VERSION ""

NS_ :

BS_:

BU_:

BO_ 2365402622 EJM5: 8 Vector__XXX
 SG_ Joystick5Button13PressedStatus : 62|2@1+ (1,0) [0|3] "" Vector__XXX
 SG_ Joystick5Button14PressedStatus : 60|2@1+ (1,0) [0|3] "" Vector__XXX
 SG_ Joystick5Button15PressedStatus : 58|2@1+ (1,0) [0|3] "" Vector__XXX
 SG_ Joystick5Button16PressedStatus : 56|2@1+ (1,0) [0|3] "" Vector__XXX
 SG_ Joystick5GripXAxisPosition : 6|10@1+ (0.1,0) [0|102] "%" Vector__XXX
 SG_ Joystick5GripYAxisPosition : 22|10@1+ (0.1,0) [0|102] "%" Vector__XXX
 SG_ Joystick5ThetaAxisPosition : 38|10@1+ (0.1,0) [0|102] "%" Vector__XXX
 SG_ Jst5GpYAxsLvFwdPstvPstStts : 20|2@1+ (1,0) [0|3] "" Vector__XXX
 SG_ Jst5TtAxsCtCwsNtvPstStts : 34|2@1+ (1,0) [0|3] "" Vector__XXX
 SG_ Jstk5GrpXAxsDtntPstnStts : 54|2@1+ (1,0) [0|3] "" Vector__XXX
 SG_ Jstk5GrpXAxsLvrLftNgtvPstnStts : 2|2@1+ (1,0) [0|3] "" Vector__XXX
 SG_ Jstk5GrpXAxsLvrRghtPstvPstnStts : 4|2@1+ (1,0) [0|3] "" Vector__XXX
 SG_ Jstk5GrpXAxsNtrlPstnStts : 0|2@1+ (1,0) [0|3] "" Vector__XXX
 SG_ Jstk5GrpYAxsDtntPstnStts : 52|2@1+ (1,0) [0|3] "" Vector__XXX
 SG_ Jstk5GrpYAxsLvrBkNgtvPstnStts : 18|2@1+ (1,0) [0|3] "" Vector__XXX
 SG_ Jstk5GrpYAxsNtrlPstnStts : 16|2@1+ (1,0) [0|3] "" Vector__XXX
 SG_ Jstk5ThtAxsClkwsPstvPstnStts : 36|2@1+ (1,0) [0|3] "" Vector__XXX
 SG_ Jstk5ThtAxsDtntPstnStts : 50|2@1+ (1,0) [0|3] "" Vector__XXX
 SG_ Jstk5ThtAxsNtrlPstnStts : 32|2@1+ (1,0) [0|3] "" Vector__XXX

BO_ 2365402878 BJM5: 8 Vector__XXX
 SG_ Joystick5Button10PressedStatus : 60|2@1+ (1,0) [0|3] "" Vector__XXX
 SG_ Joystick5Button11PressedStatus : 58|2@1+ (1,0) [0|3] "" Vector__XXX
 SG_ Joystick5Button12PressedStatus : 56|2@1+ (1,0) [0|3] "" Vector__XXX
 SG_ Joystick5Button1PressedStatus : 46|2@1+ (1,0) [0|3] "" Vector__XXX
 SG_ Joystick5Button2PressedStatus : 44|2@1+ (1,0) [0|3] "" Vector__XXX
 SG_ Joystick5Button3PressedStatus : 42|2@1+ (1,0) [0|3] "" Vector__XXX
 SG_ Joystick5Button4PressedStatus : 40|2@1+ (1,0) [0|3] "" Vector__XXX
 SG_ Joystick5Button5PressedStatus : 54|2@1+ (1,0) [0|3] "" Vector__XXX
 SG_ Joystick5Button6PressedStatus : 52|2@1+ (1,0) [0|3] "" Vector__XXX
 SG_ Joystick5Button7PressedStatus : 50|2@1+ (1,0) [0|3] "" Vector__XXX
 SG_ Joystick5Button8PressedStatus : 48|2@1+ (1,0) [0|3] "" Vector__XXX
 SG_ Joystick5Button9PressedStatus : 62|2@1+ (1,0) [0|3] "" Vector__XXX
 SG_ Joystick5XAxisPosition : 6|10@1+ (0.1,0) [0|102] "%" Vector__XXX
 SG_ Joystick5YAxisPosition : 22|10@1+ (0.1,0) [0|102] "%" Vector__XXX
 SG_ Jstk5XAxsDtntPstnStts : 38|2@1+ (1,0) [0|3] "" Vector__XXX
 SG_ Jstk5XAxsLvrLftNgtvPstnStts : 2|2@1+ (1,0) [0|3] "" Vector__XXX
 SG_ Jstk5XAxsLvrRghtPstvPstnStts : 4|2@1+ (1,0) [0|3] "" Vector__XXX
 SG_ Jstk5XAxsNtrlPstnStts : 0|2@1+ (1,0) [0|3] "" Vector__XXX
 SG_ Jstk5YAxsDtntPstnStts : 36|2@1+ (1,0) [0|3] "" Vector__XXX
 SG_ Jstk5YAxsLvrBkNgtvPstnStts : 18|2@1+ (1,0) [0|3] "" Vector__XXX
 SG_ Jstk5YAxsLvrFrwrdPstvPstnStts : 20|2@1+ (1,0) [0|3] "" Vector__XXX
 SG_ Jstk5YAxsNtrlPstnStts : 16|2@1+ (1,0) [0|3] "" Vector__XXX

BO_ 2365403134 EJM4: 8 Vector__XXX
 SG_ Joystick4Button13PressedStatus : 62|2@1+ (1,0) [0|3] "" Vector__XXX
 SG_ Joystick4Button14PressedStatus : 60|2@1+ (1,0) [0|3] "" Vector__XXX
 SG_ Joystick4Button15PressedStatus : 58|2@1+ (1,0) [0|3] "" Vector__XXX
 SG_ Joystick4Button16PressedStatus : 56|2@1+ (1,0) [0|3] "" Vector__XXX
 SG_ Joystick4GripXAxisPosition : 6|10@1+ (0.1,0) [0|102] "%" Vector__XXX
 SG_ Joystick4GripYAxisPosition : 22|10@1+ (0.1,0) [0|102] "%" Vector__XXX
 SG_ Joystick4ThetaAxisPosition : 38|10@1+ (0.1,0) [0|102] "%" Vector__XXX
 SG_ Jst4GpYAxsLvFwdPstvPstStts : 20|2@1+ (1,0) [0|3] "" Vector__XXX
 SG_ Jst4TtAxsCtCwsNtvPstStts : 34|2@1+ (1,0) [0|3] "" Vector__XXX
 SG_ Jstk4GrpXAxsDtntPstnStts : 54|2@1+ (1,0) [0|3] "" Vector__XXX
 SG_ Jstk4GrpXAxsLvrLftNgtvPstnStts : 2|2@1+ (1,0) [0|3] "" Vector__XXX
 SG_ Jstk4GrpXAxsLvrRghtPstvPstnStts : 4|2@1+ (1,0) [0|3] "" Vector__XXX
 SG_ Jstk4GrpXAxsNtrlPstnStts : 0|2@1+ (1,0) [0|3] "" Vector__XXX
 SG_ Jstk4GrpYAxsDtntPstnStts : 52|2@1+ (1,0) [0|3] "" Vector__XXX
 SG_ Jstk4GrpYAxsLvrBkNgtvPstnStts : 18|2@1+ (1,0) [0|3] "" Vector__XXX
 SG_ Jstk4GrpYAxsNtrlPstnStts : 16|2@1+ (1,0) [0|3] "" Vector__XXX
 SG_ Jstk4ThtAxsClkwsPstvPstnStts : 36|2@1+ (1,0) [0|3] "" Vector__XXX
 SG_ Jstk4ThtAxsDtntPstnStts : 50|2@1+ (1,0) [0|3] "" Vector__XXX
 SG_ Jstk4ThtAxsNtrlPstnStts : 32|2@1+ (1,0) [0|3] "" Vector__XXX

BO_ 2365403390 BJM4: 8 Vector__XXX
 SG_ Joystick4Button10PressedStatus : 60|2@1+ (1,0) [0|3] "" Vector__XXX
 SG_ Joystick4Button11PressedStatus : 58|2@1+ (1,0) [0|3] "" Vector__XXX
 SG_ Joystick4Button12PressedStatus : 56|2@1+ (1,0) [0|3] "" Vector__XXX
 SG_ Joystick4Button1PressedStatus : 46|2@1+ (1,0) [0|3] "" Vector__XXX
 SG_ Joystick4Button2PressedStatus : 44|2@1+ (1,0) [0|3] "" Vector__XXX
 SG_ Joystick4Button3PressedStatus : 42|2@1+ (1,0) [0|3] "" Vector__XXX
 SG_ Joystick4Button4PressedStatus : 40|2@1+ (1,0) [0|3] "" Vector__XXX
 SG_ Joystick4Button5PressedStatus : 54|2@1+ (1,0) [0|3] "" Vector__XXX
 SG_ Joystick4Button6PressedStatus : 52|2@1+ (1,0) [0|3] "" Vector__XXX
 SG_ Joystick4Button7PressedStatus : 50|2@1+ (1,0) [0|3] "" Vector__XXX
 SG_ Joystick4Button8PressedStatus : 48|2@1+ (1,0) [0|3] "" Vector__XXX
 SG_ Joystick4Button9PressedStatus : 62|2@1+ (1,0) [0|3] "" Vector__XXX
 SG_ Joystick4XAxisPosition : 6|10@1+ (0.1,0) [0|102] "%" Vector__XXX
 SG_ Joystick4YAxisPosition : 22|10@1+ (0.1,0) [0|102] "%" Vector__XXX
 SG_ Jstk4XAxsDtntPstnStts : 38|2@1+ (1,0) [0|3] "" Vector__XXX
 SG_ Jstk4XAxsLvrLftNgtvPstnStts : 2|2@1+ (1,0) [0|3] "" Vector__XXX
 SG_ Jstk4XAxsLvrRghtPstvPstnStts : 4|2@1+ (1,0) [0|3] "" Vector__XXX
 SG_ Jstk4XAxsNtrlPstnStts : 0|2@1+ (1,0) [0|3] "" Vector__XXX
 SG_ Jstk4YAxsDtntPstnStts : 36|2@1+ (1,0) [0|3] "" Vector__XXX
 SG_ Jstk4YAxsLvrBkNgtvPstnStts : 18|2@1+ (1,0) [0|3] "" Vector__XXX
 SG_ Jstk4YAxsLvrFrwrdPstvPstnStts : 20|2@1+ (1,0) [0|3] "" Vector__XXX
 SG_ Jstk4YAxsNtrlPstnStts : 16|2@1+ (1,0) [0|3] "" Vector__XXX

BO_ 2365428478 EOI: 8 Vector__XXX
 SG_ EngineControlledShutdownRequest : 42|2@1+ (1,0) [0|3] "" Vector__XXX
 SG_ EngineCoolantPumpControl : 40|2@1+ (1,0) [0|3] "" Vector__XXX
 SG_ EngineDerateRequest : 56|8@1+ (0.4,0) [0|100] "%" Vector__XXX
 SG_ EngineDesiredTorqueRequest : 48|8@1+ (1,-125) [-125|125] "%" Vector__XXX
 SG_ EngineFuelShutoff1Control : 26|2@1+ (1,0) [0|3] "" Vector__XXX
 SG_ EngineFuelShutoff2Control : 28|2@1+ (1,0) [0|3] "" Vector__XXX
 SG_ EngineFuelShutoffVentControl : 24|2@1+ (1,0) [0|3] "" Vector__XXX
 SG_ EngineOilPreheaterControl : 34|2@1+ (1,0) [0|3] "" Vector__XXX
 SG_ EngineOilPrimingPumpControl : 32|2@1+ (1,0) [0|3] "" Vector__XXX
 SG_ EngineOperatingState : 0|4@1+ (1,0) [0|15] "" Vector__XXX
 SG_ EnginePreHeaterControl : 38|2@1+ (1,0) [0|3] "" Vector__XXX
 SG_ EngineStarterMotorRelayControl : 6|2@1+ (1,0) [0|3] "" Vector__XXX
 SG_ EngnCldAmntElvtdIdlStts : 46|2@1+ (1,0) [0|3] "" Vector__XXX
 SG_ EngnEltrlSstmPwrCnsrvtnCntrl : 36|2@1+ (1,0) [0|3] "" Vector__XXX
 SG_ EngnEmrgnImmdtShtdwnIndtn : 44|2@1+ (1,0) [0|3] "" Vector__XXX
 SG_ EngnFlShtffVlvLkTstCntrl : 30|2@1+ (1,0) [0|3] "" Vector__XXX
 SG_ FuelPumpPrimerControl : 4|2@1+ (1,0) [0|3] "" Vector__XXX
 SG_ TmRmnngnEngnOprtngStt : 8|16@1+ (1,0) [0|64255] "s" Vector__XXX

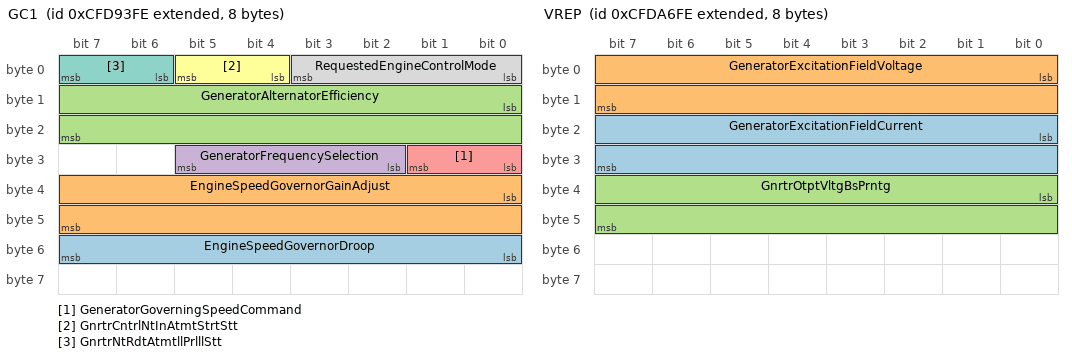
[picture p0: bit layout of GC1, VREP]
BO_ 2365428734 GC1: 8 Vector__XXX
 SG_ EngineSpeedGovernorDroop : 48|8@1+ (0.04,0) [0|10] "%" Vector__XXX
 SG_ EngineSpeedGovernorGainAdjust : 32|16@1+ (1,-32128) [-32128|32127] "count" Vector__XXX
 SG_ GeneratorAlternatorEfficiency : 8|16@1+ (0.0025,0) [0|160.6375] "%" Vector__XXX
 SG_ GeneratorFrequencySelection : 26|4@1+ (1,0) [0|15] "" Vector__XXX
 SG_ GeneratorGoverningSpeedCommand : 24|2@1+ (1,0) [0|3] "" Vector__XXX
 SG_ GnrtrCntrlNtInAtmtStrtStt : 4|2@1+ (1,0) [0|3] "" Vector__XXX
 SG_ GnrtrNtRdtAtmtllPrlllStt : 6|2@1+ (1,0) [0|3] "" Vector__XXX
 SG_ RequestedEngineControlMode : 0|4@1+ (1,0) [0|15] "" Vector__XXX

BO_ 2365433598 VREP: 8 Vector__XXX
 SG_ GeneratorExcitationFieldCurrent : 16|16@1+ (0.05,0) [0|3212.75] "A" Vector__XXX
 SG_ GeneratorExcitationFieldVoltage : 0|16@1+ (0.05,-1606) [-1606|1606.75] "V" Vector__XXX
 SG_ GnrtrOtptVltgBsPrntg : 32|16@1+ (0.1,-100) [-100|6325.5] "%" Vector__XXX

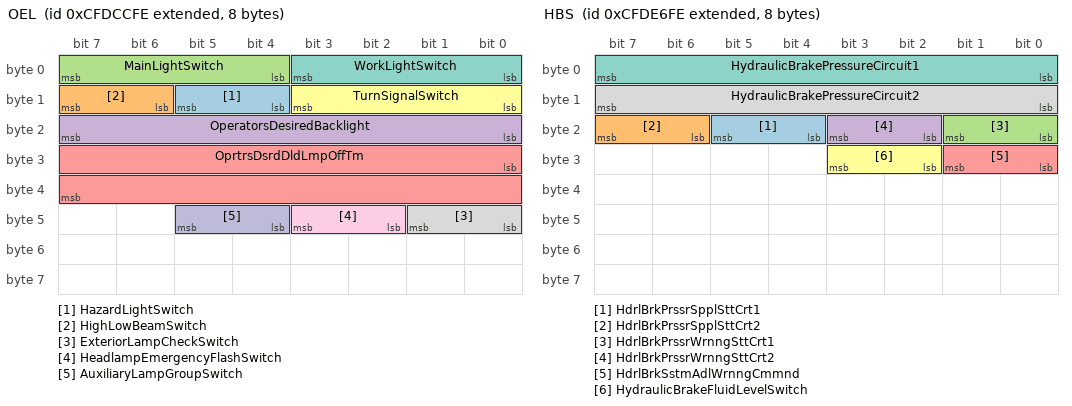
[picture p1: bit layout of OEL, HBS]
BO_ 2365443326 OEL: 8 Vector__XXX
 SG_ HazardLightSwitch : 12|2@1+ (1,0) [0|3] "" Vector__XXX
 SG_ HighLowBeamSwitch : 14|2@1+ (1,0) [0|3] "" Vector__XXX
 SG_ MainLightSwitch : 4|4@1+ (1,0) [0|15] "" Vector__XXX
 SG_ OperatorsDesiredBacklight : 16|8@1+ (0.4,0) [0|100] "%" Vector__XXX
 SG_ OprtrsDsrdDldLmpOffTm : 24|16@1+ (1,0) [0|64255] "s" Vector__XXX
 SG_ TurnSignalSwitch : 8|4@1+ (1,0) [0|15] "" Vector__XXX
 SG_ WorkLightSwitch : 0|4@1+ (1,0) [0|15] "" Vector__XXX
 SG_ ExteriorLampCheckSwitch : 40|2@1+ (1,0) [0|3] "" Vector__XXX
 SG_ HeadlampEmergencyFlashSwitch : 42|2@1+ (1,0) [0|3] "" Vector__XXX
 SG_ AuxiliaryLampGroupSwitch : 44|2@1+ (1,0) [0|3] "" Vector__XXX

BO_ 2365445886 BJM1: 8 Vector__XXX
 SG_ Joystick1Button10PressedStatus : 60|2@1+ (1,0) [0|3] "" Vector__XXX
 SG_ Joystick1Button11PressedStatus : 58|2@1+ (1,0) [0|3] "" Vector__XXX
 SG_ Joystick1Button12PressedStatus : 56|2@1+ (1,0) [0|3] "" Vector__XXX
 SG_ Joystick1Button1PressedStatus : 46|2@1+ (1,0) [0|3] "" Vector__XXX
 SG_ Joystick1Button2PressedStatus : 44|2@1+ (1,0) [0|3] "" Vector__XXX
 SG_ Joystick1Button3PressedStatus : 42|2@1+ (1,0) [0|3] "" Vector__XXX
 SG_ Joystick1Button4PressedStatus : 40|2@1+ (1,0) [0|3] "" Vector__XXX
 SG_ Joystick1Button5PressedStatus : 54|2@1+ (1,0) [0|3] "" Vector__XXX
 SG_ Joystick1Button6PressedStatus : 52|2@1+ (1,0) [0|3] "" Vector__XXX
 SG_ Joystick1Button7PressedStatus : 50|2@1+ (1,0) [0|3] "" Vector__XXX
 SG_ Joystick1Button8PressedStatus : 48|2@1+ (1,0) [0|3] "" Vector__XXX
 SG_ Joystick1Button9PressedStatus : 62|2@1+ (1,0) [0|3] "" Vector__XXX
 SG_ Joystick1XAxisPosition : 6|10@1+ (0.1,0) [0|102] "%" Vector__XXX
 SG_ Joystick1YAxisPosition : 22|10@1+ (0.1,0) [0|102] "%" Vector__XXX
 SG_ Jstk1XAxsDtntPstnStts : 38|2@1+ (1,0) [0|3] "" Vector__XXX
 SG_ Jstk1XAxsLvrLftNgtvPstnStts : 2|2@1+ (1,0) [0|3] "" Vector__XXX
 SG_ Jstk1XAxsLvrRghtPstvPstnStts : 4|2@1+ (1,0) [0|3] "" Vector__XXX
 SG_ Jstk1XAxsNtrlPstnStts : 0|2@1+ (1,0) [0|3] "" Vector__XXX
 SG_ Jstk1YAxsDtntPstnStts : 36|2@1+ (1,0) [0|3] "" Vector__XXX
 SG_ Jstk1YAxsLvrBkNgtvPstnStts : 18|2@1+ (1,0) [0|3] "" Vector__XXX
 SG_ Jstk1YAxsLvrFrwrdPstvPstnStts : 20|2@1+ (1,0) [0|3] "" Vector__XXX
 SG_ Jstk1YAxsNtrlPstnStts : 16|2@1+ (1,0) [0|3] "" Vector__XXX

BO_ 2365446142 EJM1: 8 Vector__XXX
 SG_ Joystick1Button13PressedStatus : 62|2@1+ (1,0) [0|3] "" Vector__XXX
 SG_ Joystick1Button14PressedStatus : 60|2@1+ (1,0) [0|3] "" Vector__XXX
 SG_ Joystick1Button15PressedStatus : 58|2@1+ (1,0) [0|3] "" Vector__XXX
 SG_ Joystick1Button16PressedStatus : 56|2@1+ (1,0) [0|3] "" Vector__XXX
 SG_ Joystick1GripXAxisPosition : 6|10@1+ (0.1,0) [0|102] "%" Vector__XXX
 SG_ Joystick1GripYAxisPosition : 22|10@1+ (0.1,0) [0|102] "%" Vector__XXX
 SG_ Joystick1ThetaAxisPosition : 38|10@1+ (0.1,0) [0|102] "%" Vector__XXX
 SG_ Jst1GpYAxsLvFwdPstvPstStts : 20|2@1+ (1,0) [0|3] "" Vector__XXX
 SG_ Jst1TtAxsCtCwsNtvPstStts : 34|2@1+ (1,0) [0|3] "" Vector__XXX
 SG_ Jstk1GrpXAxsDtntPstnStts : 54|2@1+ (1,0) [0|3] "" Vector__XXX
 SG_ Jstk1GrpXAxsLvrLftNgtvPstnStts : 2|2@1+ (1,0) [0|3] "" Vector__XXX
 SG_ Jstk1GrpXAxsLvrRghtPstvPstnStts : 4|2@1+ (1,0) [0|3] "" Vector__XXX
 SG_ Jstk1GrpXAxsNtrlPstnStts : 0|2@1+ (1,0) [0|3] "" Vector__XXX
 SG_ Jstk1GrpYAxsDtntPstnStts : 52|2@1+ (1,0) [0|3] "" Vector__XXX
 SG_ Jstk1GrpYAxsLvrBkNgtvPstnStts : 18|2@1+ (1,0) [0|3] "" Vector__XXX
 SG_ Jstk1GrpYAxsNtrlPstnStts : 16|2@1+ (1,0) [0|3] "" Vector__XXX
 SG_ Jstk1ThtAxsClkwsPstvPstnStts : 36|2@1+ (1,0) [0|3] "" Vector__XXX
 SG_ Jstk1ThtAxsDtntPstnStts : 50|2@1+ (1,0) [0|3] "" Vector__XXX
 SG_ Jstk1ThtAxsNtrlPstnStts : 32|2@1+ (1,0) [0|3] "" Vector__XXX

BO_ 2365446398 BJM2: 8 Vector__XXX
 SG_ Joystick2Button10PressedStatus : 60|2@1+ (1,0) [0|3] "" Vector__XXX
 SG_ Joystick2Button11PressedStatus : 58|2@1+ (1,0) [0|3] "" Vector__XXX
 SG_ Joystick2Button12PressedStatus : 56|2@1+ (1,0) [0|3] "" Vector__XXX
 SG_ Joystick2Button1PressedStatus : 46|2@1+ (1,0) [0|3] "" Vector__XXX
 SG_ Joystick2Button2PressedStatus : 44|2@1+ (1,0) [0|3] "" Vector__XXX
 SG_ Joystick2Button3PressedStatus : 42|2@1+ (1,0) [0|3] "" Vector__XXX
 SG_ Joystick2Button4PressedStatus : 40|2@1+ (1,0) [0|3] "" Vector__XXX
 SG_ Joystick2Button5PressedStatus : 54|2@1+ (1,0) [0|3] "" Vector__XXX
 SG_ Joystick2Button6PressedStatus : 52|2@1+ (1,0) [0|3] "" Vector__XXX
 SG_ Joystick2Button7PressedStatus : 50|2@1+ (1,0) [0|3] "" Vector__XXX
 SG_ Joystick2Button8PressedStatus : 48|2@1+ (1,0) [0|3] "" Vector__XXX
 SG_ Joystick2Button9PressedStatus : 62|2@1+ (1,0) [0|3] "" Vector__XXX
 SG_ Joystick2XAxisPosition : 6|10@1+ (0.1,0) [0|102] "%" Vector__XXX
 SG_ Joystick2YAxisPosition : 22|10@1+ (0.1,0) [0|102] "%" Vector__XXX
 SG_ Jstk2XAxsDtntPstnStts : 38|2@1+ (1,0) [0|3] "" Vector__XXX
 SG_ Jstk2XAxsLvrLftNgtvPstnStts : 2|2@1+ (1,0) [0|3] "" Vector__XXX
 SG_ Jstk2XAxsLvrRghtPstvPstnStts : 4|2@1+ (1,0) [0|3] "" Vector__XXX
 SG_ Jstk2XAxsNtrlPstnStts : 0|2@1+ (1,0) [0|3] "" Vector__XXX
 SG_ Jstk2YAxsDtntPstnStts : 36|2@1+ (1,0) [0|3] "" Vector__XXX
 SG_ Jstk2YAxsLvrBkNgtvPstnStts : 18|2@1+ (1,0) [0|3] "" Vector__XXX
 SG_ Jstk2YAxsLvrFrwrdPstvPstnStts : 20|2@1+ (1,0) [0|3] "" Vector__XXX
 SG_ Jstk2YAxsNtrlPstnStts : 16|2@1+ (1,0) [0|3] "" Vector__XXX

BO_ 2365446654 EJM2: 8 Vector__XXX
 SG_ Joystick2Button13PressedStatus : 62|2@1+ (1,0) [0|3] "" Vector__XXX
 SG_ Joystick2Button14PressedStatus : 60|2@1+ (1,0) [0|3] "" Vector__XXX
 SG_ Joystick2Button15PressedStatus : 58|2@1+ (1,0) [0|3] "" Vector__XXX
 SG_ Joystick2Button16PressedStatus : 56|2@1+ (1,0) [0|3] "" Vector__XXX
 SG_ Joystick2GripXAxisPosition : 6|10@1+ (0.1,0) [0|102] "%" Vector__XXX
 SG_ Joystick2GripYAxisPosition : 22|10@1+ (0.1,0) [0|102] "%" Vector__XXX
 SG_ Joystick2ThetaAxisPosition : 38|10@1+ (0.1,0) [0|102] "%" Vector__XXX
 SG_ Jst2GpYAxsLvFwdPstvPstStts : 20|2@1+ (1,0) [0|3] "" Vector__XXX
 SG_ Jst2TtAxsCtCwsNtvPstStts : 34|2@1+ (1,0) [0|3] "" Vector__XXX
 SG_ Jstk2GrpXAxsDtntPstnStts : 54|2@1+ (1,0) [0|3] "" Vector__XXX
 SG_ Jstk2GrpXAxsLvrLftNgtvPstnStts : 2|2@1+ (1,0) [0|3] "" Vector__XXX
 SG_ Jstk2GrpXAxsLvrRghtPstvPstnStts : 4|2@1+ (1,0) [0|3] "" Vector__XXX
 SG_ Jstk2GrpXAxsNtrlPstnStts : 0|2@1+ (1,0) [0|3] "" Vector__XXX
 SG_ Jstk2GrpYAxsDtntPstnStts : 52|2@1+ (1,0) [0|3] "" Vector__XXX
 SG_ Jstk2GrpYAxsLvrBkNgtvPstnStts : 18|2@1+ (1,0) [0|3] "" Vector__XXX
 SG_ Jstk2GrpYAxsNtrlPstnStts : 16|2@1+ (1,0) [0|3] "" Vector__XXX
 SG_ Jstk2ThtAxsClkwsPstvPstnStts : 36|2@1+ (1,0) [0|3] "" Vector__XXX
 SG_ Jstk2ThtAxsDtntPstnStts : 50|2@1+ (1,0) [0|3] "" Vector__XXX
 SG_ Jstk2ThtAxsNtrlPstnStts : 32|2@1+ (1,0) [0|3] "" Vector__XXX

BO_ 2365446910 BJM3: 8 Vector__XXX
 SG_ Joystick3Button10PressedStatus : 60|2@1+ (1,0) [0|3] "" Vector__XXX
 SG_ Joystick3Button11PressedStatus : 58|2@1+ (1,0) [0|3] "" Vector__XXX
 SG_ Joystick3Button12PressedStatus : 56|2@1+ (1,0) [0|3] "" Vector__XXX
 SG_ Joystick3Button1PressedStatus : 46|2@1+ (1,0) [0|3] "" Vector__XXX
 SG_ Joystick3Button2PressedStatus : 44|2@1+ (1,0) [0|3] "" Vector__XXX
 SG_ Joystick3Button3PressedStatus : 42|2@1+ (1,0) [0|3] "" Vector__XXX
 SG_ Joystick3Button4PressedStatus : 40|2@1+ (1,0) [0|3] "" Vector__XXX
 SG_ Joystick3Button5PressedStatus : 54|2@1+ (1,0) [0|3] "" Vector__XXX
 SG_ Joystick3Button6PressedStatus : 52|2@1+ (1,0) [0|3] "" Vector__XXX
 SG_ Joystick3Button7PressedStatus : 50|2@1+ (1,0) [0|3] "" Vector__XXX
 SG_ Joystick3Button8PressedStatus : 48|2@1+ (1,0) [0|3] "" Vector__XXX
 SG_ Joystick3Button9PressedStatus : 62|2@1+ (1,0) [0|3] "" Vector__XXX
 SG_ Joystick3XAxisPosition : 6|10@1+ (0.1,0) [0|102] "%" Vector__XXX
 SG_ Joystick3YAxisPosition : 22|10@1+ (0.1,0) [0|102] "%" Vector__XXX
 SG_ Jstk3XAxsDtntPstnStts : 38|2@1+ (1,0) [0|3] "" Vector__XXX
 SG_ Jstk3XAxsLvrLftNgtvPstnStts : 2|2@1+ (1,0) [0|3] "" Vector__XXX
 SG_ Jstk3XAxsLvrRghtPstvPstnStts : 4|2@1+ (1,0) [0|3] "" Vector__XXX
 SG_ Jstk3XAxsNtrlPstnStts : 0|2@1+ (1,0) [0|3] "" Vector__XXX
 SG_ Jstk3YAxsDtntPstnStts : 36|2@1+ (1,0) [0|3] "" Vector__XXX
 SG_ Jstk3YAxsLvrBkNgtvPstnStts : 18|2@1+ (1,0) [0|3] "" Vector__XXX
 SG_ Jstk3YAxsLvrFrwrdPstvPstnStts : 20|2@1+ (1,0) [0|3] "" Vector__XXX
 SG_ Jstk3YAxsNtrlPstnStts : 16|2@1+ (1,0) [0|3] "" Vector__XXX

BO_ 2365447166 EJM3: 8 Vector__XXX
 SG_ Joystick3Button13PressedStatus : 62|2@1+ (1,0) [0|3] "" Vector__XXX
 SG_ Joystick3Button14PressedStatus : 60|2@1+ (1,0) [0|3] "" Vector__XXX
 SG_ Joystick3Button15PressedStatus : 58|2@1+ (1,0) [0|3] "" Vector__XXX
 SG_ Joystick3Button16PressedStatus : 56|2@1+ (1,0) [0|3] "" Vector__XXX
 SG_ Joystick3GripXAxisPosition : 6|10@1+ (0.1,0) [0|102] "%" Vector__XXX
 SG_ Joystick3GripYAxisPosition : 22|10@1+ (0.1,0) [0|102] "%" Vector__XXX
 SG_ Joystick3ThetaAxisPosition : 38|10@1+ (0.1,0) [0|102] "%" Vector__XXX
 SG_ Jst3GpYAxsLvFwdPstvPstStts : 20|2@1+ (1,0) [0|3] "" Vector__XXX
 SG_ Jst3TtAxsCtCwsNtvPstStts : 34|2@1+ (1,0) [0|3] "" Vector__XXX
 SG_ Jstk3GrpXAxsDtntPstnStts : 54|2@1+ (1,0) [0|3] "" Vector__XXX
 SG_ Jstk3GrpXAxsLvrLftNgtvPstnStts : 2|2@1+ (1,0) [0|3] "" Vector__XXX
 SG_ Jstk3GrpXAxsLvrRghtPstvPstnStts : 4|2@1+ (1,0) [0|3] "" Vector__XXX
 SG_ Jstk3GrpXAxsNtrlPstnStts : 0|2@1+ (1,0) [0|3] "" Vector__XXX
 SG_ Jstk3GrpYAxsDtntPstnStts : 52|2@1+ (1,0) [0|3] "" Vector__XXX
 SG_ Jstk3GrpYAxsLvrBkNgtvPstnStts : 18|2@1+ (1,0) [0|3] "" Vector__XXX
 SG_ Jstk3GrpYAxsNtrlPstnStts : 16|2@1+ (1,0) [0|3] "" Vector__XXX
 SG_ Jstk3ThtAxsClkwsPstvPstnStts : 36|2@1+ (1,0) [0|3] "" Vector__XXX
 SG_ Jstk3ThtAxsDtntPstnStts : 50|2@1+ (1,0) [0|3] "" Vector__XXX
 SG_ Jstk3ThtAxsNtrlPstnStts : 32|2@1+ (1,0) [0|3] "" Vector__XXX

BO_ 2365449982 HBS: 8 Vector__XXX
 SG_ HdrlBrkPrssrSpplSttCrt1 : 20|2@1+ (1,0) [0|3] "" Vector__XXX
 SG_ HdrlBrkPrssrSpplSttCrt2 : 22|2@1+ (1,0) [0|3] "" Vector__XXX
 SG_ HdrlBrkPrssrWrnngSttCrt1 : 16|2@1+ (1,0) [0|3] "" Vector__XXX
 SG_ HdrlBrkPrssrWrnngSttCrt2 : 18|2@1+ (1,0) [0|3] "" Vector__XXX
 SG_ HdrlBrkSstmAdlWrnngCmmnd : 24|2@1+ (1,0) [0|3] "" Vector__XXX
 SG_ HydraulicBrakeFluidLevelSwitch : 26|2@1+ (1,0) [0|3] "" Vector__XXX
 SG_ HydraulicBrakePressureCircuit1 : 0|8@1+ (100,0) [0|25000] "kPa" Vector__XXX
 SG_ HydraulicBrakePressureCircuit2 : 8|8@1+ (100,0) [0|25000] "kPa" Vector__XXX

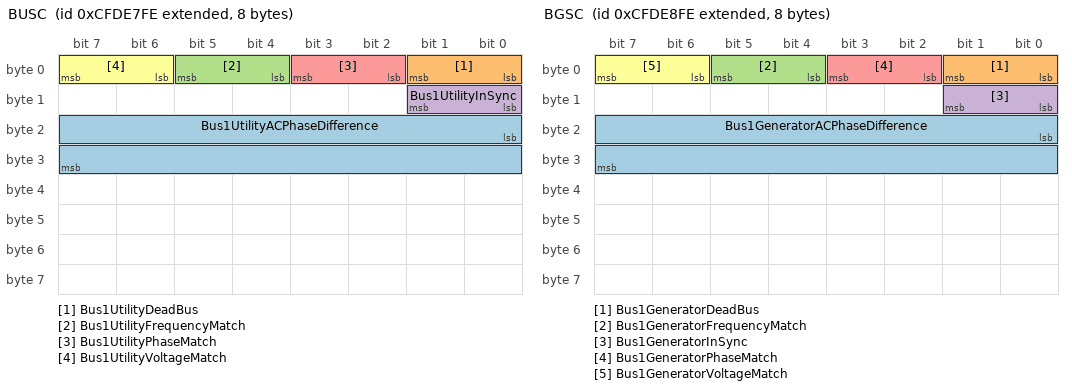
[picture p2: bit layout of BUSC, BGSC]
BO_ 2365450238 BUSC: 8 Vector__XXX
 SG_ Bus1UtilityACPhaseDifference : 16|16@1+ (0.0078125,-200) [-200|301.99] "deg" Vector__XXX
 SG_ Bus1UtilityDeadBus : 0|2@1+ (1,0) [0|3] "" Vector__XXX
 SG_ Bus1UtilityFrequencyMatch : 4|2@1+ (1,0) [0|3] "" Vector__XXX
 SG_ Bus1UtilityInSync : 8|2@1+ (1,0) [0|3] "" Vector__XXX
 SG_ Bus1UtilityPhaseMatch : 2|2@1+ (1,0) [0|3] "" Vector__XXX
 SG_ Bus1UtilityVoltageMatch : 6|2@1+ (1,0) [0|3] "" Vector__XXX

BO_ 2365450494 BGSC: 8 Vector__XXX
 SG_ Bus1GeneratorACPhaseDifference : 16|16@1+ (0.0078125,-200) [-200|301.99] "deg" Vector__XXX
 SG_ Bus1GeneratorDeadBus : 0|2@1+ (1,0) [0|3] "" Vector__XXX
 SG_ Bus1GeneratorFrequencyMatch : 4|2@1+ (1,0) [0|3] "" Vector__XXX
 SG_ Bus1GeneratorInSync : 8|2@1+ (1,0) [0|3] "" Vector__XXX
 SG_ Bus1GeneratorPhaseMatch : 2|2@1+ (1,0) [0|3] "" Vector__XXX
 SG_ Bus1GeneratorVoltageMatch : 6|2@1+ (1,0) [0|3] "" Vector__XXX

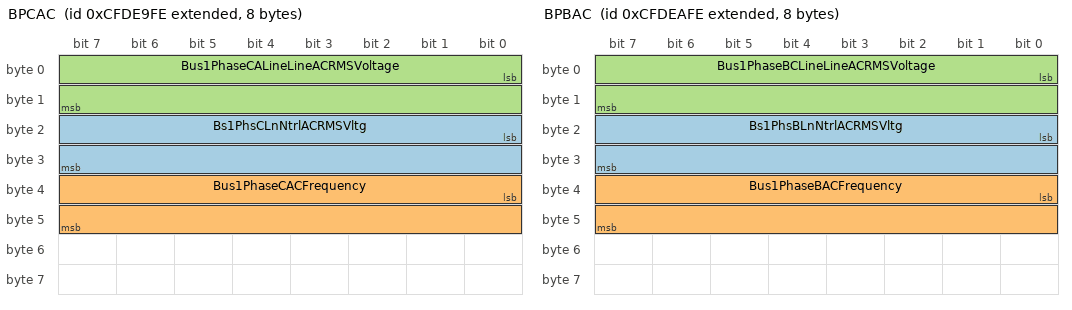
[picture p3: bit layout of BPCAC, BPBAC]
BO_ 2365450750 BPCAC: 8 Vector__XXX
 SG_ Bs1PhsCLnNtrlACRMSVltg : 16|16@1+ (1,0) [0|64255] "V" Vector__XXX
 SG_ Bus1PhaseCACFrequency : 32|16@1+ (0.0078125,0) [0|501.9921875] "Hz" Vector__XXX
 SG_ Bus1PhaseCALineLineACRMSVoltage : 0|16@1+ (1,0) [0|64255] "V" Vector__XXX

BO_ 2365451006 BPBAC: 8 Vector__XXX
 SG_ Bs1PhsBLnNtrlACRMSVltg : 16|16@1+ (1,0) [0|64255] "V" Vector__XXX
 SG_ Bus1PhaseBACFrequency : 32|16@1+ (0.0078125,0) [0|501.9921875] "Hz" Vector__XXX
 SG_ Bus1PhaseBCLineLineACRMSVoltage : 0|16@1+ (1,0) [0|64255] "V" Vector__XXX

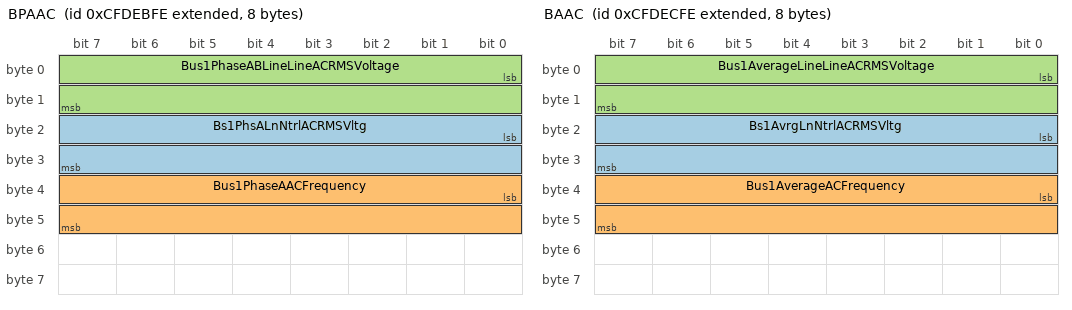
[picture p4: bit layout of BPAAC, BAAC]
BO_ 2365451262 BPAAC: 8 Vector__XXX
 SG_ Bs1PhsALnNtrlACRMSVltg : 16|16@1+ (1,0) [0|64255] "V" Vector__XXX
 SG_ Bus1PhaseAACFrequency : 32|16@1+ (0.0078125,0) [0|501.9921875] "Hz" Vector__XXX
 SG_ Bus1PhaseABLineLineACRMSVoltage : 0|16@1+ (1,0) [0|64255] "V" Vector__XXX

BO_ 2365451518 BAAC: 8 Vector__XXX
 SG_ Bs1AvrgLnNtrlACRMSVltg : 16|16@1+ (1,0) [0|64255] "V" Vector__XXX
 SG_ Bus1AverageACFrequency : 32|16@1+ (0.0078125,0) [0|501.9921875] "Hz" Vector__XXX
 SG_ Bus1AverageLineLineACRMSVoltage : 0|16@1+ (1,0) [0|64255] "V" Vector__XXX

BO_ 2365451774 UTACE: 8 Vector__XXX
 SG_ UtilityTotalkWHoursExport : 0|32@1+ (1,0) [0|4211081215] "kWh" Vector__XXX
 SG_ UtilityTotalkWHoursImport : 32|32@1+ (1,0) [0|4211081215] "kWh" Vector__XXX

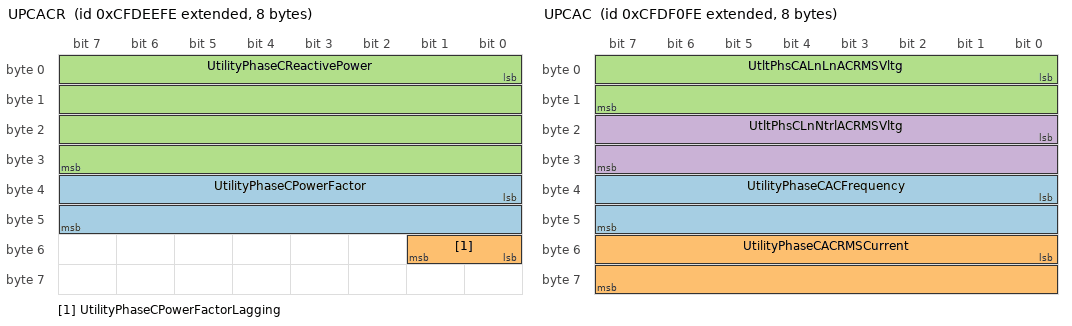
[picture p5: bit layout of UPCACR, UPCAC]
BO_ 2365452030 UPCACR: 8 Vector__XXX
 SG_ UtilityPhaseCPowerFactor : 32|16@1+ (0.00006103515625,-1) [-1|2.921814] "" Vector__XXX
 SG_ UtilityPhaseCPowerFactorLagging : 48|2@1+ (1,0) [0|3] "" Vector__XXX
 SG_ UtilityPhaseCReactivePower : 0|32@1+ (1,-2000000000) [-2000000000|2211081215] "VAr" Vector__XXX

BO_ 2365452286 UPCACP: 8 Vector__XXX
 SG_ UtilityPhaseCApparentPower : 32|32@1+ (1,-2000000000) [-2000000000|2211081215] "VA" Vector__XXX
 SG_ UtilityPhaseCRealPower : 0|32@1+ (1,-2000000000) [-2000000000|2211081215] "W" Vector__XXX

BO_ 2365452542 UPCAC: 8 Vector__XXX
 SG_ UtilityPhaseCACFrequency : 32|16@1+ (0.0078125,0) [0|501.9921875] "Hz" Vector__XXX
 SG_ UtilityPhaseCACRMSCurrent : 48|16@1+ (1,0) [0|64255] "A" Vector__XXX
 SG_ UtltPhsCALnLnACRMSVltg : 0|16@1+ (1,0) [0|64255] "V" Vector__XXX
 SG_ UtltPhsCLnNtrlACRMSVltg : 16|16@1+ (1,0) [0|64255] "V" Vector__XXX

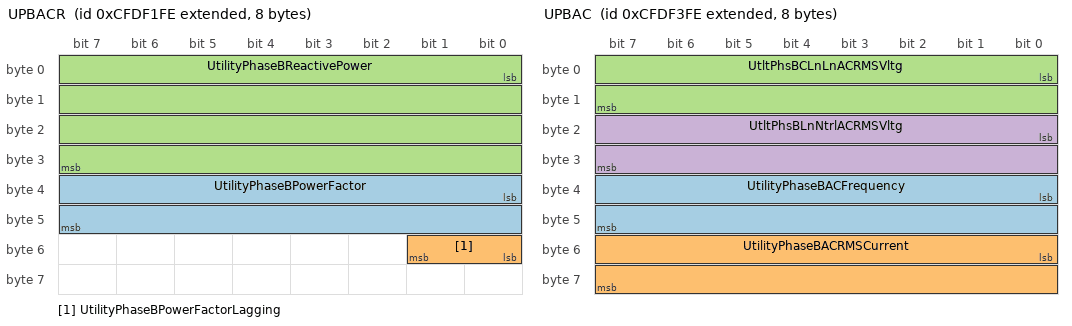
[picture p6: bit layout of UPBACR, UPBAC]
BO_ 2365452798 UPBACR: 8 Vector__XXX
 SG_ UtilityPhaseBPowerFactor : 32|16@1+ (0.00006103515625,-1) [-1|2.921814] "" Vector__XXX
 SG_ UtilityPhaseBPowerFactorLagging : 48|2@1+ (1,0) [0|3] "" Vector__XXX
 SG_ UtilityPhaseBReactivePower : 0|32@1+ (1,-2000000000) [-2000000000|2211081215] "VAr" Vector__XXX

BO_ 2365453054 UPBACP: 8 Vector__XXX
 SG_ UtilityPhaseBApparentPower : 32|32@1+ (1,-2000000000) [-2000000000|2211081215] "VA" Vector__XXX
 SG_ UtilityPhaseBRealPower : 0|32@1+ (1,-2000000000) [-2000000000|2211081215] "W" Vector__XXX

BO_ 2365453310 UPBAC: 8 Vector__XXX
 SG_ UtilityPhaseBACFrequency : 32|16@1+ (0.0078125,0) [0|501.9921875] "Hz" Vector__XXX
 SG_ UtilityPhaseBACRMSCurrent : 48|16@1+ (1,0) [0|64255] "A" Vector__XXX
 SG_ UtltPhsBCLnLnACRMSVltg : 0|16@1+ (1,0) [0|64255] "V" Vector__XXX
 SG_ UtltPhsBLnNtrlACRMSVltg : 16|16@1+ (1,0) [0|64255] "V" Vector__XXX

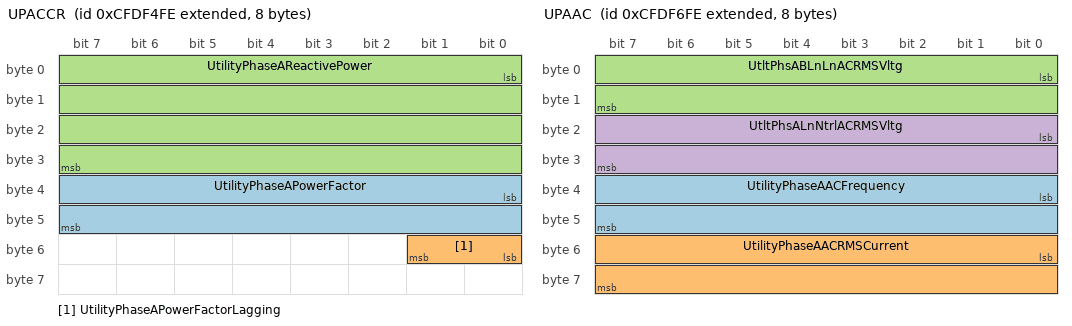
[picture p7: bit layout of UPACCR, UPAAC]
BO_ 2365453566 UPACCR: 8 Vector__XXX
 SG_ UtilityPhaseAPowerFactor : 32|16@1+ (0.00006103515625,-1) [-1|2.921814] "" Vector__XXX
 SG_ UtilityPhaseAPowerFactorLagging : 48|2@1+ (1,0) [0|3] "" Vector__XXX
 SG_ UtilityPhaseAReactivePower : 0|32@1+ (1,-2000000000) [-2000000000|2211081215] "VAr" Vector__XXX

BO_ 2365453822 UPAACP: 8 Vector__XXX
 SG_ UtilityPhaseAApparentPower : 32|32@1+ (1,-2000000000) [-2000000000|2211081215] "VA" Vector__XXX
 SG_ UtilityPhaseARealPower : 0|32@1+ (1,-2000000000) [-2000000000|2211081215] "W" Vector__XXX

BO_ 2365454078 UPAAC: 8 Vector__XXX
 SG_ UtilityPhaseAACFrequency : 32|16@1+ (0.0078125,0) [0|501.9921875] "Hz" Vector__XXX
 SG_ UtilityPhaseAACRMSCurrent : 48|16@1+ (1,0) [0|64255] "A" Vector__XXX
 SG_ UtltPhsABLnLnACRMSVltg : 0|16@1+ (1,0) [0|64255] "V" Vector__XXX
 SG_ UtltPhsALnNtrlACRMSVltg : 16|16@1+ (1,0) [0|64255] "V" Vector__XXX

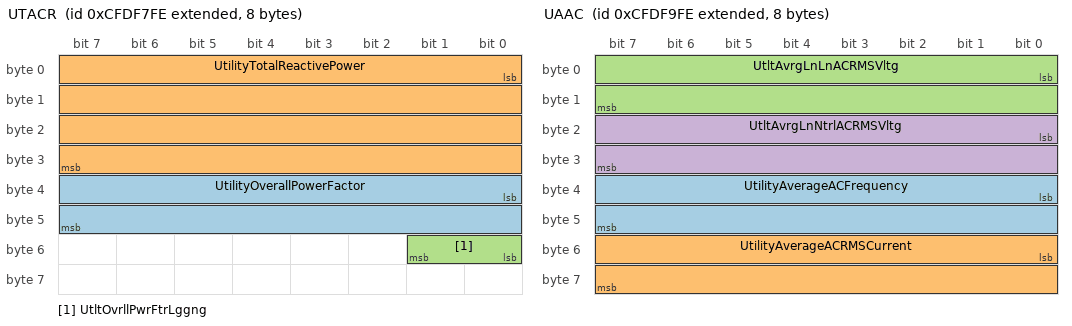
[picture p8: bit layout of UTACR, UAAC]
BO_ 2365454334 UTACR: 8 Vector__XXX
 SG_ UtilityOverallPowerFactor : 32|16@1+ (0.00006103515625,-1) [-1|2.921814] "" Vector__XXX
 SG_ UtilityTotalReactivePower : 0|32@1+ (1,-2000000000) [-2000000000|2211081215] "VAr" Vector__XXX
 SG_ UtltOvrllPwrFtrLggng : 48|2@1+ (1,0) [0|3] "" Vector__XXX

BO_ 2365454590 UTACP: 8 Vector__XXX
 SG_ UtilityTotalApparentPower : 32|32@1+ (1,-2000000000) [-2000000000|2211081215] "VA" Vector__XXX
 SG_ UtilityTotalRealPower : 0|32@1+ (1,-2000000000) [-2000000000|2211081215] "W" Vector__XXX

BO_ 2365454846 UAAC: 8 Vector__XXX
 SG_ UtilityAverageACFrequency : 32|16@1+ (0.0078125,0) [0|501.9921875] "Hz" Vector__XXX
 SG_ UtilityAverageACRMSCurrent : 48|16@1+ (1,0) [0|64255] "A" Vector__XXX
 SG_ UtltAvrgLnLnACRMSVltg : 0|16@1+ (1,0) [0|64255] "V" Vector__XXX
 SG_ UtltAvrgLnNtrlACRMSVltg : 16|16@1+ (1,0) [0|64255] "V" Vector__XXX

BO_ 2365455102 GTACE: 8 Vector__XXX
 SG_ GeneratorTotalkWHoursExport : 0|32@1+ (1,0) [0|4211081215] "kWh" Vector__XXX
 SG_ GeneratorTotalkWHoursImport : 32|32@1+ (1,0) [0|4211081215] "kWh" Vector__XXX

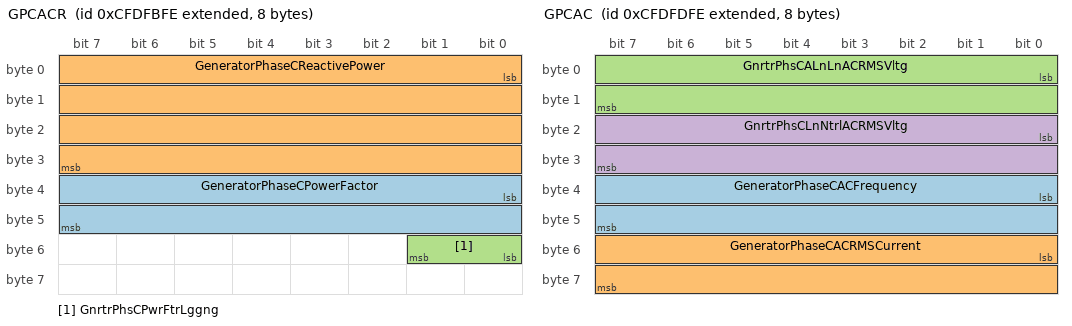
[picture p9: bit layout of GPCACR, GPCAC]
BO_ 2365455358 GPCACR: 8 Vector__XXX
 SG_ GeneratorPhaseCPowerFactor : 32|16@1+ (0.00006103515625,-1) [-1|2.921814] "" Vector__XXX
 SG_ GeneratorPhaseCReactivePower : 0|32@1+ (1,-2000000000) [-2000000000|2211081215] "VAr" Vector__XXX
 SG_ GnrtrPhsCPwrFtrLggng : 48|2@1+ (1,0) [0|3] "" Vector__XXX

BO_ 2365455614 GPCACP: 8 Vector__XXX
 SG_ GeneratorPhaseCApparentPower : 32|32@1+ (1,-2000000000) [-2000000000|2211081215] "VA" Vector__XXX
 SG_ GeneratorPhaseCRealPower : 0|32@1+ (1,-2000000000) [-2000000000|2211081215] "W" Vector__XXX

BO_ 2365455870 GPCAC: 8 Vector__XXX
 SG_ GeneratorPhaseCACFrequency : 32|16@1+ (0.0078125,0) [0|501.9921875] "Hz" Vector__XXX
 SG_ GeneratorPhaseCACRMSCurrent : 48|16@1+ (1,0) [0|64255] "A" Vector__XXX
 SG_ GnrtrPhsCALnLnACRMSVltg : 0|16@1+ (1,0) [0|64255] "V" Vector__XXX
 SG_ GnrtrPhsCLnNtrlACRMSVltg : 16|16@1+ (1,0) [0|64255] "V" Vector__XXX

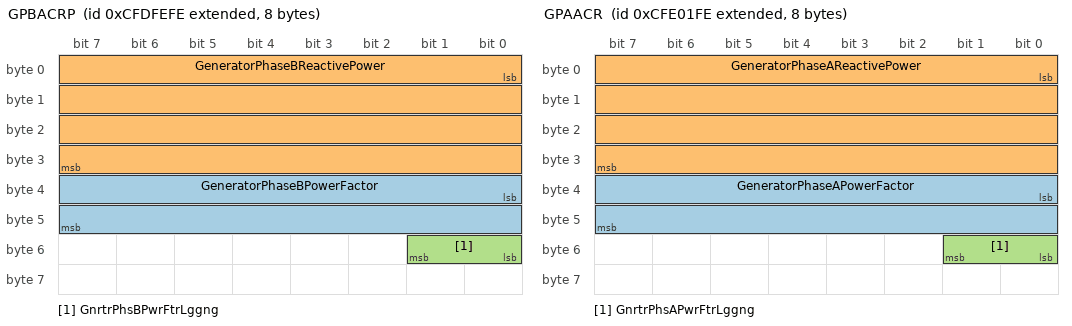
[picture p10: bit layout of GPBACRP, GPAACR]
BO_ 2365456126 GPBACRP: 8 Vector__XXX
 SG_ GeneratorPhaseBPowerFactor : 32|16@1+ (0.00006103515625,-1) [-1|2.921814] "" Vector__XXX
 SG_ GeneratorPhaseBReactivePower : 0|32@1+ (1,-2000000000) [-2000000000|2211081215] "VAr" Vector__XXX
 SG_ GnrtrPhsBPwrFtrLggng : 48|2@1+ (1,0) [0|3] "" Vector__XXX

BO_ 2365456382 GPBACP: 8 Vector__XXX
 SG_ GeneratorPhaseBApparentPower : 32|32@1+ (1,-2000000000) [-2000000000|2211081215] "VA" Vector__XXX
 SG_ GeneratorPhaseBRealPower : 0|32@1+ (1,-2000000000) [-2000000000|2211081215] "W" Vector__XXX

BO_ 2365456894 GPAACR: 8 Vector__XXX
 SG_ GeneratorPhaseAPowerFactor : 32|16@1+ (0.00006103515625,-1) [-1|2.921814] "" Vector__XXX
 SG_ GeneratorPhaseAReactivePower : 0|32@1+ (1,-2000000000) [-2000000000|2211081215] "VAr" Vector__XXX
 SG_ GnrtrPhsAPwrFtrLggng : 48|2@1+ (1,0) [0|3] "" Vector__XXX

BO_ 2365457150 GPAACP: 8 Vector__XXX
 SG_ GeneratorPhaseAApparentPower : 32|32@1+ (1,-2000000000) [-2000000000|2211081215] "VA" Vector__XXX
 SG_ GeneratorPhaseARealPower : 0|32@1+ (1,-2000000000) [-2000000000|2211081215] "W" Vector__XXX

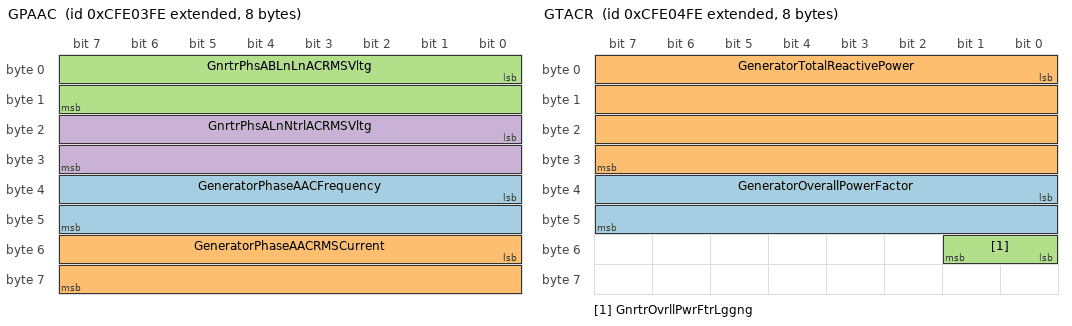
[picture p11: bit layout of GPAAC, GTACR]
BO_ 2365457406 GPAAC: 8 Vector__XXX
 SG_ GeneratorPhaseAACFrequency : 32|16@1+ (0.0078125,0) [0|501.9921875] "Hz" Vector__XXX
 SG_ GeneratorPhaseAACRMSCurrent : 48|16@1+ (1,0) [0|64255] "A" Vector__XXX
 SG_ GnrtrPhsABLnLnACRMSVltg : 0|16@1+ (1,0) [0|64255] "V" Vector__XXX
 SG_ GnrtrPhsALnNtrlACRMSVltg : 16|16@1+ (1,0) [0|64255] "V" Vector__XXX

BO_ 2365457662 GTACR: 8 Vector__XXX
 SG_ GeneratorOverallPowerFactor : 32|16@1+ (0.00006103515625,-1) [-1|2.921814] "" Vector__XXX
 SG_ GeneratorTotalReactivePower : 0|32@1+ (1,-2000000000) [-2000000000|2211081215] "VAr" Vector__XXX
 SG_ GnrtrOvrllPwrFtrLggng : 48|2@1+ (1,0) [0|3] "" Vector__XXX

BO_ 2365457918 GTACP: 8 Vector__XXX
 SG_ GeneratorTotalApparentPower : 32|32@1+ (1,-2000000000) [-2000000000|2211081215] "VA" Vector__XXX
 SG_ GeneratorTotalRealPower : 0|32@1+ (1,-2000000000) [-2000000000|2211081215] "W" Vector__XXX

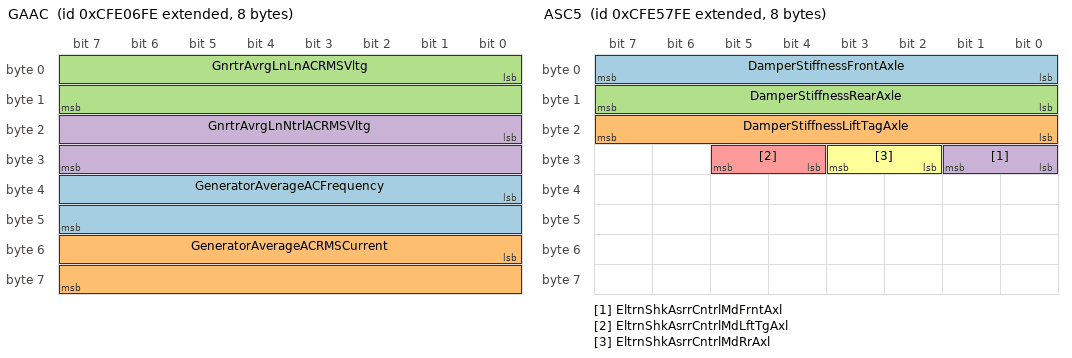
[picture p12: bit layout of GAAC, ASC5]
BO_ 2365458174 GAAC: 8 Vector__XXX
 SG_ GeneratorAverageACFrequency : 32|16@1+ (0.0078125,0) [0|501.9921875] "Hz" Vector__XXX
 SG_ GeneratorAverageACRMSCurrent : 48|16@1+ (1,0) [0|64255] "A" Vector__XXX
 SG_ GnrtrAvrgLnLnACRMSVltg : 0|16@1+ (1,0) [0|64255] "V" Vector__XXX
 SG_ GnrtrAvrgLnNtrlACRMSVltg : 16|16@1+ (1,0) [0|64255] "V" Vector__XXX

BO_ 2365473278 LCMD: 8 Vector__XXX
 SG_ AlternateBeamHeadLightCommand : 2|2@1+ (1,0) [0|3] "" Vector__XXX
 SG_ BackUpLightandAlarmHornCommand : 16|2@1+ (1,0) [0|3] "" Vector__XXX
 SG_ CenterStopLightCommand : 18|2@1+ (1,0) [0|3] "" Vector__XXX
 SG_ HighBeamHeadLightCommand : 6|2@1+ (1,0) [0|3] "" Vector__XXX
 SG_ ImplementClearanceLightCommand : 24|2@1+ (1,0) [0|3] "" Vector__XXX
 SG_ ImplementMarkerLightCommand : 28|2@1+ (1,0) [0|3] "" Vector__XXX
 SG_ ImplementOEMOption1LightCommand : 50|2@1+ (1,0) [0|3] "" Vector__XXX
 SG_ ImplementOEMOption2LightCommand : 48|2@1+ (1,0) [0|3] "" Vector__XXX
 SG_ ImplementRearWorkLightCommand : 62|2@1+ (1,0) [0|3] "" Vector__XXX
 SG_ ImplmntLftFngWrkLghtCmmnd : 60|2@1+ (1,0) [0|3] "" Vector__XXX
 SG_ ImplmntLftFrwrdWrkLghtCmmnd : 54|2@1+ (1,0) [0|3] "" Vector__XXX
 SG_ ImplmntRghtFngWrkLghtCmmnd : 52|2@1+ (1,0) [0|3] "" Vector__XXX
 SG_ ImplmntRghtFrwrdWrkLghtCmmnd : 58|2@1+ (1,0) [0|3] "" Vector__XXX
 SG_ LeftStopLightCommand : 22|2@1+ (1,0) [0|3] "" Vector__XXX
 SG_ LeftTurnSignalLightsCommand : 14|2@1+ (1,0) [0|3] "" Vector__XXX
 SG_ LightingDataRequestCommand : 56|2@1+ (1,0) [0|3] "" Vector__XXX
 SG_ LowBeamHeadLightCommand : 4|2@1+ (1,0) [0|3] "" Vector__XXX
 SG_ RearFogLightCommand : 32|2@1+ (1,0) [0|3] "" Vector__XXX
 SG_ RightStopLightCommand : 20|2@1+ (1,0) [0|3] "" Vector__XXX
 SG_ RightTurnSignalLightsCommand : 12|2@1+ (1,0) [0|3] "" Vector__XXX
 SG_ RotatingBeaconLightCommand : 10|2@1+ (1,0) [0|3] "" Vector__XXX
 SG_ RunningLightCommand : 0|2@1+ (1,0) [0|3] "" Vector__XXX
 SG_ TractorClearanceLightCommand : 26|2@1+ (1,0) [0|3] "" Vector__XXX
 SG_ TractorFrontFogLightsCommand : 8|2@1+ (1,0) [0|3] "" Vector__XXX
 SG_ TractorMarkerLightCommand : 30|2@1+ (1,0) [0|3] "" Vector__XXX
 SG_ TrtrFrntHghMntdWrkLghtsCmmnd : 46|2@1+ (1,0) [0|3] "" Vector__XXX
 SG_ TrtrFrntLwMntdWrkLghtsCmmnd : 44|2@1+ (1,0) [0|3] "" Vector__XXX
 SG_ TrtrRrHghMntdWrkLghtsCmmnd : 38|2@1+ (1,0) [0|3] "" Vector__XXX
 SG_ TrtrRrLwMntdWrkLghtsCmmnd : 36|2@1+ (1,0) [0|3] "" Vector__XXX
 SG_ TrtrSdHghMntdWrkLghtsCmmnd : 42|2@1+ (1,0) [0|3] "" Vector__XXX
 SG_ TrtrSdLwMntdWrkLghtsCmmnd : 40|2@1+ (1,0) [0|3] "" Vector__XXX
 SG_ TrtrUndrsdMntdWrkLghtsCmmnd : 34|2@1+ (1,0) [0|3] "" Vector__XXX

BO_ 2365478910 ASC5: 8 Vector__XXX
 SG_ DamperStiffnessFrontAxle : 0|8@1+ (0.4,0) [0|100] "%" Vector__XXX
 SG_ DamperStiffnessLiftTagAxle : 16|8@1+ (0.4,0) [0|100] "%" Vector__XXX
 SG_ DamperStiffnessRearAxle : 8|8@1+ (0.4,0) [0|100] "%" Vector__XXX
 SG_ EltrnShkAsrrCntrlMdFrntAxl : 24|2@1+ (1,0) [0|3] "" Vector__XXX
 SG_ EltrnShkAsrrCntrlMdLftTgAxl : 28|2@1+ (1,0) [0|3] "" Vector__XXX
 SG_ EltrnShkAsrrCntrlMdRrAxl : 26|2@1+ (1,0) [0|3] "" Vector__XXX

BO_ 2365479678 ASC1: 8 Vector__XXX
 SG_ AboveNominalLevelFrontAxle : 12|2@1+ (1,0) [0|3] "" Vector__XXX
 SG_ AboveNominalLevelRearAxle : 14|2@1+ (1,0) [0|3] "" Vector__XXX
 SG_ AllwLvlCntrlDrngBrkngStts : 52|2@1+ (1,0) [0|3] "" Vector__XXX
 SG_ BelowNominalLevelFrontAxle : 8|2@1+ (1,0) [0|3] "" Vector__XXX
 SG_ BelowNominalLevelRearAxle : 10|2@1+ (1,0) [0|3] "" Vector__XXX
 SG_ DoorRelease : 36|2@1+ (1,0) [0|3] "" Vector__XXX
 SG_ FrontAxleinBumperRange : 40|2@1+ (1,0) [0|3] "" Vector__XXX
 SG_ KneelingInformation : 24|4@1+ (1,0) [0|15] "" Vector__XXX
 SG_ LevelControlMode : 28|4@1+ (1,0) [0|15] "" Vector__XXX
 SG_ LiftAxle1Position : 38|2@1+ (1,0) [0|3] "" Vector__XXX
 SG_ LiftAxle2Position : 46|2@1+ (1,0) [0|3] "" Vector__XXX
 SG_ LiftingControlModeFrontAxle : 20|2@1+ (1,0) [0|3] "" Vector__XXX
 SG_ LiftingControlModeRearAxle : 22|2@1+ (1,0) [0|3] "" Vector__XXX
 SG_ LoweringControlModeFrontAxle : 16|2@1+ (1,0) [0|3] "" Vector__XXX
 SG_ LoweringControlModeRearAxle : 18|2@1+ (1,0) [0|3] "" Vector__XXX
 SG_ Memorylevel : 60|4@1+ (1,0) [0|15] "" Vector__XXX
 SG_ NominalLevelFrontAxle : 0|4@1+ (1,0) [0|15] "" Vector__XXX
 SG_ NominalLevelRearAxle : 4|4@1+ (1,0) [0|15] "" Vector__XXX
 SG_ RearAxleinBumperRange : 42|2@1+ (1,0) [0|3] "" Vector__XXX
 SG_ SecurityDevice : 32|2@1+ (1,0) [0|3] "" Vector__XXX
 SG_ SpdDpndntLvlCntrlStts : 54|2@1+ (1,0) [0|3] "" Vector__XXX
 SG_ SspnsnCntrlRfslInfrmtn : 56|4@1+ (1,0) [0|15] "" Vector__XXX
 SG_ SuspensionRemoteControl1 : 48|2@1+ (1,0) [0|3] "" Vector__XXX
 SG_ SuspensionRemotecontrol2 : 50|2@1+ (1,0) [0|3] "" Vector__XXX
 SG_ VehicleMotionInhibit : 34|2@1+ (1,0) [0|3] "" Vector__XXX

CM_ BO_ 2365402622 "Extended Joystick Message 5";
CM_ SG_ 2365402622 Joystick5Button13PressedStatus "Joystick 5 Button 13 Pressed Status: Reports when the joystick button has been pressed.00b = Button not pressed01b = Button pressed10b = Error Indicator11b = Not Available";
CM_ SG_ 2365402622 Joystick5Button14PressedStatus "Joystick 5 Button 14 Pressed Status: Reports when the joystick button has been pressed.00b = Button not pressed01b = Button pressed10b = Error Indicator11b = Not Available";
CM_ SG_ 2365402622 Joystick5Button15PressedStatus "Joystick 5 Button 15 Pressed Status: Reports when the joystick button has been pressed.00b = Button not pressed01b = Button pressed10b = Error Indicator11b = Not Available";
CM_ SG_ 2365402622 Joystick5Button16PressedStatus "Joystick 5 Button 16 Pressed Status: Reports when the joystick button has been pressed.00b = Button not pressed01b = Button pressed10b = Error Indicator11b = Not Available";
CM_ SG_ 2365402622 Joystick5GripXAxisPosition "Joystick 5 Grip X-Axis Position: The position of the joystick grip in the relative motion of travel from the neutral position.  Position value of 0 is Neutral and position value 1000 (100%) is the end of linear zone.  Value of 1022 indicates an error...";
CM_ SG_ 2365402622 Joystick5GripYAxisPosition "Joystick 5 Grip Y-Axis Position: The position of the joystick grip in the relative motion of travel from the neutral position.  Position value of 0 is Neutral and position value 1000 (100%) is the end of linear zone.  Value of 1022 indicates an error...";
CM_ SG_ 2365402622 Joystick5ThetaAxisPosition "Joystick 5 Theta-Axis Position: The position of the joystick in the relative motion of travel from the neutral position.  Position value of 0 is Neutral and position value 1000 (100%) is the end of linear zone.  Value of 1022 indicates an error has o...";
CM_ SG_ 2365402622 Jst5GpYAxsLvFwdPstvPstStts "Joystick 5 Grip Y-Axis Lever Forward Positive Position Status: Reports when the current joystick grip position is on the positive travel side (forward, right, clockwise, up) relative to the neutral position for that axis of travel. 00b = Not on Posit...";
CM_ SG_ 2365402622 Jst5TtAxsCtCwsNtvPstStts "Joystick 5 Theta-Axis Counter Clockwise Negative Position Status: Reports when the current joystick position is on the negative travel side (back, left, counterclockwise, down) relative to the neutral position for that axis of travel. 00b = Not on ne...";
CM_ SG_ 2365402622 Jstk5GrpXAxsDtntPstnStts "Joystick 5 Grip X-Axis Detent Position Status: Reports when the current joystick grip position is in the detent position for that axis of travel.00b = Not in the Detent Position01b = In the Detent Position10b = Error Indicator11b = Not Available...";
CM_ SG_ 2365402622 Jstk5GrpXAxsLvrLftNgtvPstnStts "Joystick 5 Grip X-Axis Lever Left Negative Position Status: Reports when the current joystick grip position is on the negative travel side (back, left, counterclockwise, down) relative to the neutral position for that axis of travel. 00b = Not on neg...";
CM_ SG_ 2365402622 Jstk5GrpXAxsLvrRghtPstvPstnStts "Joystick 5 Grip X-Axis Lever Right Positive Position Status: Reports when the current joystick grip position is on the positive travel side (forward, right, clockwise, up) relative to the neutral position for that axis of travel. 00b = Not on Positiv...";
CM_ SG_ 2365402622 Jstk5GrpXAxsNtrlPstnStts "Joystick 5 Grip X-Axis Neutral Position Status: Reports when the current joystick grip position is in the neutral position for that axis of travel.  The neutral position measurement must be determined from some mechanism other than the axis position ...";
CM_ SG_ 2365402622 Jstk5GrpYAxsDtntPstnStts "Joystick 5 Grip Y-Axis Detent Position Status: Reports when the current joystick grip position is in the detent position for that axis of travel.00b = Not in the Detent Position01b = In the Detent Position10b = Error Indicator11b = Not Available...";
CM_ SG_ 2365402622 Jstk5GrpYAxsLvrBkNgtvPstnStts "Joystick 5 Grip Y-Axis Lever Back Negative Position Status: Reports when the current joystick grip position is on the negative travel side (back, left, counterclockwise, down) relative to the neutral position for that axis of travel. 00b = Not on neg...";
CM_ SG_ 2365402622 Jstk5GrpYAxsNtrlPstnStts "Joystick 5 Grip Y-Axis Neutral Position Status: Reports when the current joystick grip position is in the neutral position for that axis of travel.  The neutral position measurement must be determined from some mechanism other than the axis position ...";
CM_ SG_ 2365402622 Jstk5ThtAxsClkwsPstvPstnStts "Joystick 5 Theta-Axis Clockwise Positive Position Status: Reports when the current joystick position is on the positive travel side (forward, right, clockwise, up) relative to the neutral position for that axis of travel. 00b = Not on Positive side o...";
CM_ SG_ 2365402622 Jstk5ThtAxsDtntPstnStts "Joystick 5 Theta-Axis Detent Position Status: Reports when the current joystick position is in the detent position for that axis of travel.00b = Not in the Detent Position01b = In the Detent Position10b = Error Indicator11b = Not Available";
CM_ SG_ 2365402622 Jstk5ThtAxsNtrlPstnStts "Joystick 5 Theta-Axis Neutral Position Status: Reports when the current joystick position is in the neutral position for that axis of travel.  The neutral position measurement must be determined from some mechanism other than the axis position measur...";
CM_ BO_ 2365402878 "Basic Joystick Message 5";
CM_ SG_ 2365402878 Joystick5Button10PressedStatus "Joystick 5 Button 10 Pressed Status: Reports when the joystick button has been pressed.00b = Button not pressed01b = Button pressed10b = Error Indicator11b = Not Available";
CM_ SG_ 2365402878 Joystick5Button11PressedStatus "Joystick 5 Button 11 Pressed Status: Reports when the joystick button has been pressed.00b = Button not pressed01b = Button pressed10b = Error Indicator11b = Not Available";
CM_ SG_ 2365402878 Joystick5Button12PressedStatus "Joystick 5 Button 12 Pressed Status: Reports when the joystick button has been pressed.00b = Button not pressed01b = Button pressed10b = Error Indicator11b = Not Available";
CM_ SG_ 2365402878 Joystick5Button1PressedStatus "Joystick 5 Button 1 Pressed Status: Reports when the joystick button has been pressed.00b = Button not pressed01b = Button pressed10b = Error Indicator11b = Not Available";
CM_ SG_ 2365402878 Joystick5Button2PressedStatus "Joystick 5 Button 2 Pressed Status: Reports when the joystick button has been pressed.00b = Button not pressed01b = Button pressed10b = Error Indicator11b = Not Available";
CM_ SG_ 2365402878 Joystick5Button3PressedStatus "Joystick 5 Button 3 Pressed Status: Reports when the joystick button has been pressed.00b = Button not pressed01b = Button pressed10b = Error Indicator11b = Not Available";
CM_ SG_ 2365402878 Joystick5Button4PressedStatus "Joystick 5 Button 4 Pressed Status: Reports when the joystick button has been pressed.00b = Button not pressed01b = Button pressed10b = Error Indicator11b = Not Available";
CM_ SG_ 2365402878 Joystick5Button5PressedStatus "Joystick 5 Button 5 Pressed Status: Reports when the joystick button has been pressed.00b = Button not pressed01b = Button pressed10b = Error Indicator11b = Not Available";
CM_ SG_ 2365402878 Joystick5Button6PressedStatus "Joystick 5 Button 6 Pressed Status: Reports when the joystick button has been pressed.00b = Button not pressed01b = Button pressed10b = Error Indicator11b = Not Available";
CM_ SG_ 2365402878 Joystick5Button7PressedStatus "Joystick 5 Button 7 Pressed Status: Reports when the joystick button has been pressed.00b = Button not pressed01b = Button pressed10b = Error Indicator11b = Not Available";
CM_ SG_ 2365402878 Joystick5Button8PressedStatus "Joystick 5 Button 8 Pressed Status: Reports when the joystick button has been pressed.00b = Button not pressed01b = Button pressed10b = Error Indicator11b = Not Available";
CM_ SG_ 2365402878 Joystick5Button9PressedStatus "Joystick 5 Button 9 Pressed Status: Reports when the joystick button has been pressed.00b = Button not pressed01b = Button pressed10b = Error Indicator11b = Not Available";
CM_ SG_ 2365402878 Joystick5XAxisPosition "Joystick 5 X-Axis Position: The position of the joystick in the relative motion of travel from the neutral position.  Position value of 0 is Neutral and position value 1000 (100%) is the end of linear zone.  Value of 1022 indicates an error has occur...";
CM_ SG_ 2365402878 Joystick5YAxisPosition "Joystick 5 Y-Axis Position: The position of the joystick in the relative motion of travel from the neutral position.  Position value of 0 is Neutral and position value 1000 (100%) is the end of linear zone.  Value of 1022 indicates an error has occur...";
CM_ SG_ 2365402878 Jstk5XAxsDtntPstnStts "Joystick 5 X-Axis Detent Position Status: Reports when the current joystick position is in the detent position for that axis of travel.00b = Not in the Detent Position01b = In the Detent Position10b = Error Indicator11b = Not Available";
CM_ SG_ 2365402878 Jstk5XAxsLvrLftNgtvPstnStts "Joystick 5 X-Axis Lever Left Negative Position Status: Reports when the current joystick position is on the negative travel side (back, left, counterclockwise, down) relative to the neutral position for that axis of travel. 00b = Not on negative side...";
CM_ SG_ 2365402878 Jstk5XAxsLvrRghtPstvPstnStts "Joystick 5 X-Axis Lever Right Positive Position Status: Reports when the current joystick position is on the positive travel side (forward, right, clockwise, up) relative to the neutral position for that axis of travel. 00b = Not on Positive side of ...";
CM_ SG_ 2365402878 Jstk5XAxsNtrlPstnStts "Joystick 5 X-Axis Neutral Position Status: Reports when the current joystick position is in the neutral position for that axis of travel.  The neutral position measurement must be determined from some mechanism other than the axis position measuremen...";
CM_ SG_ 2365402878 Jstk5YAxsDtntPstnStts "Joystick 5 Y-Axis Detent Position Status: Reports when the current joystick position is in the detent position for that axis of travel.00b = Not in the Detent Position01b = In the Detent Position10b = Error Indicator11b = Not Available";
CM_ SG_ 2365402878 Jstk5YAxsLvrBkNgtvPstnStts "Joystick 5 Y-Axis Lever Back Negative Position Status: Reports when the current joystick position is on the negative travel side (back, left, counterclockwise, down) relative to the neutral position for that axis of travel. 00b = Not on negative side...";
CM_ SG_ 2365402878 Jstk5YAxsLvrFrwrdPstvPstnStts "Joystick 5 Y-Axis Lever Forward Positive Position Status: Reports when the current joystick position is on the positive travel side (forward, right, clockwise, up) relative to the neutral position for that axis of travel. 00b = Not on Positive side o...";
CM_ SG_ 2365402878 Jstk5YAxsNtrlPstnStts "Joystick 5 Y-Axis Neutral Position Status: Reports when the current joystick position is in the neutral position for that axis of travel.  The neutral position measurement must be determined from some mechanism other than the axis position measuremen...";
CM_ BO_ 2365403134 "Extended Joystick Message 4";
CM_ SG_ 2365403134 Joystick4Button13PressedStatus "Joystick 4 Button 13 Pressed Status: Reports when the joystick button has been pressed.00b = Button not pressed01b = Button pressed10b = Error Indicator11b = Not Available";
CM_ SG_ 2365403134 Joystick4Button14PressedStatus "Joystick 4 Button 14 Pressed Status: Reports when the joystick button has been pressed.00b = Button not pressed01b = Button pressed10b = Error Indicator11b = Not Available";
CM_ SG_ 2365403134 Joystick4Button15PressedStatus "Joystick 4 Button 15 Pressed Status: Reports when the joystick button has been pressed.00b = Button not pressed01b = Button pressed10b = Error Indicator11b = Not Available";
CM_ SG_ 2365403134 Joystick4Button16PressedStatus "Joystick 4 Button 16 Pressed Status: Reports when the joystick button has been pressed.00b = Button not pressed01b = Button pressed10b = Error Indicator11b = Not Available";
CM_ SG_ 2365403134 Joystick4GripXAxisPosition "Joystick 4 Grip X-Axis Position: The position of the joystick grip in the relative motion of travel from the neutral position.  Position value of 0 is Neutral and position value 1000 (100%) is the end of linear zone.  Value of 1022 indicates an error...";
CM_ SG_ 2365403134 Joystick4GripYAxisPosition "Joystick 4 Grip Y-Axis Position: The position of the joystick grip in the relative motion of travel from the neutral position.  Position value of 0 is Neutral and position value 1000 (100%) is the end of linear zone.  Value of 1022 indicates an error...";
CM_ SG_ 2365403134 Joystick4ThetaAxisPosition "Joystick 4 Theta-Axis Position: The position of the joystick in the relative motion of travel from the neutral position.  Position value of 0 is Neutral and position value 1000 (100%) is the end of linear zone.  Value of 1022 indicates an error has o...";
CM_ SG_ 2365403134 Jst4GpYAxsLvFwdPstvPstStts "Joystick 4 Grip Y-Axis Lever Forward Positive Position Status: Reports when the current joystick grip position is on the positive travel side (forward, right, clockwise, up) relative to the neutral position for that axis of travel. 00b = Not on Posit...";
CM_ SG_ 2365403134 Jst4TtAxsCtCwsNtvPstStts "Joystick 4 Theta-Axis Counter Clockwise Negative Position Status: Reports when the current joystick position is on the negative travel side (back, left, counterclockwise, down) relative to the neutral position for that axis of travel. 00b = Not on ne...";
CM_ SG_ 2365403134 Jstk4GrpXAxsDtntPstnStts "Joystick 4 Grip X-Axis Detent Position Status: Reports when the current joystick grip position is in the detent position for that axis of travel.00b = Not in the Detent Position01b = In the Detent Position10b = Error Indicator11b = Not Available...";
CM_ SG_ 2365403134 Jstk4GrpXAxsLvrLftNgtvPstnStts "Joystick 4 Grip X-Axis Lever Left Negative Position Status: Reports when the current joystick grip position is on the negative travel side (back, left, counterclockwise, down) relative to the neutral position for that axis of travel. 00b = Not on neg...";
CM_ SG_ 2365403134 Jstk4GrpXAxsLvrRghtPstvPstnStts "Joystick 4 Grip X-Axis Lever Right Positive Position Status: Reports when the current joystick grip position is on the positive travel side (forward, right, clockwise, up) relative to the neutral position for that axis of travel. 00b = Not on Positiv...";
CM_ SG_ 2365403134 Jstk4GrpXAxsNtrlPstnStts "Joystick 4 Grip X-Axis Neutral Position Status: Reports when the current joystick grip position is in the neutral position for that axis of travel.  The neutral position measurement must be determined from some mechanism other than the axis position ...";
CM_ SG_ 2365403134 Jstk4GrpYAxsDtntPstnStts "Joystick 4 Grip Y-Axis Detent Position Status: Reports when the current joystick grip position is in the detent position for that axis of travel.00b = Not in the Detent Position01b = In the Detent Position10b = Error Indicator11b = Not Available...";
CM_ SG_ 2365403134 Jstk4GrpYAxsLvrBkNgtvPstnStts "Joystick 4 Grip Y-Axis Lever Back Negative Position Status: Reports when the current joystick grip position is on the negative travel side (back, left, counterclockwise, down) relative to the neutral position for that axis of travel. 00b = Not on neg...";
CM_ SG_ 2365403134 Jstk4GrpYAxsNtrlPstnStts "Joystick 4 Grip Y-Axis Neutral Position Status: Reports when the current joystick grip position is in the neutral position for that axis of travel.  The neutral position measurement must be determined from some mechanism other than the axis position ...";
CM_ SG_ 2365403134 Jstk4ThtAxsClkwsPstvPstnStts "Joystick 4 Theta-Axis Clockwise Positive Position Status: Reports when the current joystick position is on the positive travel side (forward, right, clockwise, up) relative to the neutral position for that axis of travel. 00b = Not on Positive side o...";
CM_ SG_ 2365403134 Jstk4ThtAxsDtntPstnStts "Joystick 4 Theta-Axis Detent Position Status: Reports when the current joystick position is in the detent position for that axis of travel.00b = Not in the Detent Position01b = In the Detent Position10b = Error Indicator11b = Not Available";
CM_ SG_ 2365403134 Jstk4ThtAxsNtrlPstnStts "Joystick 4 Theta-Axis Neutral Position Status: Reports when the current joystick position is in the neutral position for that axis of travel.  The neutral position measurement must be determined from some mechanism other than the axis position measur...";
CM_ BO_ 2365403390 "Basic Joystick Message 4";
CM_ SG_ 2365403390 Joystick4Button10PressedStatus "Joystick 4 Button 10 Pressed Status: Reports when the joystick button has been pressed.00b = Button not pressed01b = Button pressed10b = Error Indicator11b = Not Available";
CM_ SG_ 2365403390 Joystick4Button11PressedStatus "Joystick 4 Button 11 Pressed Status: Reports when the joystick button has been pressed.00b = Button not pressed01b = Button pressed10b = Error Indicator11b = Not Available";
CM_ SG_ 2365403390 Joystick4Button12PressedStatus "Joystick 4 Button 12 Pressed Status: Reports when the joystick button has been pressed.00b = Button not pressed01b = Button pressed10b = Error Indicator11b = Not Available";
CM_ SG_ 2365403390 Joystick4Button1PressedStatus "Joystick 4 Button 1 Pressed Status: Reports when the joystick button has been pressed.00b = Button not pressed01b = Button pressed10b = Error Indicator11b = Not Available";
CM_ SG_ 2365403390 Joystick4Button2PressedStatus "Joystick 4 Button 2 Pressed Status: Reports when the joystick button has been pressed.00b = Button not pressed01b = Button pressed10b = Error Indicator11b = Not Available";
CM_ SG_ 2365403390 Joystick4Button3PressedStatus "Joystick 4 Button 3 Pressed Status: Reports when the joystick button has been pressed.00b = Button not pressed01b = Button pressed10b = Error Indicator11b = Not Available";
CM_ SG_ 2365403390 Joystick4Button4PressedStatus "Joystick 4 Button 4 Pressed Status: Reports when the joystick button has been pressed.00b = Button not pressed01b = Button pressed10b = Error Indicator11b = Not Available";
CM_ SG_ 2365403390 Joystick4Button5PressedStatus "Joystick 4 Button 5 Pressed Status: Reports when the joystick button has been pressed.00b = Button not pressed01b = Button pressed10b = Error Indicator11b = Not Available";
CM_ SG_ 2365403390 Joystick4Button6PressedStatus "Joystick 4 Button 6 Pressed Status: Reports when the joystick button has been pressed.00b = Button not pressed01b = Button pressed10b = Error Indicator11b = Not Available";
CM_ SG_ 2365403390 Joystick4Button7PressedStatus "Joystick 4 Button 7 Pressed Status: Reports when the joystick button has been pressed.00b = Button not pressed01b = Button pressed10b = Error Indicator11b = Not Available";
CM_ SG_ 2365403390 Joystick4Button8PressedStatus "Joystick 4 Button 8 Pressed Status: Reports when the joystick button has been pressed.00b = Button not pressed01b = Button pressed10b = Error Indicator11b = Not Available";
CM_ SG_ 2365403390 Joystick4Button9PressedStatus "Joystick 4 Button 9 Pressed Status: Reports when the joystick button has been pressed.00b = Button not pressed01b = Button pressed10b = Error Indicator11b = Not Available";
CM_ SG_ 2365403390 Joystick4XAxisPosition "Joystick 4 X-Axis Position: The position of the joystick in the relative motion of travel from the neutral position.  Position value of 0 is Neutral and position value 1000 (100%) is the end of linear zone.  Value of 1022 indicates an error has occur...";
CM_ SG_ 2365403390 Joystick4YAxisPosition "Joystick 4 Y-Axis Position: The position of the joystick in the relative motion of travel from the neutral position.  Position value of 0 is Neutral and position value 1000 (100%) is the end of linear zone.  Value of 1022 indicates an error has occur...";
CM_ SG_ 2365403390 Jstk4XAxsDtntPstnStts "Joystick 4 X-Axis Detent Position Status: Reports when the current joystick position is in the detent position for that axis of travel.00b = Not in the Detent Position01b = In the Detent Position10b = Error Indicator11b = Not Available";
CM_ SG_ 2365403390 Jstk4XAxsLvrLftNgtvPstnStts "Joystick 4 X-Axis Lever Left Negative Position Status: Reports when the current joystick position is on the negative travel side (back, left, counterclockwise, down) relative to the neutral position for that axis of travel. 00b = Not on negative side...";
CM_ SG_ 2365403390 Jstk4XAxsLvrRghtPstvPstnStts "Joystick 4 X-Axis Lever Right Positive Position Status: Reports when the current joystick position is on the positive travel side (forward, right, clockwise, up) relative to the neutral position for that axis of travel. 00b = Not on Positive side of ...";
CM_ SG_ 2365403390 Jstk4XAxsNtrlPstnStts "Joystick 4 X-Axis Neutral Position Status: Reports when the current joystick position is in the neutral position for that axis of travel.  The neutral position measurement must be determined from some mechanism other than the axis position measuremen...";
CM_ SG_ 2365403390 Jstk4YAxsDtntPstnStts "Joystick 4 Y-Axis Detent Position Status: Reports when the current joystick position is in the detent position for that axis of travel.00b = Not in the Detent Position01b = In the Detent Position10b = Error Indicator11b = Not Available";
CM_ SG_ 2365403390 Jstk4YAxsLvrBkNgtvPstnStts "Joystick 4 Y-Axis Lever Back Negative Position Status: Reports when the current joystick position is on the negative travel side (back, left, counterclockwise, down) relative to the neutral position for that axis of travel. 00b = Not on negative side...";
CM_ SG_ 2365403390 Jstk4YAxsLvrFrwrdPstvPstnStts "Joystick 4 Y-Axis Lever Forward Positive Position Status: Reports when the current joystick position is on the positive travel side (forward, right, clockwise, up) relative to the neutral position for that axis of travel. 00b = Not on Positive side o...";
CM_ SG_ 2365403390 Jstk4YAxsNtrlPstnStts "Joystick 4 Y-Axis Neutral Position Status: Reports when the current joystick position is in the neutral position for that axis of travel.  The neutral position measurement must be determined from some mechanism other than the axis position measuremen...";
CM_ BO_ 2365428478 "Engine Operating Information";
CM_ SG_ 2365428478 EngineControlledShutdownRequest "Engine Controlled Shutdown Request: A signal issued by the engine control system to a user or external system requesting for a controlled shutdown.  This request is made when engine protection diagnostics determine a condition warrants a shutdown soo...";
CM_ SG_ 2365428478 EngineCoolantPumpControl "Engine Coolant Pump Control: Control setting for an electrically actuated engine coolant circulating pump. 00b = Off01b = On10b = Reserved11b = Don't care / take no action.";
CM_ SG_ 2365428478 EngineDerateRequest "Engine Derate Request: This parameter is a derate request made from the engine control system to an external system, where the engine is requesting an external device to reduce the load being applied.  A zero value indicates that there is no derate b...";
CM_ SG_ 2365428478 EngineDesiredTorqueRequest "Engine Desired Torque Request: This is the torque that the ECM desires to provide. It is a request made from the ECM to an external system. A valid value within the operating range indicates the engine is requesting an external controller to change t...";
CM_ SG_ 2365428478 EngineFuelShutoff1Control "Engine Fuel Shutoff 1 Control: Control setting for fuel shutoff 1.  The second instance is SPN 2807.  For a single fuel shutoff system, this represents its commanded position.  For a dual fuel shutoff system, this SP is representative of the upstream...";
CM_ SG_ 2365428478 EngineFuelShutoff2Control "Engine Fuel Shutoff 2 Control: Control setting for fuel shutoff 2.  First instance is SPN 632.  For a dual fuel shutoff system, this SP is representative of the downstream fuel shutoff commanded position.  When fuel (gas) is desired at the engine, th...";
CM_ SG_ 2365428478 EngineFuelShutoffVentControl "Engine Fuel Shutoff Vent Control: Control setting for a fuel shutoff vent.  Typically, for a dual fuel shutoff system, the vent line is located between them and is plumbed to vent outside to atmosphere.  The vent control typically always actuates opp...";
CM_ SG_ 2365428478 EngineOilPreheaterControl "Engine Oil Pre-heater Control: Control setting for an electrically actuated oil pre-heating device.00b = Off01b = On10b = Reserved11b = Don't care / take no actionIn addition to communicating desired action of the electrically actuated oil pre-heater...";
CM_ SG_ 2365428478 EngineOilPrimingPumpControl "Engine Oil Priming Pump Control: This control is used to activate a pump that lubricates the engine, particularly prior to initial engine startup.00b = Off01b = On10b = Reserved11b = unavailable";
CM_ SG_ 2365428478 EngineOperatingState "Engine Operating State: This parameter is used to indicate the current state, or mode, of operation by the engine.  This is a status parameter.0000b = Engine Stopped0001b = Pre-Start0010b = Starting0011b = Warm-Up0100b = Running0101b = Cool-down0110b...";
CM_ SG_ 2365428478 EnginePreHeaterControl "Engine Pre-Heater Control: Control setting for an electrically actuated engine block or coolant pre-heating device.00b = Off 01b = On10b = Reserved11b = Unavailable";
CM_ SG_ 2365428478 EngineStarterMotorRelayControl "Engine Starter Motor Relay Control: Command signal used to energize or de-energize the engine starter motor relay.00b = Off01b = On10b = Reserved for SAE assignment11b = Don't care/take no action";
CM_ SG_ 2365428478 EngnCldAmntElvtdIdlStts "Engine Cold Ambient Elevated Idle Status: Indicates that the engine is elevating the idle speed due to cold strategies.00b = No Idle Elevation Active - standard idle speed01b = Idle Elevation Active10b = Reserved for SAE assignment11b = Unavailable...";
CM_ SG_ 2365428478 EngnEltrlSstmPwrCnsrvtnCntrl "Engine Electrical System Power Conservation Control: Control setting for cutting power to various devices when the engine is not in use.  Useful if it is desired to keep the engine in standby, with main control ECU still powered on and communictaing ...";
CM_ SG_ 2365428478 EngnEmrgnImmdtShtdwnIndtn "Engine Emergency (Immediate) Shutdown Indication: A signal issued by the engine control system to a user or external system indicating that it is immediately shutting the engine down.  This indication is made when engine protection diagnostics determ...";
CM_ SG_ 2365428478 EngnFlShtffVlvLkTstCntrl "Engine Fuel Shutoff Valve Leak Test Control: Control setting for fuel shutoff valve proving system test.  Typically, this type of system can only be used with a dual fuel shutoff system.  The test consists of a small pump to pressurize the chamber be...";
CM_ SG_ 2365428478 FuelPumpPrimerControl "Fuel Pump Primer Control: Parameter used to activate or deactivate a priming system on the fuel transfer system. The fuel priming system is a system that purges air in the fuel lines and may assist fuel delivery to a second pump at lower speeds.00b =...";
CM_ SG_ 2365428478 TmRmnngnEngnOprtngStt "Time Remaining in Engine Operating State: This parameter is used to indicate the time remaining in the current engine operating state, based on the state defined in the SP Engine Operating State (SPN 3543). For the states in which time remaining is n...";
CM_ BO_ 2365428734 "Generator Control 1";
CM_ SG_ 2365428734 EngineSpeedGovernorDroop "Engine Speed Governor Droop: This is the percent speed droop adjustment relative to rated speed setpoint. The Engine Speed Droop is equal to the following equation: 100*[(Engine Speed at no load - Engine Speed at full rated load)/ (Engine Speed at fu...";
CM_ SG_ 2365428734 EngineSpeedGovernorGainAdjust "Engine Speed Governor Gain Adjust: This parameter is used to adjust multiple gains at same time to attain engine stability across a broader range of applications.  -32128 is least responsive0 is normal+32127 is most responsive";
CM_ SG_ 2365428734 GeneratorAlternatorEfficiency "Generator Alternator Efficiency: Measured, calculated, and/or estimated operating efficiency of the generator alternator.  Percentage reflects ratio of power output divided by power input, multiplied by 100.";
CM_ SG_ 2365428734 GeneratorFrequencySelection "Generator Frequency Selection: Command from user and/or generator control system for the genset (engine) to target operations for 50 Hz, 60 Hz, or 400 Hz.0000b = 50 Hz0001b = 60 Hz0010b = 400 Hz0011b to 1101b = SAE Reserved1110b = Unknown1111b = Don'...";
CM_ SG_ 2365428734 GeneratorGoverningSpeedCommand "Generator Governing Speed Command: Command from user and/or generator control system for the genset (engine) to govern to low idle or rated base speed setpoints.  If this method of engine control is used, then the PGN 0 (TSC1) is not expected to be r...";
CM_ SG_ 2365428734 GnrtrCntrlNtInAtmtStrtStt "Generator Control Not In Automatic Start State: This parameter indicates whether or not the generator set is in a condition to automatically start up and provide power. If not, this status parameter is in the ACTIVE state.00b = inactive (ready to sta...";
CM_ SG_ 2365428734 GnrtrNtRdtAtmtllPrlllStt "Generator Not Ready to Automatically Parallel State: This parameter indicates whether or not all systems required to start the engine and close to the bus are prepared to operate automatically. If not, the generator is not ready to automatically para...";
CM_ SG_ 2365428734 RequestedEngineControlMode "Requested Engine Control Mode: This parameter is used to request a change to the engine control mode.  This is a status parameter.  0000b = Normal Engine Shutdown0001b = Rapid Engine Shutdown0010b = Emergency Engine Shutdown0011b = Normal Engine Star...";
CM_ BO_ 2365433598 "Voltage Regulator Excitation Status";
CM_ SG_ 2365433598 GeneratorExcitationFieldCurrent "Generator Excitation Field Current: Measured signal that represents the generator excitation field current.";
CM_ SG_ 2365433598 GeneratorExcitationFieldVoltage "Generator Excitation Field Voltage: Measured signal that represents the generator excitation field voltage.  Generator excitation field voltage is indicative of the amount of excitation current being supplied by the voltage regulator to the generator...";
CM_ SG_ 2365433598 GnrtrOtptVltgBsPrntg "Generator Output Voltage Bias Percentage: Measured signal that represents the voltage bias percentage of the generator ouptput voltage being requested by external to the voltage regulator.  Generator output voltage bias percentage is the amount of vo...";
CM_ BO_ 2365443326 "Operators External Light Controls Message";
CM_ SG_ 2365443326 HazardLightSwitch "Hazard Light Switch: A 2 bit parameter to indicate the selected position of the operator's hazard light switch.00b = Hazard Lamps to be Off01b = Hazard Lamps to be Flashing10b = Error11b = Not available (do not change)";
CM_ SG_ 2365443326 HighLowBeamSwitch "High-Low Beam Switch: A 2 bit parameter to indicate the selected position of the operator's high/low beam select switch.00b = Low Beam Selected01b = High Beam Selected10b = Error11b = Not available (do not change)";
CM_ SG_ 2365443326 MainLightSwitch "Main Light Switch: A 4 bit parameter to indicate the selected position of the operator's main light switch.0000b = Off - The position by which the operator selects that none of the lamps are to be on.0001b = Park On - The position by which the operat...";
CM_ SG_ 2365443326 OperatorsDesiredBacklight "Operators Desired Back-light: A 8 bit parameter to indicate the level of back lighting the operator has selected for displays.  This is to be differentiated from the Illumination Brightness Percent (SPN 1487 PGN 53248 Cab Illumination Message) which ...";
CM_ SG_ 2365443326 OprtrsDsrdDldLmpOffTm "Operators Desired - Delayed Lamp Off Time: A 16 bit parameter to be associated with Delayed Off position (1000b) of the Main Light Switch.  This parameter indicates the time the operator wishes to have elapse following the Main Light switch being pla...";
CM_ SG_ 2365443326 TurnSignalSwitch "Turn Signal Switch: A 4 bit parameter to indicate the selected position of the operator's turn signal switch.0000b = No Turn being signaled0001b = Left Turn to be Flashing0010b = Right turn to be Flashing0011b to 1101b = Reserved   1110b = Error (to ...";
CM_ SG_ 2365443326 WorkLightSwitch "Work Light Switch: A 4 bit parameter to indicate the selected position of the operator's work light switch. In Ag applications the work lights are often refereed to as field lights.  In on-highway applications the work lights are often referred to as...";
CM_ SG_ 2365443326 ExteriorLampCheckSwitch "Exterior Lamp Check Switch: Indicates the selected position of the operator's exterior lamp check switch.00b = Exterior lamp check inactive01b = Exterior lamp check active10b = Error11b = Not available";
CM_ SG_ 2365443326 HeadlampEmergencyFlashSwitch "Headlamp Emergency Flash Switch: Indicates the selected position of the headlamp emergency flash (wig-wag) switch.00b = Headlamp emergency flash inactive01b = Headlamp emergency flash active10b = Error11b = Not available";
CM_ SG_ 2365443326 AuxiliaryLampGroupSwitch "Auxiliary Lamp Group Switch: Indicates the selected position of the operator's auxiliary lamp group switch. The auxiliary lamp group may include parking lamps, position lamps, tail lamps, marker lamps, clearance lamps, identification lamps, license p...";
CM_ BO_ 2365445886 "Basic Joystick Message 1";
CM_ SG_ 2365445886 Joystick1Button10PressedStatus "Joystick 1 Button 10 Pressed Status: Reports when the joystick button has been pressed.00b = Button not pressed01b = Button pressed10b = Error Indicator11b = Not Available";
CM_ SG_ 2365445886 Joystick1Button11PressedStatus "Joystick 1 Button 11 Pressed Status: Reports when the joystick button has been pressed.00b = Button not pressed01b = Button pressed10b = Error Indicator11b = Not Available";
CM_ SG_ 2365445886 Joystick1Button12PressedStatus "Joystick 1 Button 12 Pressed Status: Reports when the joystick button has been pressed.00b = Button not pressed01b = Button pressed10b = Error Indicator11b = Not Available";
CM_ SG_ 2365445886 Joystick1Button1PressedStatus "Joystick 1 Button 1 Pressed Status: Reports when the joystick button has been pressed.00b = Button not pressed01b = Button pressed10b = Error Indicator11b = Not Available";
CM_ SG_ 2365445886 Joystick1Button2PressedStatus "Joystick 1 Button 2 Pressed Status: Reports when the joystick button has been pressed.00b = Button not pressed01b = Button pressed10b = Error Indicator11b = Not Available";
CM_ SG_ 2365445886 Joystick1Button3PressedStatus "Joystick 1 Button 3 Pressed Status: Reports when the joystick button has been pressed.00b = Button not pressed01b = Button pressed10b = Error Indicator11b = Not Available";
CM_ SG_ 2365445886 Joystick1Button4PressedStatus "Joystick 1 Button 4 Pressed Status: Reports when the joystick button has been pressed.00b = Button not pressed01b = Button pressed10b = Error Indicator11b = Not Available";
CM_ SG_ 2365445886 Joystick1Button5PressedStatus "Joystick 1 Button 5 Pressed Status: Reports when the joystick button has been pressed.00b = Button not pressed01b = Button pressed10b = Error Indicator11b = Not Available";
CM_ SG_ 2365445886 Joystick1Button6PressedStatus "Joystick 1 Button 6 Pressed Status: Reports when the joystick button has been pressed.00b = Button not pressed01b = Button pressed10b = Error Indicator11b = Not Available";
CM_ SG_ 2365445886 Joystick1Button7PressedStatus "Joystick 1 Button 7 Pressed Status: Reports when the joystick button has been pressed.00b = Button not pressed01b = Button pressed10b = Error Indicator11b = Not Available";
CM_ SG_ 2365445886 Joystick1Button8PressedStatus "Joystick 1 Button 8 Pressed Status: Reports when the joystick button has been pressed.00b = Button not pressed01b = Button pressed10b = Error Indicator11b = Not Available";
CM_ SG_ 2365445886 Joystick1Button9PressedStatus "Joystick 1 Button 9 Pressed Status: Reports when the joystick button has been pressed.00b = Button not pressed01b = Button pressed10b = Error Indicator11b = Not Available";
CM_ SG_ 2365445886 Joystick1XAxisPosition "Joystick 1 X-Axis Position: The position of the joystick in the relative motion of travel from the neutral position.  Position value of 0 is Neutral and position value 1000 (100%) is the end of linear zone.  Value of 1022 indicates an error has occur...";
CM_ SG_ 2365445886 Joystick1YAxisPosition "Joystick 1 Y-Axis Position: The position of the joystick in the relative motion of travel from the neutral position.  Position value of 0 is Neutral and position value 1000 (100%) is the end of linear zone.  Value of 1022 indicates an error has occur...";
CM_ SG_ 2365445886 Jstk1XAxsDtntPstnStts "Joystick 1 X-Axis Detent Position Status: Reports when the current joystick position is in the detent position for that axis of travel.00b = Not in the Detent Position01b = In the Detent Position10b = Error Indicator11b = Not Available";
CM_ SG_ 2365445886 Jstk1XAxsLvrLftNgtvPstnStts "Joystick 1 X-Axis Lever Left Negative Position Status: Reports when the current joystick position is on the negative travel side (back, left, counterclockwise, down) relative to the neutral position for that axis of travel. 00b = Not on negative side...";
CM_ SG_ 2365445886 Jstk1XAxsLvrRghtPstvPstnStts "Joystick 1 X-Axis Lever Right Positive Position Status: Reports when the current joystick position is on the positive travel side (forward, right, clockwise, up) relative to the neutral position for that axis of travel. 00b = Not on Positive side of ...";
CM_ SG_ 2365445886 Jstk1XAxsNtrlPstnStts "Joystick 1 X-Axis Neutral Position Status: Reports when the current joystick position is in the neutral position for that axis of travel.  The neutral position measurement must be determined from some mechanism other than the axis position measuremen...";
CM_ SG_ 2365445886 Jstk1YAxsDtntPstnStts "Joystick 1 Y-Axis Detent Position Status: Reports when the current joystick position is in the detent position for that axis of travel.00b = Not in the Detent Position01b = In the Detent Position10b = Error Indicator11b = Not Available";
CM_ SG_ 2365445886 Jstk1YAxsLvrBkNgtvPstnStts "Joystick 1 Y-Axis Lever Back Negative Position Status: Reports when the current joystick position is on the negative travel side (back, left, counterclockwise, down) relative to the neutral position for that axis of travel. 00b = Not on negative side...";
CM_ SG_ 2365445886 Jstk1YAxsLvrFrwrdPstvPstnStts "Joystick 1 Y-Axis Lever Forward Positive Position Status: Reports when the current joystick position is on the positive travel side (forward, right, clockwise, up) relative to the neutral position for that axis of travel. 00b = Not on Positive side o...";
CM_ SG_ 2365445886 Jstk1YAxsNtrlPstnStts "Joystick 1 Y-Axis Neutral Position Status: Reports when the current joystick position is in the neutral position for that axis of travel.  The neutral position measurement must be determined from some mechanism other than the axis position measuremen...";
CM_ BO_ 2365446142 "Extended Joystick Message 1";
CM_ SG_ 2365446142 Joystick1Button13PressedStatus "Joystick 1 Button 13 Pressed Status: Reports when the joystick button has been pressed.00b = Button not pressed01b = Button pressed10b = Error Indicator11b = Not Available";
CM_ SG_ 2365446142 Joystick1Button14PressedStatus "Joystick 1 Button 14 Pressed Status: Reports when the joystick button has been pressed.00b = Button not pressed01b = Button pressed10b = Error Indicator11b = Not Available";
CM_ SG_ 2365446142 Joystick1Button15PressedStatus "Joystick 1 Button 15 Pressed Status: Reports when the joystick button has been pressed.00b = Button not pressed01b = Button pressed10b = Error Indicator11b = Not Available";
CM_ SG_ 2365446142 Joystick1Button16PressedStatus "Joystick 1 Button 16 Pressed Status: Reports when the joystick button has been pressed.00b = Button not pressed01b = Button pressed10b = Error Indicator11b = Not Available";
CM_ SG_ 2365446142 Joystick1GripXAxisPosition "Joystick 1 Grip X-Axis Position: The position of the joystick grip in the relative motion of travel from the neutral position.  Position value of 0 is Neutral and position value 1000 (100%) is the end of linear zone.  Value of 1022 indicates an error...";
CM_ SG_ 2365446142 Joystick1GripYAxisPosition "Joystick 1 Grip Y-Axis Position: The position of the joystick grip in the relative motion of travel from the neutral position.  Position value of 0 is Neutral and position value 1000 (100%) is the end of linear zone.  Value of 1022 indicates an error...";
CM_ SG_ 2365446142 Joystick1ThetaAxisPosition "Joystick 1 Theta-Axis Position: The position of the joystick in the relative motion of travel from the neutral position.  Position value of 0 is Neutral and position value 1000 (100%) is the end of linear zone.  Value of 1022 indicates an error has o...";
CM_ SG_ 2365446142 Jst1GpYAxsLvFwdPstvPstStts "Joystick 1 Grip Y-Axis Lever Forward Positive Position Status: Reports when the current joystick grip position is on the positive travel side (forward, right, clockwise, up) relative to the neutral position for that axis of travel. 00b = Not on Posit...";
CM_ SG_ 2365446142 Jst1TtAxsCtCwsNtvPstStts "Joystick 1 Theta-Axis Counter Clockwise Negative Position Status: Reports when the current joystick position is on the negative travel side (back, left, counterclockwise, down) relative to the neutral position for that axis of travel. 00b = Not on ne...";
CM_ SG_ 2365446142 Jstk1GrpXAxsDtntPstnStts "Joystick 1 Grip X-Axis Detent Position Status: Reports when the current joystick grip position is in the detent position for that axis of travel.00b = Not in the Detent Position01b = In the Detent Position10b = Error Indicator11b = Not Available...";
CM_ SG_ 2365446142 Jstk1GrpXAxsLvrLftNgtvPstnStts "Joystick 1 Grip X-Axis Lever Left Negative Position Status: Reports when the current joystick grip position is on the negative travel side (back, left, counterclockwise, down) relative to the neutral position for that axis of travel. 00b = Not on neg...";
CM_ SG_ 2365446142 Jstk1GrpXAxsLvrRghtPstvPstnStts "Joystick 1 Grip X-Axis Lever Right Positive Position Status: Reports when the current joystick grip position is on the positive travel side (forward, right, clockwise, up) relative to the neutral position for that axis of travel. 00b = Not on Positiv...";
CM_ SG_ 2365446142 Jstk1GrpXAxsNtrlPstnStts "Joystick 1 Grip X-Axis Neutral Position Status: Reports when the current joystick grip position is in the neutral position for that axis of travel.  The neutral position measurement must be determined from some mechanism other than the axis position ...";
CM_ SG_ 2365446142 Jstk1GrpYAxsDtntPstnStts "Joystick 1 Grip Y-Axis Detent Position Status: Reports when the current joystick grip position is in the detent position for that axis of travel.00b = Not in the Detent Position01b = In the Detent Position10b = Error Indicator11b = Not Available...";
CM_ SG_ 2365446142 Jstk1GrpYAxsLvrBkNgtvPstnStts "Joystick 1 Grip Y-Axis Lever Back Negative Position Status: Reports when the current joystick grip position is on the negative travel side (back, left, counterclockwise, down) relative to the neutral position for that axis of travel. 00b = Not on neg...";
CM_ SG_ 2365446142 Jstk1GrpYAxsNtrlPstnStts "Joystick 1 Grip Y-Axis Neutral Position Status: Reports when the current joystick grip position is in the neutral position for that axis of travel.  The neutral position measurement must be determined from some mechanism other than the axis position ...";
CM_ SG_ 2365446142 Jstk1ThtAxsClkwsPstvPstnStts "Joystick 1 Theta-Axis Clockwise Positive Position Status: Reports when the current joystick position is on the positive travel side (forward, right, clockwise, up) relative to the neutral position for that axis of travel. 00b = Not on Positive side o...";
CM_ SG_ 2365446142 Jstk1ThtAxsDtntPstnStts "Joystick 1 Theta-Axis Detent Position Status: Reports when the current joystick position is in the detent position for that axis of travel.00b = Not in the Detent Position01b = In the Detent Position10b = Error Indicator11b = Not Available";
CM_ SG_ 2365446142 Jstk1ThtAxsNtrlPstnStts "Joystick 1 Theta-Axis Neutral Position Status: Reports when the current joystick position is in the neutral position for that axis of travel.  The neutral position measurement must be determined from some mechanism other than the axis position measur...";
CM_ BO_ 2365446398 "Basic Joystick Message 2";
CM_ SG_ 2365446398 Joystick2Button10PressedStatus "Joystick 2 Button 10 Pressed Status: Reports when the joystick button has been pressed.00b = Button not pressed01b = Button pressed10b = Error Indicator11b = Not Available";
CM_ SG_ 2365446398 Joystick2Button11PressedStatus "Joystick 2 Button 11 Pressed Status: Reports when the joystick button has been pressed.00b = Button not pressed01b = Button pressed10b = Error Indicator11b = Not Available";
CM_ SG_ 2365446398 Joystick2Button12PressedStatus "Joystick 2 Button 12 Pressed Status: Reports when the joystick button has been pressed.00b = Button not pressed01b = Button pressed10b = Error Indicator11b = Not Available";
CM_ SG_ 2365446398 Joystick2Button1PressedStatus "Joystick 2 Button 1 Pressed Status: Reports when the joystick button has been pressed.00b = Button not pressed01b = Button pressed10b = Error Indicator11b = Not Available";
CM_ SG_ 2365446398 Joystick2Button2PressedStatus "Joystick 2 Button 2 Pressed Status: Reports when the joystick button has been pressed.00b = Button not pressed01b = Button pressed10b = Error Indicator11b = Not Available";
CM_ SG_ 2365446398 Joystick2Button3PressedStatus "Joystick 2 Button 3 Pressed Status: Reports when the joystick button has been pressed.00b = Button not pressed01b = Button pressed10b = Error Indicator11b = Not Available";
CM_ SG_ 2365446398 Joystick2Button4PressedStatus "Joystick 2 Button 4 Pressed Status: Reports when the joystick button has been pressed.00b = Button not pressed01b = Button pressed10b = Error Indicator11b = Not Available";
CM_ SG_ 2365446398 Joystick2Button5PressedStatus "Joystick 2 Button 5 Pressed Status: Reports when the joystick button has been pressed.00b = Button not pressed01b = Button pressed10b = Error Indicator11b = Not Available";
CM_ SG_ 2365446398 Joystick2Button6PressedStatus "Joystick 2 Button 6 Pressed Status: Reports when the joystick button has been pressed.00b = Button not pressed01b = Button pressed10b = Error Indicator11b = Not Available";
CM_ SG_ 2365446398 Joystick2Button7PressedStatus "Joystick 2 Button 7 Pressed Status: Reports when the joystick button has been pressed.00b = Button not pressed01b = Button pressed10b = Error Indicator11b = Not Available";
CM_ SG_ 2365446398 Joystick2Button8PressedStatus "Joystick 2 Button 8 Pressed Status: Reports when the joystick button has been pressed.00b = Button not pressed01b = Button pressed10b = Error Indicator11b = Not Available";
CM_ SG_ 2365446398 Joystick2Button9PressedStatus "Joystick 2 Button 9 Pressed Status: Reports when the joystick button has been pressed.00b = Button not pressed01b = Button pressed10b = Error Indicator11b = Not Available";
CM_ SG_ 2365446398 Joystick2XAxisPosition "Joystick 2 X-Axis Position: The position of the joystick in the relative motion of travel from the neutral position.  Position value of 0 is Neutral and position value 1000 (100%) is the end of linear zone.  Value of 1022 indicates an error has occur...";
CM_ SG_ 2365446398 Joystick2YAxisPosition "Joystick 2 Y-Axis Position: The position of the joystick in the relative motion of travel from the neutral position.  Position value of 0 is Neutral and position value 1000 (100%) is the end of linear zone.  Value of 1022 indicates an error has occur...";
CM_ SG_ 2365446398 Jstk2XAxsDtntPstnStts "Joystick 2 X-Axis Detent Position Status: Reports when the current joystick position is in the detent position for that axis of travel.00b = Not in the Detent Position01b = In the Detent Position10b = Error Indicator11b = Not Available";
CM_ SG_ 2365446398 Jstk2XAxsLvrLftNgtvPstnStts "Joystick 2 X-Axis Lever Left Negative Position Status: Reports when the current joystick position is on the negative travel side (back, left, counterclockwise, down) relative to the neutral position for that axis of travel. 00b = Not on negative side...";
CM_ SG_ 2365446398 Jstk2XAxsLvrRghtPstvPstnStts "Joystick 2 X-Axis Lever Right Positive Position Status: Reports when the current joystick position is on the positive travel side (forward, right, clockwise, up) relative to the neutral position for that axis of travel. 00b = Not on Positive side of ...";
CM_ SG_ 2365446398 Jstk2XAxsNtrlPstnStts "Joystick 2 X-Axis Neutral Position Status: Reports when the current joystick position is in the neutral position for that axis of travel.  The neutral position measurement must be determined from some mechanism other than the axis position measuremen...";
CM_ SG_ 2365446398 Jstk2YAxsDtntPstnStts "Joystick 2 Y-Axis Detent Position Status: Reports when the current joystick position is in the detent position for that axis of travel.00b = Not in the Detent Position01b = In the Detent Position10b = Error Indicator11b = Not Available";
CM_ SG_ 2365446398 Jstk2YAxsLvrBkNgtvPstnStts "Joystick 2 Y-Axis Lever Back Negative Position Status: Reports when the current joystick position is on the negative travel side (back, left, counterclockwise, down) relative to the neutral position for that axis of travel. 00b = Not on negative side...";
CM_ SG_ 2365446398 Jstk2YAxsLvrFrwrdPstvPstnStts "Joystick 2 Y-Axis Lever Forward Positive Position Status: Reports when the current joystick position is on the positive travel side (forward, right, clockwise, up) relative to the neutral position for that axis of travel. 00b = Not on Positive side o...";
CM_ SG_ 2365446398 Jstk2YAxsNtrlPstnStts "Joystick 2 Y-Axis Neutral Position Status: Reports when the current joystick position is in the neutral position for that axis of travel.  The neutral position measurement must be determined from some mechanism other than the axis position measuremen...";
CM_ BO_ 2365446654 "Extended Joystick Message 2";
CM_ SG_ 2365446654 Joystick2Button13PressedStatus "Joystick 2 Button 13 Pressed Status: Reports when the joystick button has been pressed.00b = Button not pressed01b = Button pressed10b = Error Indicator11b = Not Available";
CM_ SG_ 2365446654 Joystick2Button14PressedStatus "Joystick 2 Button 14 Pressed Status: Reports when the joystick button has been pressed.00b = Button not pressed01b = Button pressed10b = Error Indicator11b = Not Available";
CM_ SG_ 2365446654 Joystick2Button15PressedStatus "Joystick 2 Button 15 Pressed Status: Reports when the joystick button has been pressed.00b = Button not pressed01b = Button pressed10b = Error Indicator11b = Not Available";
CM_ SG_ 2365446654 Joystick2Button16PressedStatus "Joystick 2 Button 16 Pressed Status: Reports when the joystick button has been pressed.00b = Button not pressed01b = Button pressed10b = Error Indicator11b = Not Available";
CM_ SG_ 2365446654 Joystick2GripXAxisPosition "Joystick 2 Grip X-Axis Position: The position of the joystick grip in the relative motion of travel from the neutral position.  Position value of 0 is Neutral and position value 1000 (100%) is the end of linear zone.  Value of 1022 indicates an error...";
CM_ SG_ 2365446654 Joystick2GripYAxisPosition "Joystick 2 Grip Y-Axis Position: The position of the joystick grip in the relative motion of travel from the neutral position.  Position value of 0 is Neutral and position value 1000 (100%) is the end of linear zone.  Value of 1022 indicates an error...";
CM_ SG_ 2365446654 Joystick2ThetaAxisPosition "Joystick 2 Theta-Axis Position: The position of the joystick in the relative motion of travel from the neutral position.  Position value of 0 is Neutral and position value 1000 (100%) is the end of linear zone.  Value of 1022 indicates an error has o...";
CM_ SG_ 2365446654 Jst2GpYAxsLvFwdPstvPstStts "Joystick 2 Grip Y-Axis Lever Forward Positive Position Status: Reports when the current joystick grip position is on the positive travel side (forward, right, clockwise, up) relative to the neutral position for that axis of travel. 00b = Not on Posit...";
CM_ SG_ 2365446654 Jst2TtAxsCtCwsNtvPstStts "Joystick 2 Theta-Axis Counter Clockwise Negative Position Status: Reports when the current joystick position is on the negative travel side (back, left, counterclockwise, down) relative to the neutral position for that axis of travel. 00b = Not on ne...";
CM_ SG_ 2365446654 Jstk2GrpXAxsDtntPstnStts "Joystick 2 Grip X-Axis Detent Position Status: Reports when the current joystick grip position is in the detent position for that axis of travel.00b = Not in the Detent Position01b = In the Detent Position10b = Error Indicator11b = Not Available...";
CM_ SG_ 2365446654 Jstk2GrpXAxsLvrLftNgtvPstnStts "Joystick 2 Grip X-Axis Lever Left Negative Position Status: Reports when the current joystick grip position is on the negative travel side (back, left, counterclockwise, down) relative to the neutral position for that axis of travel. 00b = Not on neg...";
CM_ SG_ 2365446654 Jstk2GrpXAxsLvrRghtPstvPstnStts "Joystick 2 Grip X-Axis Lever Right Positive Position Status: Reports when the current joystick grip position is on the positive travel side (forward, right, clockwise, up) relative to the neutral position for that axis of travel. 00b = Not on Positiv...";
CM_ SG_ 2365446654 Jstk2GrpXAxsNtrlPstnStts "Joystick 2 Grip X-Axis Neutral Position Status: Reports when the current joystick grip position is in the neutral position for that axis of travel.  The neutral position measurement must be determined from some mechanism other than the axis position ...";
CM_ SG_ 2365446654 Jstk2GrpYAxsDtntPstnStts "Joystick 2 Grip Y-Axis Detent Position Status: Reports when the current joystick grip position is in the detent position for that axis of travel.00b = Not in the Detent Position01b = In the Detent Position10b = Error Indicator11b = Not Available...";
CM_ SG_ 2365446654 Jstk2GrpYAxsLvrBkNgtvPstnStts "Joystick 2 Grip Y-Axis Lever Back Negative Position Status: Reports when the current joystick grip position is on the negative travel side (back, left, counterclockwise, down) relative to the neutral position for that axis of travel. 00b = Not on neg...";
CM_ SG_ 2365446654 Jstk2GrpYAxsNtrlPstnStts "Joystick 2 Grip Y-Axis Neutral Position Status: Reports when the current joystick grip position is in the neutral position for that axis of travel.  The neutral position measurement must be determined from some mechanism other than the axis position ...";
CM_ SG_ 2365446654 Jstk2ThtAxsClkwsPstvPstnStts "Joystick 2 Theta-Axis Clockwise Positive Position Status: Reports when the current joystick position is on the positive travel side (forward, right, clockwise, up) relative to the neutral position for that axis of travel. 00b = Not on Positive side o...";
CM_ SG_ 2365446654 Jstk2ThtAxsDtntPstnStts "Joystick 2 Theta-Axis Detent Position Status: Reports when the current joystick position is in the detent position for that axis of travel.00b = Not in the Detent Position01b = In the Detent Position10b = Error Indicator11b = Not Available";
CM_ SG_ 2365446654 Jstk2ThtAxsNtrlPstnStts "Joystick 2 Theta-Axis Neutral Position Status: Reports when the current joystick position is in the neutral position for that axis of travel.  The neutral position measurement must be determined from some mechanism other than the axis position measur...";
CM_ BO_ 2365446910 "Basic Joystick Message 3";
CM_ SG_ 2365446910 Joystick3Button10PressedStatus "Joystick 3 Button 10 Pressed Status: Reports when the joystick button has been pressed.00b = Button not pressed01b = Button pressed10b = Error Indicator11b = Not Available";
CM_ SG_ 2365446910 Joystick3Button11PressedStatus "Joystick 3 Button 11 Pressed Status: Reports when the joystick button has been pressed.00b = Button not pressed01b = Button pressed10b = Error Indicator11b = Not Available";
CM_ SG_ 2365446910 Joystick3Button12PressedStatus "Joystick 3 Button 12 Pressed Status: Reports when the joystick button has been pressed.00b = Button not pressed01b = Button pressed10b = Error Indicator11b = Not Available";
CM_ SG_ 2365446910 Joystick3Button1PressedStatus "Joystick 3 Button 1 Pressed Status: Reports when the joystick button has been pressed.00b = Button not pressed01b = Button pressed10b = Error Indicator11b = Not Available";
CM_ SG_ 2365446910 Joystick3Button2PressedStatus "Joystick 3 Button 2 Pressed Status: Reports when the joystick button has been pressed.00b = Button not pressed01b = Button pressed10b = Error Indicator11b = Not Available";
CM_ SG_ 2365446910 Joystick3Button3PressedStatus "Joystick 3 Button 3 Pressed Status: Reports when the joystick button has been pressed.00b = Button not pressed01b = Button pressed10b = Error Indicator11b = Not Available";
CM_ SG_ 2365446910 Joystick3Button4PressedStatus "Joystick 3 Button 4 Pressed Status: Reports when the joystick button has been pressed.00b = Button not pressed01b = Button pressed10b = Error Indicator11b = Not Available";
CM_ SG_ 2365446910 Joystick3Button5PressedStatus "Joystick 3 Button 5 Pressed Status: Reports when the joystick button has been pressed.00b = Button not pressed01b = Button pressed10b = Error Indicator11b = Not Available";
CM_ SG_ 2365446910 Joystick3Button6PressedStatus "Joystick 3 Button 6 Pressed Status: Reports when the joystick button has been pressed.00b = Button not pressed01b = Button pressed10b = Error Indicator11b = Not Available";
CM_ SG_ 2365446910 Joystick3Button7PressedStatus "Joystick 3 Button 7 Pressed Status: Reports when the joystick button has been pressed.00b = Button not pressed01b = Button pressed10b = Error Indicator11b = Not Available";
CM_ SG_ 2365446910 Joystick3Button8PressedStatus "Joystick 3 Button 8 Pressed Status: Reports when the joystick button has been pressed.00b = Button not pressed01b = Button pressed10b = Error Indicator11b = Not Available";
CM_ SG_ 2365446910 Joystick3Button9PressedStatus "Joystick 3 Button 9 Pressed Status: Reports when the joystick button has been pressed.00b = Button not pressed01b = Button pressed10b = Error Indicator11b = Not Available";
CM_ SG_ 2365446910 Joystick3XAxisPosition "Joystick 3 X-Axis Position: The position of the joystick in the relative motion of travel from the neutral position.  Position value of 0 is Neutral and position value 1000 (100%) is the end of linear zone.  Value of 1022 indicates an error has occur...";
CM_ SG_ 2365446910 Joystick3YAxisPosition "Joystick 3 Y-Axis Position: The position of the joystick in the relative motion of travel from the neutral position.  Position value of 0 is Neutral and position value 1000 (100%) is the end of linear zone.  Value of 1022 indicates an error has occur...";
CM_ SG_ 2365446910 Jstk3XAxsDtntPstnStts "Joystick 3 X-Axis Detent Position Status: Reports when the current joystick position is in the detent position for that axis of travel.00b = Not in the Detent Position01b = In the Detent Position10b = Error Indicator11b = Not Available";
CM_ SG_ 2365446910 Jstk3XAxsLvrLftNgtvPstnStts "Joystick 3 X-Axis Lever Left Negative Position Status: Reports when the current joystick position is on the negative travel side (back, left, counterclockwise, down) relative to the neutral position for that axis of travel. 00b = Not on negative side...";
CM_ SG_ 2365446910 Jstk3XAxsLvrRghtPstvPstnStts "Joystick 3 X-Axis Lever Right Positive Position Status: Reports when the current joystick position is on the positive travel side (forward, right, clockwise, up) relative to the neutral position for that axis of travel. 00b = Not on Positive side of ...";
CM_ SG_ 2365446910 Jstk3XAxsNtrlPstnStts "Joystick 3 X-Axis Neutral Position Status: Reports when the current joystick position is in the neutral position for that axis of travel.  The neutral position measurement must be determined from some mechanism other than the axis position measuremen...";
CM_ SG_ 2365446910 Jstk3YAxsDtntPstnStts "Joystick 3 Y-Axis Detent Position Status: Reports when the current joystick position is in the detent position for that axis of travel.00b = Not in the Detent Position01b = In the Detent Position10b = Error Indicator11b = Not Available";
CM_ SG_ 2365446910 Jstk3YAxsLvrBkNgtvPstnStts "Joystick 3 Y-Axis Lever Back Negative Position Status: Reports when the current joystick position is on the negative travel side (back, left, counterclockwise, down) relative to the neutral position for that axis of travel. 00b = Not on negative side...";
CM_ SG_ 2365446910 Jstk3YAxsLvrFrwrdPstvPstnStts "Joystick 3 Y-Axis Lever Forward Positive Position Status: Reports when the current joystick position is on the positive travel side (forward, right, clockwise, up) relative to the neutral position for that axis of travel. 00b = Not on Positive side o...";
CM_ SG_ 2365446910 Jstk3YAxsNtrlPstnStts "Joystick 3 Y-Axis Neutral Position Status: Reports when the current joystick position is in the neutral position for that axis of travel.  The neutral position measurement must be determined from some mechanism other than the axis position measuremen...";
CM_ BO_ 2365447166 "Extended Joystick Message 3";
CM_ SG_ 2365447166 Joystick3Button13PressedStatus "Joystick 3 Button 13 Pressed Status: Reports when the joystick button has been pressed.00b = Button not pressed01b = Button pressed10b = Error Indicator11b = Not Available";
CM_ SG_ 2365447166 Joystick3Button14PressedStatus "Joystick 3 Button 14 Pressed Status: Reports when the joystick button has been pressed.00b = Button not pressed01b = Button pressed10b = Error Indicator11b = Not Available";
CM_ SG_ 2365447166 Joystick3Button15PressedStatus "Joystick 3 Button 15 Pressed Status: Reports when the joystick button has been pressed.00b = Button not pressed01b = Button pressed10b = Error Indicator11b = Not Available";
CM_ SG_ 2365447166 Joystick3Button16PressedStatus "Joystick 3 Button 16 Pressed Status: Reports when the joystick button has been pressed.00b = Button not pressed01b = Button pressed10b = Error Indicator11b = Not Available";
CM_ SG_ 2365447166 Joystick3GripXAxisPosition "Joystick 3 Grip X-Axis Position: The position of the joystick grip in the relative motion of travel from the neutral position.  Position value of 0 is Neutral and position value 1000 (100%) is the end of linear zone.  Value of 1022 indicates an error...";
CM_ SG_ 2365447166 Joystick3GripYAxisPosition "Joystick 3 Grip Y-Axis Position: The position of the joystick grip in the relative motion of travel from the neutral position.  Position value of 0 is Neutral and position value 1000 (100%) is the end of linear zone.  Value of 1022 indicates an error...";
CM_ SG_ 2365447166 Joystick3ThetaAxisPosition "Joystick 3 Theta-Axis Position: The position of the joystick in the relative motion of travel from the neutral position.  Position value of 0 is Neutral and position value 1000 (100%) is the end of linear zone.  Value of 1022 indicates an error has o...";
CM_ SG_ 2365447166 Jst3GpYAxsLvFwdPstvPstStts "Joystick 3 Grip Y-Axis Lever Forward Positive Position Status: Reports when the current joystick grip position is on the positive travel side (forward, right, clockwise, up) relative to the neutral position for that axis of travel. 00b = Not on Posit...";
CM_ SG_ 2365447166 Jst3TtAxsCtCwsNtvPstStts "Joystick 3 Theta-Axis Counter Clockwise Negative Position Status: Reports when the current joystick position is on the negative travel side (back, left, counterclockwise, down) relative to the neutral position for that axis of travel. 00b = Not on ne...";
CM_ SG_ 2365447166 Jstk3GrpXAxsDtntPstnStts "Joystick 3 Grip X-Axis Detent Position Status: Reports when the current joystick grip position is in the detent position for that axis of travel.00b = Not in the Detent Position01b = In the Detent Position10b = Error Indicator11b = Not Available...";
CM_ SG_ 2365447166 Jstk3GrpXAxsLvrLftNgtvPstnStts "Joystick 3 Grip X-Axis Lever Left Negative Position Status: Reports when the current joystick grip position is on the negative travel side (back, left, counterclockwise, down) relative to the neutral position for that axis of travel. 00b = Not on neg...";
CM_ SG_ 2365447166 Jstk3GrpXAxsLvrRghtPstvPstnStts "Joystick 3 Grip X-Axis Lever Right Positive Position Status: Reports when the current joystick grip position is on the positive travel side (forward, right, clockwise, up) relative to the neutral position for that axis of travel. 00b = Not on Positiv...";
CM_ SG_ 2365447166 Jstk3GrpXAxsNtrlPstnStts "Joystick 3 Grip X-Axis Neutral Position Status: Reports when the current joystick grip position is in the neutral position for that axis of travel.  The neutral position measurement must be determined from some mechanism other than the axis position ...";
CM_ SG_ 2365447166 Jstk3GrpYAxsDtntPstnStts "Joystick 3 Grip Y-Axis Detent Position Status: Reports when the current joystick grip position is in the detent position for that axis of travel.00b = Not in the Detent Position01b = In the Detent Position10b = Error Indicator11b = Not Available...";
CM_ SG_ 2365447166 Jstk3GrpYAxsLvrBkNgtvPstnStts "Joystick 3 Grip Y-Axis Lever Back Negative Position Status: Reports when the current joystick grip position is on the negative travel side (back, left, counterclockwise, down) relative to the neutral position for that axis of travel. 00b = Not on neg...";
CM_ SG_ 2365447166 Jstk3GrpYAxsNtrlPstnStts "Joystick 3 Grip Y-Axis Neutral Position Status: Reports when the current joystick grip position is in the neutral position for that axis of travel.  The neutral position measurement must be determined from some mechanism other than the axis position ...";
CM_ SG_ 2365447166 Jstk3ThtAxsClkwsPstvPstnStts "Joystick 3 Theta-Axis Clockwise Positive Position Status: Reports when the current joystick position is on the positive travel side (forward, right, clockwise, up) relative to the neutral position for that axis of travel. 00b = Not on Positive side o...";
CM_ SG_ 2365447166 Jstk3ThtAxsDtntPstnStts "Joystick 3 Theta-Axis Detent Position Status: Reports when the current joystick position is in the detent position for that axis of travel.00b = Not in the Detent Position01b = In the Detent Position10b = Error Indicator11b = Not Available";
CM_ SG_ 2365447166 Jstk3ThtAxsNtrlPstnStts "Joystick 3 Theta-Axis Neutral Position Status: Reports when the current joystick position is in the neutral position for that axis of travel.  The neutral position measurement must be determined from some mechanism other than the axis position measur...";
CM_ BO_ 2365449982 "Hydraulic Braking System";
CM_ SG_ 2365449982 HdrlBrkPrssrSpplSttCrt1 "Hydraulic Brake Pressure Supply State Circuit 1: Signal which indicates whether the hydraulic brake pressure supply of circuit 1 is reliable; that is, able to support continued braking.00b = Supply is not reliable01b = Supply is reliable10b = Error i...";
CM_ SG_ 2365449982 HdrlBrkPrssrSpplSttCrt2 "Hydraulic Brake Pressure Supply State Circuit 2: Signal which indicates whether the hydraulic brake pressure supply of circuit 2 is reliable; that is, able to support continued braking.00b = Supply is not reliable01b = Supply is reliable10b = Error i...";
CM_ SG_ 2365449982 HdrlBrkPrssrWrnngSttCrt1 "Hydraulic Brake Pressure Warning State Circuit 1: Signal which indicates whether the hydraulic brake pressure of circuit 1 is below the warning level00b = Pressure level sufficient01b = Pressure level below warning level10b = Error indicator11b = Not...";
CM_ SG_ 2365449982 HdrlBrkPrssrWrnngSttCrt2 "Hydraulic Brake Pressure Warning State Circuit 2: Signal which indicates whether the hydraulic brake pressure of circuit 2 is below the warning level00b = Pressure level sufficient01b = Pressure level below warning level10b = Error indicator11b = Not...";
CM_ SG_ 2365449982 HdrlBrkSstmAdlWrnngCmmnd "Hydraulic Brake System Audible Warning Command: Signal which commands an audible warning by the hydraulic braking system.00b = Audible warning off01b = Audible warning on10b = Reserved11b = Don't care";
CM_ SG_ 2365449982 HydraulicBrakeFluidLevelSwitch "Hydraulic Brake Fluid Level Switch: Signal which indicates whether the hydraulic fluid level in the reservoir(s) is sufficient.00b = Fluid level is not sufficient01b = Fluid level is sufficient10b = Error indicator11b = Not available";
CM_ SG_ 2365449982 HydraulicBrakePressureCircuit1 "Hydraulic Brake Pressure Circuit 1: Gage hydraulic pressure in circuit 1 of the hydraulic brake system";
CM_ SG_ 2365449982 HydraulicBrakePressureCircuit2 "Hydraulic Brake Pressure Circuit 2: Gage hydraulic pressure in circuit 2 of the hydraulic brake system";
CM_ BO_ 2365450238 "Bus #1/Utility Sync Check Status";
CM_ SG_ 2365450238 Bus1UtilityACPhaseDifference "Bus #1/Utility AC Phase Difference: The phase difference between the Bus #1 voltage and Utility voltage.";
CM_ SG_ 2365450238 Bus1UtilityDeadBus "Bus #1/Utility Dead Bus: Indicator of whether Bus #1 is considered dead for closing to the utility. This indicator will be based on parameters such as Bus #1 Voltage and dead bus threshold values.00b = Bus is not dead01b = Bus is dead10b = Error11b =...";
CM_ SG_ 2365450238 Bus1UtilityFrequencyMatch "Bus #1/Utility Frequency Match: Indicator of whether frequency difference between Bus #1 and Utility is adequate for paralleling. This indicator will be based on the measured AC frequencies qualified using parameters such as Frequency Tolerance, Phas...";
CM_ SG_ 2365450238 Bus1UtilityInSync "Bus #1/Utility In Sync: Indicator of whether Bus #1 and Utility are properly synchronized for paralleling. This indicator will be based on parameters such as Voltage Match, Frequency Match, and Phase Match.00b = Not synchronized01b = Synchronized10b ...";
CM_ SG_ 2365450238 Bus1UtilityPhaseMatch "Bus #1/Utility Phase Match: Indicator of whether phase difference between Bus #1 and Utility is adequate for paralleling. This indicator will be based on the measured AC phase difference qualified using parameters such as Phase Tolerance and Dwell Ti...";
CM_ SG_ 2365450238 Bus1UtilityVoltageMatch "Bus #1/Utility Voltage Match: Indicator of whether voltage difference between Bus #1 and Utility is adequate for paralleling. This indicator will be based on the measured AC voltages qualified using parameters such as Voltage Tolerance.00b = Voltages...";
CM_ BO_ 2365450494 "Bus #1/Generator Sync Check Status";
CM_ SG_ 2365450494 Bus1GeneratorACPhaseDifference "Bus #1/Generator AC Phase Difference: The phase difference between the Bus #1 voltage and Generator voltage.";
CM_ SG_ 2365450494 Bus1GeneratorDeadBus "Bus #1/Generator Dead Bus: Indicator of whether Bus #1 is considered dead for closing to the generator. This indicator will be based on parameters such as Bus #1 Voltage and dead bus threshold values.00b = Bus is not dead01b = Bus is dead10b = Error1...";
CM_ SG_ 2365450494 Bus1GeneratorFrequencyMatch "Bus #1/Generator Frequency Match: Indicator of whether frequency difference between Bus #1 and Generator is adequate for paralleling. This indicator will be based on the measured AC frequencies qualified using parameters such as Frequency Tolerance, ...";
CM_ SG_ 2365450494 Bus1GeneratorInSync "Bus #1/Generator In Sync: Indicator of whether Bus #1 and Generator are properly synchronized for paralleling. This indicator will be based on parameters such as Voltage Match, Frequency Match, and Phase Match.00b = Not synchronized01b = Synchronized...";
CM_ SG_ 2365450494 Bus1GeneratorPhaseMatch "Bus #1/Generator Phase Match: Indicator of whether phase difference between Bus #1 and Generator is adequate for paralleling. This indicator will be based on the measured AC phase difference qualified using parameters such as Phase Tolerance and Dwel...";
CM_ SG_ 2365450494 Bus1GeneratorVoltageMatch "Bus #1/Generator Voltage Match: Indicator of whether voltage difference between Bus #1 and Generator is adequate for paralleling. This indicator will be based on the measured AC voltages qualified using parameters such as Voltage Tolerance.00b = Volt...";
CM_ BO_ 2365450750 "Bus #1 Phase C  Basic AC Quantities";
CM_ SG_ 2365450750 Bs1PhsCLnNtrlACRMSVltg "Bus #1 Phase C Line-Neutral AC RMS Voltage: Line to Neutral RMS voltage measured at bus #1 phase C.";
CM_ SG_ 2365450750 Bus1PhaseCACFrequency "Bus #1 Phase C AC Frequency: AC frequency measured at bus #1 phase C.";
CM_ SG_ 2365450750 Bus1PhaseCALineLineACRMSVoltage "Bus #1 Phase CA Line-Line AC RMS Voltage: Line to Line RMS voltage measured at bus #1 phase CA.";
CM_ BO_ 2365451006 "Bus #1 Phase B  Basic AC Quantities";
CM_ SG_ 2365451006 Bs1PhsBLnNtrlACRMSVltg "Bus #1 Phase B Line-Neutral AC RMS Voltage: Line to Neutral RMS voltage measured at bus #1 phase B.";
CM_ SG_ 2365451006 Bus1PhaseBACFrequency "Bus #1 Phase B AC Frequency: AC frequency measured at bus #1 phase B.";
CM_ SG_ 2365451006 Bus1PhaseBCLineLineACRMSVoltage "Bus #1 Phase BC Line-Line AC RMS Voltage: Line to Line RMS voltage measured at bus #1 phase BC.";
CM_ BO_ 2365451262 "Bus #1 Phase A  Basic AC Quantities";
CM_ SG_ 2365451262 Bs1PhsALnNtrlACRMSVltg "Bus #1 Phase A Line-Neutral AC RMS Voltage: Line to Neutral RMS voltage measured at bus #1 phase A.";
CM_ SG_ 2365451262 Bus1PhaseAACFrequency "Bus #1 Phase A AC Frequency: AC frequency measured at bus #1 phase A.";
CM_ SG_ 2365451262 Bus1PhaseABLineLineACRMSVoltage "Bus #1 Phase AB Line-Line AC RMS Voltage: Line to Line RMS voltage measured at bus #1 phase AB.";
CM_ BO_ 2365451518 "Bus #1 Average Basic AC Quantities";
CM_ SG_ 2365451518 Bs1AvrgLnNtrlACRMSVltg "Bus #1 Average Line-Neutral AC RMS Voltage: The average Line to Neutral AC RMS voltage measured at bus #1 .";
CM_ SG_ 2365451518 Bus1AverageACFrequency "Bus #1 Average AC Frequency: Average AC frequency measured at bus #1.";
CM_ SG_ 2365451518 Bus1AverageLineLineACRMSVoltage "Bus #1 Average Line-Line AC RMS Voltage: Average Line to Line RMS voltage measured at bus #1 .";
CM_ BO_ 2365451774 "Utility Total AC Energy";
CM_ SG_ 2365451774 UtilityTotalkWHoursExport "Utility Total kW Hours Export: The total kilowatt-hours that have been exported by the utility incomer.";
CM_ SG_ 2365451774 UtilityTotalkWHoursImport "Utility Total kW Hours Import: The total kilowatt-hours that have been imported by the utility incomer.";
CM_ BO_ 2365452030 "Utility Phase C AC Reactive Power";
CM_ SG_ 2365452030 UtilityPhaseCPowerFactor "Utility Phase C Power Factor: The power factor of phases C of the utility incomer.";
CM_ SG_ 2365452030 UtilityPhaseCPowerFactorLagging "Utility Phase C Power Factor Lagging: Lead/lag status for utility incomer phase C power factor.00b = Leading01b = Lagging10b = Error11b = Not Available or Not Installed";
CM_ SG_ 2365452030 UtilityPhaseCReactivePower "Utility Phase C Reactive Power: The reactive power delivered by phase C of the utility incomer";
CM_ BO_ 2365452286 "Utility Phase C AC Power";
CM_ SG_ 2365452286 UtilityPhaseCApparentPower "Utility Phase C Apparent Power: The apparent power delivered by phase C of the utility incomer.";
CM_ SG_ 2365452286 UtilityPhaseCRealPower "Utility Phase C Real Power: The real power delivered by phase C of the utility incomer.";
CM_ BO_ 2365452542 "Utility Phase C AC Basic Quantities";
CM_ SG_ 2365452542 UtilityPhaseCACFrequency "Utility Phase C AC Frequency: AC frequency measured at the utility incomer phase C.";
CM_ SG_ 2365452542 UtilityPhaseCACRMSCurrent "Utility Phase C AC RMS Current: RMS current measured at the utility incomer phase C.";
CM_ SG_ 2365452542 UtltPhsCALnLnACRMSVltg "Utility Phase CA Line-Line AC RMS Voltage: Line to Line RMS voltage measured at the utility incomer phase CA.";
CM_ SG_ 2365452542 UtltPhsCLnNtrlACRMSVltg "Utility Phase C Line-Neutral AC RMS Voltage: Line to Neutral RMS voltage measured at the utility incomer phase C.";
CM_ BO_ 2365452798 "Utility Phase B AC Reactive Power";
CM_ SG_ 2365452798 UtilityPhaseBPowerFactor "Utility Phase B Power Factor: The power factor of phases B of the utility incomer.";
CM_ SG_ 2365452798 UtilityPhaseBPowerFactorLagging "Utility Phase B Power Factor Lagging: Lead/lag status for utility incomer phase B power factor.00b = Leading01b = Lagging10b = Error11b = Not Available or Not Installed";
CM_ SG_ 2365452798 UtilityPhaseBReactivePower "Utility Phase B Reactive Power: The reactive power delivered by phase B of the utility incomer";
CM_ BO_ 2365453054 "Utility Phase B AC Power";
CM_ SG_ 2365453054 UtilityPhaseBApparentPower "Utility Phase B Apparent Power: The apparent power delivered by phase B of the utility incomer.";
CM_ SG_ 2365453054 UtilityPhaseBRealPower "Utility Phase B Real Power: The real power delivered by phase B of the utility incomer.";
CM_ BO_ 2365453310 "Utility Phase B AC Basic Quantities";
CM_ SG_ 2365453310 UtilityPhaseBACFrequency "Utility Phase B AC Frequency: AC frequency measured at the utility incomer phase B.";
CM_ SG_ 2365453310 UtilityPhaseBACRMSCurrent "Utility Phase B AC RMS Current: RMS current measured at the utility incomer phase B.";
CM_ SG_ 2365453310 UtltPhsBCLnLnACRMSVltg "Utility Phase BC Line-Line AC RMS Voltage: Line to Line RMS voltage measured at the utility incomer phase BC.";
CM_ SG_ 2365453310 UtltPhsBLnNtrlACRMSVltg "Utility Phase B Line-Neutral AC RMS Voltage: Line to Neutral RMS voltage measured at the utility incomer phase B.";
CM_ BO_ 2365453566 "Utility Phase A AC Reactive Power";
CM_ SG_ 2365453566 UtilityPhaseAPowerFactor "Utility Phase A Power Factor: The power factor of phase A of the utility incomer.";
CM_ SG_ 2365453566 UtilityPhaseAPowerFactorLagging "Utility Phase A Power Factor Lagging: Lead/lag status for utility incomer phase A power factor.00b = Leading01b = Lagging10b = Error11b = Not Available or Not Installed";
CM_ SG_ 2365453566 UtilityPhaseAReactivePower "Utility Phase A Reactive Power: The reactive power delivered by phase A of the utility incomer";
CM_ BO_ 2365453822 "Utility Phase A AC Power";
CM_ SG_ 2365453822 UtilityPhaseAApparentPower "Utility Phase A Apparent Power: The apparent power delivered by phase A of the utility incomer.";
CM_ SG_ 2365453822 UtilityPhaseARealPower "Utility Phase A Real Power: The real power delivered by phase A of the utility incomer.";
CM_ BO_ 2365454078 "Utility Phase A Basic AC Quantities";
CM_ SG_ 2365454078 UtilityPhaseAACFrequency "Utility Phase A AC Frequency: AC frequency measured at the utility incomer phase A.";
CM_ SG_ 2365454078 UtilityPhaseAACRMSCurrent "Utility Phase A AC RMS Current: RMS current measured at the utility incomer phase A.";
CM_ SG_ 2365454078 UtltPhsABLnLnACRMSVltg "Utility Phase AB Line-Line AC RMS Voltage: Line to Line RMS voltage measured at the utility incomer phase AB.";
CM_ SG_ 2365454078 UtltPhsALnNtrlACRMSVltg "Utility Phase A Line-Neutral AC RMS Voltage: Line to Neutral RMS voltage measured at the utility incomer phase A.";
CM_ BO_ 2365454334 "Utility Total AC Reactive Power";
CM_ SG_ 2365454334 UtilityOverallPowerFactor "Utility Overall Power Factor: The average power factor of the utility incomer.";
CM_ SG_ 2365454334 UtilityTotalReactivePower "Utility Total Reactive Power: The total reactive power delivered by the utility incomer";
CM_ SG_ 2365454334 UtltOvrllPwrFtrLggng "Utility Overall Power Factor Lagging: Lead/lag status for utility incomer average power factor.00b = Leading01b = Lagging10b = Error11b = Not Available or Not Installed";
CM_ BO_ 2365454590 "Utility Total AC Power";
CM_ SG_ 2365454590 UtilityTotalApparentPower "Utility Total Apparent Power: The total apparent power delivered by the utility incomer.";
CM_ SG_ 2365454590 UtilityTotalRealPower "Utility Total Real Power: Total real power delivered by the utility incomer.";
CM_ BO_ 2365454846 "Utility Average Basic AC Quantities";
CM_ SG_ 2365454846 UtilityAverageACFrequency "Utility Average AC Frequency: Average AC frequency measured at the utility incomer.";
CM_ SG_ 2365454846 UtilityAverageACRMSCurrent "Utility Average AC RMS Current: Average RMS current measured at the utility incomer.";
CM_ SG_ 2365454846 UtltAvrgLnLnACRMSVltg "Utility Average Line-Line AC RMS Voltage: Average Line to Line RMS voltage measured at the utility incomer .";
CM_ SG_ 2365454846 UtltAvrgLnNtrlACRMSVltg "Utility Average Line-Neutral AC RMS Voltage: The average Line to Neutral AC RMS voltage measured at the utility incomer .";
CM_ BO_ 2365455102 "Generator Total AC Energy";
CM_ SG_ 2365455102 GeneratorTotalkWHoursExport "Generator Total kW Hours Export: The total kilowatt-hours that have been exported by the generator.";
CM_ SG_ 2365455102 GeneratorTotalkWHoursImport "Generator Total kW Hours Import: The total kilowatt-hours that have been imported by the generator.";
CM_ BO_ 2365455358 "Generator Phase C AC Reactive Power";
CM_ SG_ 2365455358 GeneratorPhaseCPowerFactor "Generator Phase C Power Factor: The power factor of phases C of the generator.";
CM_ SG_ 2365455358 GeneratorPhaseCReactivePower "Generator Phase C Reactive Power: The reactive power delivered by phase C of the generator";
CM_ SG_ 2365455358 GnrtrPhsCPwrFtrLggng "Generator Phase C Power Factor Lagging: Lead/lag status for generator phase C power factor.00b = Leading01b = Lagging10b = Error11b = Not Available or Not Installed";
CM_ BO_ 2365455614 "Generator Phase C AC Power";
CM_ SG_ 2365455614 GeneratorPhaseCApparentPower "Generator Phase C Apparent Power: The apparent power delivered by phase C of the generator.";
CM_ SG_ 2365455614 GeneratorPhaseCRealPower "Generator Phase C Real Power: The real power delivered by phase C of the generator.";
CM_ BO_ 2365455870 "Generator Phase C Basic AC Quantities";
CM_ SG_ 2365455870 GeneratorPhaseCACFrequency "Generator Phase C AC Frequency: AC frequency measured at the generator phase C output.";
CM_ SG_ 2365455870 GeneratorPhaseCACRMSCurrent "Generator Phase C AC RMS Current: RMS current measured at the generator phase C output.";
CM_ SG_ 2365455870 GnrtrPhsCALnLnACRMSVltg "Generator Phase CA Line-Line AC RMS Voltage: Line to Line RMS voltage measured at the generator phase CA output.";
CM_ SG_ 2365455870 GnrtrPhsCLnNtrlACRMSVltg "Generator Phase C Line-Neutral AC RMS Voltage: Line to Neutral RMS voltage measured at the generator phase C output.";
CM_ BO_ 2365456126 "Generator Phase B AC Reactive Power";
CM_ SG_ 2365456126 GeneratorPhaseBPowerFactor "Generator Phase B Power Factor: The power factor of phases B of the generator.";
CM_ SG_ 2365456126 GeneratorPhaseBReactivePower "Generator Phase B Reactive Power: The reactive power delivered by phase B of the generator";
CM_ SG_ 2365456126 GnrtrPhsBPwrFtrLggng "Generator Phase B Power Factor Lagging: Lead/lag status for generator phase B power factor.00b = Leading01b = Lagging10b = Error11b = Not Available or Not Installed";
CM_ BO_ 2365456382 "Generator Phase B AC Power";
CM_ SG_ 2365456382 GeneratorPhaseBApparentPower "Generator Phase B Apparent Power: The apparent power delivered by phase B of the generator.";
CM_ SG_ 2365456382 GeneratorPhaseBRealPower "Generator Phase B Real Power: The real power delivered by phase B of the generator.";
CM_ BO_ 2365456894 "Generator Phase A AC Reactive Power";
CM_ SG_ 2365456894 GeneratorPhaseAPowerFactor "Generator Phase A Power Factor: The power factor of phase A of the generator.";
CM_ SG_ 2365456894 GeneratorPhaseAReactivePower "Generator Phase A Reactive Power: The reactive power delivered by phase A of the generator";
CM_ SG_ 2365456894 GnrtrPhsAPwrFtrLggng "Generator Phase A Power Factor Lagging: Lead/lag status for generator phase A power factor.00b = Leading01b = Lagging10b = Error11b = Not Available or Not Installed";
CM_ BO_ 2365457150 "Generator Phase A AC Power";
CM_ SG_ 2365457150 GeneratorPhaseAApparentPower "Generator Phase A Apparent Power: The apparent power delivered by phase A of the generator.";
CM_ SG_ 2365457150 GeneratorPhaseARealPower "Generator Phase A Real Power: The real power delivered by phase A of the generator.";
CM_ BO_ 2365457406 "Generator Phase A Basic AC Quantities";
CM_ SG_ 2365457406 GeneratorPhaseAACFrequency "Generator Phase A AC Frequency: AC frequency measured at the generator phase A output.";
CM_ SG_ 2365457406 GeneratorPhaseAACRMSCurrent "Generator Phase A AC RMS Current: RMS current measured at the generator phase A output.";
CM_ SG_ 2365457406 GnrtrPhsABLnLnACRMSVltg "Generator Phase AB Line-Line AC RMS Voltage: Line to Line RMS voltage measured at the generator phase AB output.";
CM_ SG_ 2365457406 GnrtrPhsALnNtrlACRMSVltg "Generator Phase A Line-Neutral AC RMS Voltage: Line to Neutral RMS voltage measured at the generator phase A output.";
CM_ BO_ 2365457662 "Generator Total AC Reactive Power";
CM_ SG_ 2365457662 GeneratorOverallPowerFactor "Generator Overall Power Factor: The average power factor of the generator.";
CM_ SG_ 2365457662 GeneratorTotalReactivePower "Generator Total Reactive Power: The total reactive power delivered by the generator";
CM_ SG_ 2365457662 GnrtrOvrllPwrFtrLggng "Generator Overall Power Factor Lagging: Lead/lag status for generator average power factor.00b = Leading01b = Lagging10b = Error11b = Not Available or Not Installed";
CM_ BO_ 2365457918 "Generator Total AC Power";
CM_ SG_ 2365457918 GeneratorTotalApparentPower "Generator Total Apparent Power: The total apparent power delivered by the generator.";
CM_ SG_ 2365457918 GeneratorTotalRealPower "Generator Total Real Power: Total real power delivered by the generator.";
CM_ BO_ 2365458174 "Generator Average Basic AC Quantities";
CM_ SG_ 2365458174 GeneratorAverageACFrequency "Generator Average AC Frequency: Average AC frequency measured at the generator output.";
CM_ SG_ 2365458174 GeneratorAverageACRMSCurrent "Generator Average AC RMS Current: Average RMS current measured at the generator output.";
CM_ SG_ 2365458174 GnrtrAvrgLnLnACRMSVltg "Generator Average Line-Line AC RMS Voltage: Average Line to Line RMS voltage measured at the generator output.";
CM_ SG_ 2365458174 GnrtrAvrgLnNtrlACRMSVltg "Generator Average Line-Neutral AC RMS Voltage: The average Line to Neutral AC RMS voltage measured at the Generator output.";
CM_ BO_ 2365473278 "Lighting Command";
CM_ SG_ 2365473278 AlternateBeamHeadLightCommand "Alternate Beam Head Light Command: Command to activate or de-activate the tractor alternate head lights (only low beam is available on alternate head lights).  The alternate position lights are intended for use with loader and snow plows that tend to...";
CM_ SG_ 2365473278 BackUpLightandAlarmHornCommand "Back Up Light and Alarm Horn Command: Command to activate or de-activate the back up lights and/ or associated alarm if required00b = De-activate01b = Activate10b = Reserved11b = Don't Care";
CM_ SG_ 2365473278 CenterStopLightCommand "Center Stop Light Command: Command to activate or de-activate the tractor and implement center stop light00b = De-activate01b = Activate10b = Reserved11b = Don't Care";
CM_ SG_ 2365473278 HighBeamHeadLightCommand "High Beam Head Light Command: Command to activate or de-activate the tractor high beam head light lamps. 00b = De-activate01b = Activate10b = Reserved11b = Don't Care";
CM_ SG_ 2365473278 ImplementClearanceLightCommand "Implement Clearance Light Command: Command to activate or de-activate the implement high mounted clearance and lights.  00b = De-activate01b = Activate10b = Reserved11b = Don't Care";
CM_ SG_ 2365473278 ImplementMarkerLightCommand "Implement Marker Light Command: Command to activate or de-activate implement front position lights, rear red tail lights, side amber running lights, license plate lights and instrument and switch back lights.  00b = De-activate01b = Activate10b = Res...";
CM_ SG_ 2365473278 ImplementOEMOption1LightCommand "Implement OEM Option 1 Light Command: Command to activate or de-activate an implement OEM option 1 light.  This is provided to meet special needs on implements, such as tank inspection or filling lights.00b = De-activate01b = Activate10b = Reserved11...";
CM_ SG_ 2365473278 ImplementOEMOption2LightCommand "Implement OEM Option 2 Light Command: Command to activate or de-activate an implement OEM option 2 light.  This is provided to meet special needs on implements, such as tank inspection or filling lights.00b = De-activate01b = Activate10b = Reserved11...";
CM_ SG_ 2365473278 ImplementRearWorkLightCommand "Implement Rear Work Light Command: Command to activate or de-activate implement rear work lights.  (This is also the same as Reversing Lights for truck applications.)  00b = De-activate01b = Activate10b = Reserved11b = Don't Care";
CM_ SG_ 2365473278 ImplmntLftFngWrkLghtCmmnd "Implement Left Facing Work Light Command: Command to activate or de-activate the left facing work lights toward the left end of the implement.00b = De-activate01b = Activate10b = Reserved11b = Don't Care";
CM_ SG_ 2365473278 ImplmntLftFrwrdWrkLghtCmmnd "Implement Left Forward Work Light Command: Command to activate or de-activate work lights mounted on an implement to illuminate beyond left end of the implement.00b = De-activate01b = Activate10b = Reserved11b = Don't Care";
CM_ SG_ 2365473278 ImplmntRghtFngWrkLghtCmmnd "Implement Right Facing Work Light Command: Command to activate or de-activate work lights mounted on an implement to illuminate beyond right end of the implement.00b = De-activate01b = Activate10b = Reserved11b = Don't Care";
CM_ SG_ 2365473278 ImplmntRghtFrwrdWrkLghtCmmnd "Implement Right Forward Work Light Command: Command to activate or de-activate the forward facing work lights toward the right end of the implement.00b = De-activate01b = Activate10b = Reserved11b = Don't Care";
CM_ SG_ 2365473278 LeftStopLightCommand "Left Stop Light Command: Command to activate or de-activate the tractor and implement left stop lights00b = De-activate01b = Activate10b = Reserved11b = Don't Care";
CM_ SG_ 2365473278 LeftTurnSignalLightsCommand "Left Turn Signal Lights Command: Command to activate or de-activate left turn signal lights on the tractor and all connected implements00b = De-activate01b = Activate10b = Reserved11b = Don't Care";
CM_ SG_ 2365473278 LightingDataRequestCommand "Lighting Data Request Command: Command to provide a response of the light state00b = De-activate01b = Activate10b = Reserved11b = Don't Care";
CM_ SG_ 2365473278 LowBeamHeadLightCommand "Low Beam Head Light Command: Command to activate or de-activate the tractor low beam head light lamps. 00b = De-activate01b = Activate10b = Reserved11b = Don't Care";
CM_ SG_ 2365473278 RearFogLightCommand "Rear Fog Light Command: Command to activate or de-activate tractor or implement rear fog lights.  00b = De-activate01b = Activate10b = Reserved11b = Don't Care";
CM_ SG_ 2365473278 RightStopLightCommand "Right Stop Light Command: Command to activate or de-activate the tractor and implement right stop light00b = De-activate01b = Activate10b = Reserved11b = Don't Care";
CM_ SG_ 2365473278 RightTurnSignalLightsCommand "Right Turn Signal Lights Command: Command to activate or de-activate right turn signal lights on the tractor and all connected implements00b = De-activate01b = Activate10b = Reserved11b = Don't Care";
CM_ SG_ 2365473278 RotatingBeaconLightCommand "Rotating Beacon Light Command: Command to activate or de-activate slow moving vehicle indicator lights on tractor and/or implements.  Activation of the slow moving vehicle lights implies that the controller should manipulate the lighting as appropria...";
CM_ SG_ 2365473278 RunningLightCommand "Running Light Command: Command to activate or de-activate the tractor or powered vehicle running lights.  Usually only used for on road vehicles.00b = De-activate01b = Activate10b = Reserved11b = Don't Care";
CM_ SG_ 2365473278 TractorClearanceLightCommand "Tractor Clearance Light Command: Command to activate or de-activate the tractor high mounted clearance and center ID lights00b = De-activate01b = Activate10b = Reserved11b = Don't Care";
CM_ SG_ 2365473278 TractorFrontFogLightsCommand "Tractor Front Fog Lights Command: Command to activate or de-activate tractor front fog lights.00b = De-activate01b = Activate10b = Reserved11b = Don't Care";
CM_ SG_ 2365473278 TractorMarkerLightCommand "Tractor Marker Light Command: Command to activate or de-activate tractor and implement front position lights, rear red tail lights, side amber running lights, license plate lights and instrument and switch back lights.  00b = De-activate01b = Activat...";
CM_ SG_ 2365473278 TrtrFrntHghMntdWrkLghtsCmmnd "Tractor Front High Mounted Work Lights Command: Command to activate or de-activate the tractor front high mounted work lights.00b = De-activate01b = Activate10b = Reserved11b = Don't Care";
CM_ SG_ 2365473278 TrtrFrntLwMntdWrkLghtsCmmnd "Tractor Front Low Mounted Work Lights Command: Command to activate or de-activate the tractor front low mounted work lights.00b = De-activate01b = Activate10b = Reserved11b = Don't Care";
CM_ SG_ 2365473278 TrtrRrHghMntdWrkLghtsCmmnd "Tractor Rear High Mounted Work Lights Command: Command to activate or de-activate the tractor rear high  mounted work lights.00b = De-activate01b = Activate10b = Reserved11b = Don't Care";
CM_ SG_ 2365473278 TrtrRrLwMntdWrkLghtsCmmnd "Tractor Rear Low Mounted Work Lights Command: Command to activate or de-activate the tractor rear low  mounted work lights.00b = De-activate01b = Activate10b = Reserved11b = Don't Care";
CM_ SG_ 2365473278 TrtrSdHghMntdWrkLghtsCmmnd "Tractor Side High Mounted Work Lights Command: Command to activate or de-activate the tractor side high mounted work lights.00b = De-activate01b = Activate10b = Reserved11b = Don't Care";
CM_ SG_ 2365473278 TrtrSdLwMntdWrkLghtsCmmnd "Tractor Side Low Mounted Work Lights Command: Command to activate or de-activate the tractor side low mounted work lights.00b = De-activate01b = Activate10b = Reserved11b = Don't Care";
CM_ SG_ 2365473278 TrtrUndrsdMntdWrkLghtsCmmnd "Tractor Underside Mounted Work Lights Command: Command to activate or de-activate the tractor underside mounted work lights.00b = De-activate01b = Activate10b = Reserved11b = Don't Care";
CM_ BO_ 2365478910 "Air Suspension Control 5";
CM_ SG_ 2365478910 DamperStiffnessFrontAxle "Damper Stiffness Front Axle: Damper stiffness information of the shock absorber control at the front axle";
CM_ SG_ 2365478910 DamperStiffnessLiftTagAxle "Damper Stiffness Lift / Tag Axle: Damper stiffness information of the shock absorber control at the lift of tag axle";
CM_ SG_ 2365478910 DamperStiffnessRearAxle "Damper Stiffness Rear Axle: Damper stiffness information of the shock absorber control at the rear axle";
CM_ SG_ 2365478910 EltrnShkAsrrCntrlMdFrntAxl "Electronic Shock Absorber Control Mode -  Front Axle: Signal which indicates the current mode of operation of the electronic shock absorber control at the front axle.00b = Normal operation dampers passive01b = Normal operation dampers active10b = Err...";
CM_ SG_ 2365478910 EltrnShkAsrrCntrlMdLftTgAxl "Electronic Shock Absorber Control Mode - Lift/Tag Axle: Signal which indicates the current mode of operation of the electronic shock absorber control at the lift/tag axle.00b = Normal operation dampers passive01b = Normal operation dampers active10b ...";
CM_ SG_ 2365478910 EltrnShkAsrrCntrlMdRrAxl "Electronic Shock Absorber Control Mode - Rear Axle: Signal which indicates the current mode of operation of the electronic shock absorber control at the rear axle.00b = Normal operation dampers passive01b = Normal operation dampers active10b = Error1...";
CM_ BO_ 2365479678 "Air Suspension Control 1";
CM_ SG_ 2365479678 AboveNominalLevelFrontAxle "Above Nominal Level Front Axle: Signal which indicates whether the actual height of the front axle is above the nominal (desired) level of the front axle. For explanations of nominal level see SPN 1734 - Nominal Level Front Axle.00b = Not above01b = ...";
CM_ SG_ 2365479678 AboveNominalLevelRearAxle "Above Nominal Level Rear Axle: Signal which indicates whether the actual height of the rear axle is above the nominal (desired) level of the rear axle. For explanations of nominal level see parameter SPN 1734 - Nominal Level Front Axle.00b = Not abov...";
CM_ SG_ 2365479678 AllwLvlCntrlDrngBrkngStts "Allow Level Control During Braking Status: This parameter indicates if the function Allow Level Control During Braking is active. Functions is activated by SPN 5293.00b = Deactivated01b = Activated10b = Reserved11b = Don't care/take no action...";
CM_ SG_ 2365479678 BelowNominalLevelFrontAxle "Below Nominal Level Front Axle: Signal which indicates whether the actual height of the front axle is below the nominal (desired) level for the front axle. For explanations of nominal level see parameter SPN 1734 - Nominal Level Front Axle.00b = Not ...";
CM_ SG_ 2365479678 BelowNominalLevelRearAxle "Below Nominal Level Rear Axle: Signal which indicates whether the actual height of the rear axle is below the nominal (desired) level for the rear axle. For explanations of nominal level see SPN 1734 - Nominal Level Front Axle.00b = Not below01b = Be...";
CM_ SG_ 2365479678 DoorRelease "Door Release: Signal which indicates that the doors may be opened. [Please note: doors instead of door!]In case a kneeling request is active the ASC indicates during lowering the vehicle doors shall not be opened as a security information until the k...";
CM_ SG_ 2365479678 FrontAxleinBumperRange "Front Axle in Bumper Range: Signal which indicates that the vehicle height at the front axle (SPNs 1721 and 1722) is within the bumper range.00b = Actual level out of bumper range01b = Actual level within bumper range10b = Error11b = Not available...";
CM_ SG_ 2365479678 KneelingInformation "Kneeling Information: Signal which indicates the actual level change in case of kneeling function0000b = Not active,(i.e. the kneeling function is not active)0001b = Lowering active,(i.e. the vehicle is lowered due to a kneeling request)0010b = Kneel...";
CM_ SG_ 2365479678 LevelControlMode "Level Control Mode: Signal which indicates the actual control mode of the air suspension system0000b = Normal operation; i.e. the system performs a pure control of the vehicle height0001b = Traction help (load transfer); i.e. the driven axle is loade...";
CM_ SG_ 2365479678 LiftAxle1Position "Lift Axle 1 Position: Signal which indicates the position / load condition of lift axle / tag axle 1.   Numbering of lift/tag axles starts at front axle.  See SPN 6843 for more detail.00b = Lift axle position down / tag axle laden01b = Lift axle posi...";
CM_ SG_ 2365479678 LiftAxle2Position "Lift Axle 2 Position: Signal which indicates the position / load condition of lift axle / tag axle #2.   Numbering of lift/tag axles starts at front axle.  See SPN 6844 for more detail.00b = Lift axle position down / tag axle laden01b = Lift axle pos...";
CM_ SG_ 2365479678 LiftingControlModeFrontAxle "Lifting Control Mode Front Axle: Signal which indicates the actual lifting level change at the front axle00b = Lifting not active01b = Lifting active10b = Error11b = Not available";
CM_ SG_ 2365479678 LiftingControlModeRearAxle "Lifting Control Mode Rear Axle: Signal which indicates the actual lifting level change at the rear axle00b = Lifting not active01b = Lifting active10b = Error11b = Not available";
CM_ SG_ 2365479678 LoweringControlModeFrontAxle "Lowering Control Mode Front Axle: Signal which indicates the actual lowering level change at the front axle00b = Lowering not active01b = Lowering active10b = Error11b = Not available";
CM_ SG_ 2365479678 LoweringControlModeRearAxle "Lowering Control Mode Rear Axle: Signal which indicates the actual lowering level change at the rear axle00b = Lowering not active01b = Lowering active10b = Error11b = Not available";
CM_ SG_ 2365479678 Memorylevel "Memory level: Signal which indicates that the air suspension control has memory levels selected or stored.Response to memory level request in ASC2 (byte 8.5). If the request was executed the respective status will be set. If the request was not execu...";
CM_ SG_ 2365479678 NominalLevelFrontAxle "Nominal Level Front Axle: Signal which indicates the nominal (desired) height of the front axle to be controlled by the suspension system.These heights are discrete levels.  They are the upper level, lower level, normal level 1, normal level 2, norma...";
CM_ SG_ 2365479678 NominalLevelRearAxle "Nominal Level Rear Axle: Signal which indicates the nominal (desired) height of the rear axle to be controlled by the suspension system.For further explanations see SPN 1734 - Nominal Level Front Axle.0000b = Level not specified,(i.e. the nominal lev...";
CM_ SG_ 2365479678 RearAxleinBumperRange "Rear Axle in Bumper Range: Signal which indicates that the vehicle height at the rear axle (SPNs 1723 and 1724) is within the bumper range.00b = Actual level out of bumper range01b = Actual level within bumper range10b = Error11b = Not available...";
CM_ SG_ 2365479678 SecurityDevice "Security Device: The signal which indicates the status of the security device.  An example of a security device is a curbstone feeler installed beneath the doors of a bus. If the security device becomes active during kneeling the kneeling process (lo...";
CM_ SG_ 2365479678 SpdDpndntLvlCntrlStts "Speed Dependant Level Control Status: This parameter indicates if the function Speed Dependant Level Control is active. The function is activated by SPN 5295.00b = Inactive01b = Active10b = Reserved11b = Don't' care/take no action";
CM_ SG_ 2365479678 SspnsnCntrlRfslInfrmtn "Suspension Control Refusal Information: Signal which indicates that the air suspension control cannot perform a request due to the operating conditions. It also provides a reason for the refusal.0000b = Actual request not refused0001b = Axle load lim...";
CM_ SG_ 2365479678 SuspensionRemoteControl1 "Suspension Remote Control 1: Signal which indicates that the suspension system is controlled by remote control #1. Remote control is an external unit to operate the suspension system.00b = Not active01b = Active10b = Error11b = Not available...";
CM_ SG_ 2365479678 SuspensionRemotecontrol2 "Suspension Remote control 2: Signal which indicates that the suspension system is controlled by remote control #2. Remote control is an external unit to operate the suspension system.00b = Not active01b = Active10b = Error11b = Not available...";
CM_ SG_ 2365479678 VehicleMotionInhibit "Vehicle Motion Inhibit: Signal which indicates whether vehicle motion is inhibited.00b = Vehicle may be moved01b = Vehicle motion is inhibited10b = Error11b = Not available";
BA_DEF_ SG_  "SPN" INT 0 524287;
BA_DEF_ BO_  "VFrameFormat" ENUM  "StandardCAN","ExtendedCAN","reserved","J1939PG";
BA_DEF_DEF_  "SPN" 0;
BA_DEF_DEF_  "VFrameFormat" "J1939PG";
BA_ "SPN" SG_ 2365402622 Joystick5Button13PressedStatus 6747;
BA_ "SPN" SG_ 2365402622 Joystick5Button14PressedStatus 6748;
BA_ "SPN" SG_ 2365402622 Joystick5Button15PressedStatus 6749;
BA_ "SPN" SG_ 2365402622 Joystick5Button16PressedStatus 6750;
BA_ "SPN" SG_ 2365402622 Joystick5GripXAxisPosition 4553;
BA_ "SPN" SG_ 2365402622 Joystick5GripYAxisPosition 4557;
BA_ "SPN" SG_ 2365402622 Joystick5ThetaAxisPosition 4561;
BA_ "SPN" SG_ 2365402622 Jst5GpYAxsLvFwdPstvPstStts 4556;
BA_ "SPN" SG_ 2365402622 Jst5TtAxsCtCwsNtvPstStts 4559;
BA_ "SPN" SG_ 2365402622 Jstk5GrpXAxsDtntPstnStts 4564;
BA_ "SPN" SG_ 2365402622 Jstk5GrpXAxsLvrLftNgtvPstnStts 4551;
BA_ "SPN" SG_ 2365402622 Jstk5GrpXAxsLvrRghtPstvPstnStts 4552;
BA_ "SPN" SG_ 2365402622 Jstk5GrpXAxsNtrlPstnStts 4550;
BA_ "SPN" SG_ 2365402622 Jstk5GrpYAxsDtntPstnStts 4563;
BA_ "SPN" SG_ 2365402622 Jstk5GrpYAxsLvrBkNgtvPstnStts 4555;
BA_ "SPN" SG_ 2365402622 Jstk5GrpYAxsNtrlPstnStts 4554;
BA_ "SPN" SG_ 2365402622 Jstk5ThtAxsClkwsPstvPstnStts 4560;
BA_ "SPN" SG_ 2365402622 Jstk5ThtAxsDtntPstnStts 4562;
BA_ "SPN" SG_ 2365402622 Jstk5ThtAxsNtrlPstnStts 4558;
BA_ "SPN" SG_ 2365402878 Joystick5Button10PressedStatus 4548;
BA_ "SPN" SG_ 2365402878 Joystick5Button11PressedStatus 4547;
BA_ "SPN" SG_ 2365402878 Joystick5Button12PressedStatus 4546;
BA_ "SPN" SG_ 2365402878 Joystick5Button1PressedStatus 4541;
BA_ "SPN" SG_ 2365402878 Joystick5Button2PressedStatus 4540;
BA_ "SPN" SG_ 2365402878 Joystick5Button3PressedStatus 4539;
BA_ "SPN" SG_ 2365402878 Joystick5Button4PressedStatus 4538;
BA_ "SPN" SG_ 2365402878 Joystick5Button5PressedStatus 4545;
BA_ "SPN" SG_ 2365402878 Joystick5Button6PressedStatus 4544;
BA_ "SPN" SG_ 2365402878 Joystick5Button7PressedStatus 4543;
BA_ "SPN" SG_ 2365402878 Joystick5Button8PressedStatus 4542;
BA_ "SPN" SG_ 2365402878 Joystick5Button9PressedStatus 4549;
BA_ "SPN" SG_ 2365402878 Joystick5XAxisPosition 4531;
BA_ "SPN" SG_ 2365402878 Joystick5YAxisPosition 4535;
BA_ "SPN" SG_ 2365402878 Jstk5XAxsDtntPstnStts 4537;
BA_ "SPN" SG_ 2365402878 Jstk5XAxsLvrLftNgtvPstnStts 4529;
BA_ "SPN" SG_ 2365402878 Jstk5XAxsLvrRghtPstvPstnStts 4530;
BA_ "SPN" SG_ 2365402878 Jstk5XAxsNtrlPstnStts 4528;
BA_ "SPN" SG_ 2365402878 Jstk5YAxsDtntPstnStts 4536;
BA_ "SPN" SG_ 2365402878 Jstk5YAxsLvrBkNgtvPstnStts 4533;
BA_ "SPN" SG_ 2365402878 Jstk5YAxsLvrFrwrdPstvPstnStts 4534;
BA_ "SPN" SG_ 2365402878 Jstk5YAxsNtrlPstnStts 4532;
BA_ "SPN" SG_ 2365403134 Joystick4Button13PressedStatus 6743;
BA_ "SPN" SG_ 2365403134 Joystick4Button14PressedStatus 6744;
BA_ "SPN" SG_ 2365403134 Joystick4Button15PressedStatus 6745;
BA_ "SPN" SG_ 2365403134 Joystick4Button16PressedStatus 6746;
BA_ "SPN" SG_ 2365403134 Joystick4GripXAxisPosition 4516;
BA_ "SPN" SG_ 2365403134 Joystick4GripYAxisPosition 4520;
BA_ "SPN" SG_ 2365403134 Joystick4ThetaAxisPosition 4524;
BA_ "SPN" SG_ 2365403134 Jst4GpYAxsLvFwdPstvPstStts 4519;
BA_ "SPN" SG_ 2365403134 Jst4TtAxsCtCwsNtvPstStts 4522;
BA_ "SPN" SG_ 2365403134 Jstk4GrpXAxsDtntPstnStts 4527;
BA_ "SPN" SG_ 2365403134 Jstk4GrpXAxsLvrLftNgtvPstnStts 4514;
BA_ "SPN" SG_ 2365403134 Jstk4GrpXAxsLvrRghtPstvPstnStts 4515;
BA_ "SPN" SG_ 2365403134 Jstk4GrpXAxsNtrlPstnStts 4513;
BA_ "SPN" SG_ 2365403134 Jstk4GrpYAxsDtntPstnStts 4526;
BA_ "SPN" SG_ 2365403134 Jstk4GrpYAxsLvrBkNgtvPstnStts 4518;
BA_ "SPN" SG_ 2365403134 Jstk4GrpYAxsNtrlPstnStts 4517;
BA_ "SPN" SG_ 2365403134 Jstk4ThtAxsClkwsPstvPstnStts 4523;
BA_ "SPN" SG_ 2365403134 Jstk4ThtAxsDtntPstnStts 4525;
BA_ "SPN" SG_ 2365403134 Jstk4ThtAxsNtrlPstnStts 4521;
BA_ "SPN" SG_ 2365403390 Joystick4Button10PressedStatus 4511;
BA_ "SPN" SG_ 2365403390 Joystick4Button11PressedStatus 4510;
BA_ "SPN" SG_ 2365403390 Joystick4Button12PressedStatus 4509;
BA_ "SPN" SG_ 2365403390 Joystick4Button1PressedStatus 4504;
BA_ "SPN" SG_ 2365403390 Joystick4Button2PressedStatus 4503;
BA_ "SPN" SG_ 2365403390 Joystick4Button3PressedStatus 4502;
BA_ "SPN" SG_ 2365403390 Joystick4Button4PressedStatus 4501;
BA_ "SPN" SG_ 2365403390 Joystick4Button5PressedStatus 4508;
BA_ "SPN" SG_ 2365403390 Joystick4Button6PressedStatus 4507;
BA_ "SPN" SG_ 2365403390 Joystick4Button7PressedStatus 4506;
BA_ "SPN" SG_ 2365403390 Joystick4Button8PressedStatus 4505;
BA_ "SPN" SG_ 2365403390 Joystick4Button9PressedStatus 4512;
BA_ "SPN" SG_ 2365403390 Joystick4XAxisPosition 4494;
BA_ "SPN" SG_ 2365403390 Joystick4YAxisPosition 4498;
BA_ "SPN" SG_ 2365403390 Jstk4XAxsDtntPstnStts 4500;
BA_ "SPN" SG_ 2365403390 Jstk4XAxsLvrLftNgtvPstnStts 4492;
BA_ "SPN" SG_ 2365403390 Jstk4XAxsLvrRghtPstvPstnStts 4493;
BA_ "SPN" SG_ 2365403390 Jstk4XAxsNtrlPstnStts 4491;
BA_ "SPN" SG_ 2365403390 Jstk4YAxsDtntPstnStts 4499;
BA_ "SPN" SG_ 2365403390 Jstk4YAxsLvrBkNgtvPstnStts 4496;
BA_ "SPN" SG_ 2365403390 Jstk4YAxsLvrFrwrdPstvPstnStts 4497;
BA_ "SPN" SG_ 2365403390 Jstk4YAxsNtrlPstnStts 4495;
BA_ "SPN" SG_ 2365428478 EngineControlledShutdownRequest 3606;
BA_ "SPN" SG_ 2365428478 EngineCoolantPumpControl 3605;
BA_ "SPN" SG_ 2365428478 EngineDerateRequest 3644;
BA_ "SPN" SG_ 2365428478 EngineDesiredTorqueRequest 6807;
BA_ "SPN" SG_ 2365428478 EngineFuelShutoff1Control 632;
BA_ "SPN" SG_ 2365428478 EngineFuelShutoff2Control 2807;
BA_ "SPN" SG_ 2365428478 EngineFuelShutoffVentControl 3608;
BA_ "SPN" SG_ 2365428478 EngineOilPreheaterControl 3602;
BA_ "SPN" SG_ 2365428478 EngineOilPrimingPumpControl 3589;
BA_ "SPN" SG_ 2365428478 EngineOperatingState 3543;
BA_ "SPN" SG_ 2365428478 EnginePreHeaterControl 3604;
BA_ "SPN" SG_ 2365428478 EngineStarterMotorRelayControl 6385;
BA_ "SPN" SG_ 2365428478 EngnCldAmntElvtdIdlStts 6884;
BA_ "SPN" SG_ 2365428478 EngnEltrlSstmPwrCnsrvtnCntrl 3603;
BA_ "SPN" SG_ 2365428478 EngnEmrgnImmdtShtdwnIndtn 3607;
BA_ "SPN" SG_ 2365428478 EngnFlShtffVlvLkTstCntrl 3601;
BA_ "SPN" SG_ 2365428478 FuelPumpPrimerControl 4082;
BA_ "SPN" SG_ 2365428478 TmRmnngnEngnOprtngStt 3544;
BA_ "SPN" SG_ 2365428734 EngineSpeedGovernorDroop 5568;
BA_ "SPN" SG_ 2365428734 EngineSpeedGovernorGainAdjust 5567;
BA_ "SPN" SG_ 2365428734 GeneratorAlternatorEfficiency 4078;
BA_ "SPN" SG_ 2365428734 GeneratorFrequencySelection 4080;
BA_ "SPN" SG_ 2365428734 GeneratorGoverningSpeedCommand 4079;
BA_ "SPN" SG_ 2365428734 GnrtrCntrlNtInAtmtStrtStt 3567;
BA_ "SPN" SG_ 2365428734 GnrtrNtRdtAtmtllPrlllStt 3568;
BA_ "SPN" SG_ 2365428734 RequestedEngineControlMode 3542;
BA_ "SPN" SG_ 2365433598 GeneratorExcitationFieldCurrent 3381;
BA_ "SPN" SG_ 2365433598 GeneratorExcitationFieldVoltage 3380;
BA_ "SPN" SG_ 2365433598 GnrtrOtptVltgBsPrntg 3382;
BA_ "SPN" SG_ 2365443326 HazardLightSwitch 2875;
BA_ "SPN" SG_ 2365443326 HighLowBeamSwitch 2874;
BA_ "SPN" SG_ 2365443326 MainLightSwitch 2872;
BA_ "SPN" SG_ 2365443326 OperatorsDesiredBacklight 2878;
BA_ "SPN" SG_ 2365443326 OprtrsDsrdDldLmpOffTm 2877;
BA_ "SPN" SG_ 2365443326 TurnSignalSwitch 2876;
BA_ "SPN" SG_ 2365443326 WorkLightSwitch 2873;
BA_ "SPN" SG_ 2365443326 ExteriorLampCheckSwitch 4004;
BA_ "SPN" SG_ 2365443326 HeadlampEmergencyFlashSwitch 12308;
BA_ "SPN" SG_ 2365443326 AuxiliaryLampGroupSwitch 12964;
BA_ "SPN" SG_ 2365445886 Joystick1Button10PressedStatus 2694;
BA_ "SPN" SG_ 2365445886 Joystick1Button11PressedStatus 2695;
BA_ "SPN" SG_ 2365445886 Joystick1Button12PressedStatus 2696;
BA_ "SPN" SG_ 2365445886 Joystick1Button1PressedStatus 2685;
BA_ "SPN" SG_ 2365445886 Joystick1Button2PressedStatus 2686;
BA_ "SPN" SG_ 2365445886 Joystick1Button3PressedStatus 2687;
BA_ "SPN" SG_ 2365445886 Joystick1Button4PressedStatus 2688;
BA_ "SPN" SG_ 2365445886 Joystick1Button5PressedStatus 2689;
BA_ "SPN" SG_ 2365445886 Joystick1Button6PressedStatus 2690;
BA_ "SPN" SG_ 2365445886 Joystick1Button7PressedStatus 2691;
BA_ "SPN" SG_ 2365445886 Joystick1Button8PressedStatus 2692;
BA_ "SPN" SG_ 2365445886 Joystick1Button9PressedStatus 2693;
BA_ "SPN" SG_ 2365445886 Joystick1XAxisPosition 2660;
BA_ "SPN" SG_ 2365445886 Joystick1YAxisPosition 2661;
BA_ "SPN" SG_ 2365445886 Jstk1XAxsDtntPstnStts 2680;
BA_ "SPN" SG_ 2365445886 Jstk1XAxsLvrLftNgtvPstnStts 2670;
BA_ "SPN" SG_ 2365445886 Jstk1XAxsLvrRghtPstvPstnStts 2665;
BA_ "SPN" SG_ 2365445886 Jstk1XAxsNtrlPstnStts 2675;
BA_ "SPN" SG_ 2365445886 Jstk1YAxsDtntPstnStts 2681;
BA_ "SPN" SG_ 2365445886 Jstk1YAxsLvrBkNgtvPstnStts 2671;
BA_ "SPN" SG_ 2365445886 Jstk1YAxsLvrFrwrdPstvPstnStts 2666;
BA_ "SPN" SG_ 2365445886 Jstk1YAxsNtrlPstnStts 2676;
BA_ "SPN" SG_ 2365446142 Joystick1Button13PressedStatus 6731;
BA_ "SPN" SG_ 2365446142 Joystick1Button14PressedStatus 6732;
BA_ "SPN" SG_ 2365446142 Joystick1Button15PressedStatus 6733;
BA_ "SPN" SG_ 2365446142 Joystick1Button16PressedStatus 6734;
BA_ "SPN" SG_ 2365446142 Joystick1GripXAxisPosition 2662;
BA_ "SPN" SG_ 2365446142 Joystick1GripYAxisPosition 2663;
BA_ "SPN" SG_ 2365446142 Joystick1ThetaAxisPosition 2664;
BA_ "SPN" SG_ 2365446142 Jst1GpYAxsLvFwdPstvPstStts 2668;
BA_ "SPN" SG_ 2365446142 Jst1TtAxsCtCwsNtvPstStts 2674;
BA_ "SPN" SG_ 2365446142 Jstk1GrpXAxsDtntPstnStts 2682;
BA_ "SPN" SG_ 2365446142 Jstk1GrpXAxsLvrLftNgtvPstnStts 2672;
BA_ "SPN" SG_ 2365446142 Jstk1GrpXAxsLvrRghtPstvPstnStts 2667;
BA_ "SPN" SG_ 2365446142 Jstk1GrpXAxsNtrlPstnStts 2677;
BA_ "SPN" SG_ 2365446142 Jstk1GrpYAxsDtntPstnStts 2683;
BA_ "SPN" SG_ 2365446142 Jstk1GrpYAxsLvrBkNgtvPstnStts 2673;
BA_ "SPN" SG_ 2365446142 Jstk1GrpYAxsNtrlPstnStts 2678;
BA_ "SPN" SG_ 2365446142 Jstk1ThtAxsClkwsPstvPstnStts 2669;
BA_ "SPN" SG_ 2365446142 Jstk1ThtAxsDtntPstnStts 2684;
BA_ "SPN" SG_ 2365446142 Jstk1ThtAxsNtrlPstnStts 2679;
BA_ "SPN" SG_ 2365446398 Joystick2Button10PressedStatus 2731;
BA_ "SPN" SG_ 2365446398 Joystick2Button11PressedStatus 2732;
BA_ "SPN" SG_ 2365446398 Joystick2Button12PressedStatus 2733;
BA_ "SPN" SG_ 2365446398 Joystick2Button1PressedStatus 2722;
BA_ "SPN" SG_ 2365446398 Joystick2Button2PressedStatus 2723;
BA_ "SPN" SG_ 2365446398 Joystick2Button3PressedStatus 2724;
BA_ "SPN" SG_ 2365446398 Joystick2Button4PressedStatus 2725;
BA_ "SPN" SG_ 2365446398 Joystick2Button5PressedStatus 2726;
BA_ "SPN" SG_ 2365446398 Joystick2Button6PressedStatus 2727;
BA_ "SPN" SG_ 2365446398 Joystick2Button7PressedStatus 2728;
BA_ "SPN" SG_ 2365446398 Joystick2Button8PressedStatus 2729;
BA_ "SPN" SG_ 2365446398 Joystick2Button9PressedStatus 2730;
BA_ "SPN" SG_ 2365446398 Joystick2XAxisPosition 2697;
BA_ "SPN" SG_ 2365446398 Joystick2YAxisPosition 2698;
BA_ "SPN" SG_ 2365446398 Jstk2XAxsDtntPstnStts 2717;
BA_ "SPN" SG_ 2365446398 Jstk2XAxsLvrLftNgtvPstnStts 2707;
BA_ "SPN" SG_ 2365446398 Jstk2XAxsLvrRghtPstvPstnStts 2702;
BA_ "SPN" SG_ 2365446398 Jstk2XAxsNtrlPstnStts 2712;
BA_ "SPN" SG_ 2365446398 Jstk2YAxsDtntPstnStts 2718;
BA_ "SPN" SG_ 2365446398 Jstk2YAxsLvrBkNgtvPstnStts 2708;
BA_ "SPN" SG_ 2365446398 Jstk2YAxsLvrFrwrdPstvPstnStts 2703;
BA_ "SPN" SG_ 2365446398 Jstk2YAxsNtrlPstnStts 2713;
BA_ "SPN" SG_ 2365446654 Joystick2Button13PressedStatus 6735;
BA_ "SPN" SG_ 2365446654 Joystick2Button14PressedStatus 6736;
BA_ "SPN" SG_ 2365446654 Joystick2Button15PressedStatus 6737;
BA_ "SPN" SG_ 2365446654 Joystick2Button16PressedStatus 6738;
BA_ "SPN" SG_ 2365446654 Joystick2GripXAxisPosition 2699;
BA_ "SPN" SG_ 2365446654 Joystick2GripYAxisPosition 2700;
BA_ "SPN" SG_ 2365446654 Joystick2ThetaAxisPosition 2701;
BA_ "SPN" SG_ 2365446654 Jst2GpYAxsLvFwdPstvPstStts 2705;
BA_ "SPN" SG_ 2365446654 Jst2TtAxsCtCwsNtvPstStts 2711;
BA_ "SPN" SG_ 2365446654 Jstk2GrpXAxsDtntPstnStts 2719;
BA_ "SPN" SG_ 2365446654 Jstk2GrpXAxsLvrLftNgtvPstnStts 2709;
BA_ "SPN" SG_ 2365446654 Jstk2GrpXAxsLvrRghtPstvPstnStts 2704;
BA_ "SPN" SG_ 2365446654 Jstk2GrpXAxsNtrlPstnStts 2714;
BA_ "SPN" SG_ 2365446654 Jstk2GrpYAxsDtntPstnStts 2720;
BA_ "SPN" SG_ 2365446654 Jstk2GrpYAxsLvrBkNgtvPstnStts 2710;
BA_ "SPN" SG_ 2365446654 Jstk2GrpYAxsNtrlPstnStts 2715;
BA_ "SPN" SG_ 2365446654 Jstk2ThtAxsClkwsPstvPstnStts 2706;
BA_ "SPN" SG_ 2365446654 Jstk2ThtAxsDtntPstnStts 2721;
BA_ "SPN" SG_ 2365446654 Jstk2ThtAxsNtrlPstnStts 2716;
BA_ "SPN" SG_ 2365446910 Joystick3Button10PressedStatus 2768;
BA_ "SPN" SG_ 2365446910 Joystick3Button11PressedStatus 2769;
BA_ "SPN" SG_ 2365446910 Joystick3Button12PressedStatus 2770;
BA_ "SPN" SG_ 2365446910 Joystick3Button1PressedStatus 2759;
BA_ "SPN" SG_ 2365446910 Joystick3Button2PressedStatus 2760;
BA_ "SPN" SG_ 2365446910 Joystick3Button3PressedStatus 2761;
BA_ "SPN" SG_ 2365446910 Joystick3Button4PressedStatus 2762;
BA_ "SPN" SG_ 2365446910 Joystick3Button5PressedStatus 2763;
BA_ "SPN" SG_ 2365446910 Joystick3Button6PressedStatus 2764;
BA_ "SPN" SG_ 2365446910 Joystick3Button7PressedStatus 2765;
BA_ "SPN" SG_ 2365446910 Joystick3Button8PressedStatus 2766;
BA_ "SPN" SG_ 2365446910 Joystick3Button9PressedStatus 2767;
BA_ "SPN" SG_ 2365446910 Joystick3XAxisPosition 2734;
BA_ "SPN" SG_ 2365446910 Joystick3YAxisPosition 2735;
BA_ "SPN" SG_ 2365446910 Jstk3XAxsDtntPstnStts 2754;
BA_ "SPN" SG_ 2365446910 Jstk3XAxsLvrLftNgtvPstnStts 2744;
BA_ "SPN" SG_ 2365446910 Jstk3XAxsLvrRghtPstvPstnStts 2739;
BA_ "SPN" SG_ 2365446910 Jstk3XAxsNtrlPstnStts 2749;
BA_ "SPN" SG_ 2365446910 Jstk3YAxsDtntPstnStts 2755;
BA_ "SPN" SG_ 2365446910 Jstk3YAxsLvrBkNgtvPstnStts 2745;
BA_ "SPN" SG_ 2365446910 Jstk3YAxsLvrFrwrdPstvPstnStts 2740;
BA_ "SPN" SG_ 2365446910 Jstk3YAxsNtrlPstnStts 2750;
BA_ "SPN" SG_ 2365447166 Joystick3Button13PressedStatus 6739;
BA_ "SPN" SG_ 2365447166 Joystick3Button14PressedStatus 6740;
BA_ "SPN" SG_ 2365447166 Joystick3Button15PressedStatus 6741;
BA_ "SPN" SG_ 2365447166 Joystick3Button16PressedStatus 6742;
BA_ "SPN" SG_ 2365447166 Joystick3GripXAxisPosition 2736;
BA_ "SPN" SG_ 2365447166 Joystick3GripYAxisPosition 2737;
BA_ "SPN" SG_ 2365447166 Joystick3ThetaAxisPosition 2738;
BA_ "SPN" SG_ 2365447166 Jst3GpYAxsLvFwdPstvPstStts 2742;
BA_ "SPN" SG_ 2365447166 Jst3TtAxsCtCwsNtvPstStts 2748;
BA_ "SPN" SG_ 2365447166 Jstk3GrpXAxsDtntPstnStts 2756;
BA_ "SPN" SG_ 2365447166 Jstk3GrpXAxsLvrLftNgtvPstnStts 2746;
BA_ "SPN" SG_ 2365447166 Jstk3GrpXAxsLvrRghtPstvPstnStts 2741;
BA_ "SPN" SG_ 2365447166 Jstk3GrpXAxsNtrlPstnStts 2751;
BA_ "SPN" SG_ 2365447166 Jstk3GrpYAxsDtntPstnStts 2757;
BA_ "SPN" SG_ 2365447166 Jstk3GrpYAxsLvrBkNgtvPstnStts 2747;
BA_ "SPN" SG_ 2365447166 Jstk3GrpYAxsNtrlPstnStts 2752;
BA_ "SPN" SG_ 2365447166 Jstk3ThtAxsClkwsPstvPstnStts 2743;
BA_ "SPN" SG_ 2365447166 Jstk3ThtAxsDtntPstnStts 2758;
BA_ "SPN" SG_ 2365447166 Jstk3ThtAxsNtrlPstnStts 2753;
BA_ "SPN" SG_ 2365449982 HdrlBrkPrssrSpplSttCrt1 2582;
BA_ "SPN" SG_ 2365449982 HdrlBrkPrssrSpplSttCrt2 2583;
BA_ "SPN" SG_ 2365449982 HdrlBrkPrssrWrnngSttCrt1 2584;
BA_ "SPN" SG_ 2365449982 HdrlBrkPrssrWrnngSttCrt2 2585;
BA_ "SPN" SG_ 2365449982 HdrlBrkSstmAdlWrnngCmmnd 2930;
BA_ "SPN" SG_ 2365449982 HydraulicBrakeFluidLevelSwitch 2931;
BA_ "SPN" SG_ 2365449982 HydraulicBrakePressureCircuit1 2580;
BA_ "SPN" SG_ 2365449982 HydraulicBrakePressureCircuit2 2581;
BA_ "SPN" SG_ 2365450238 Bus1UtilityACPhaseDifference 2517;
BA_ "SPN" SG_ 2365450238 Bus1UtilityDeadBus 2535;
BA_ "SPN" SG_ 2365450238 Bus1UtilityFrequencyMatch 2533;
BA_ "SPN" SG_ 2365450238 Bus1UtilityInSync 2534;
BA_ "SPN" SG_ 2365450238 Bus1UtilityPhaseMatch 2531;
BA_ "SPN" SG_ 2365450238 Bus1UtilityVoltageMatch 2532;
BA_ "SPN" SG_ 2365450494 Bus1GeneratorACPhaseDifference 2516;
BA_ "SPN" SG_ 2365450494 Bus1GeneratorDeadBus 2530;
BA_ "SPN" SG_ 2365450494 Bus1GeneratorFrequencyMatch 2528;
BA_ "SPN" SG_ 2365450494 Bus1GeneratorInSync 2529;
BA_ "SPN" SG_ 2365450494 Bus1GeneratorPhaseMatch 2526;
BA_ "SPN" SG_ 2365450494 Bus1GeneratorVoltageMatch 2527;
BA_ "SPN" SG_ 2365450750 Bs1PhsCLnNtrlACRMSVltg 2515;
BA_ "SPN" SG_ 2365450750 Bus1PhaseCACFrequency 2507;
BA_ "SPN" SG_ 2365450750 Bus1PhaseCALineLineACRMSVoltage 2511;
BA_ "SPN" SG_ 2365451006 Bs1PhsBLnNtrlACRMSVltg 2514;
BA_ "SPN" SG_ 2365451006 Bus1PhaseBACFrequency 2506;
BA_ "SPN" SG_ 2365451006 Bus1PhaseBCLineLineACRMSVoltage 2510;
BA_ "SPN" SG_ 2365451262 Bs1PhsALnNtrlACRMSVltg 2513;
BA_ "SPN" SG_ 2365451262 Bus1PhaseAACFrequency 2505;
BA_ "SPN" SG_ 2365451262 Bus1PhaseABLineLineACRMSVoltage 2509;
BA_ "SPN" SG_ 2365451518 Bs1AvrgLnNtrlACRMSVltg 2512;
BA_ "SPN" SG_ 2365451518 Bus1AverageACFrequency 2504;
BA_ "SPN" SG_ 2365451518 Bus1AverageLineLineACRMSVoltage 2508;
BA_ "SPN" SG_ 2365451774 UtilityTotalkWHoursExport 2502;
BA_ "SPN" SG_ 2365451774 UtilityTotalkWHoursImport 2503;
BA_ "SPN" SG_ 2365452030 UtilityPhaseCPowerFactor 2501;
BA_ "SPN" SG_ 2365452030 UtilityPhaseCPowerFactorLagging 2525;
BA_ "SPN" SG_ 2365452030 UtilityPhaseCReactivePower 2493;
BA_ "SPN" SG_ 2365452286 UtilityPhaseCApparentPower 2497;
BA_ "SPN" SG_ 2365452286 UtilityPhaseCRealPower 2489;
BA_ "SPN" SG_ 2365452542 UtilityPhaseCACFrequency 2473;
BA_ "SPN" SG_ 2365452542 UtilityPhaseCACRMSCurrent 2485;
BA_ "SPN" SG_ 2365452542 UtltPhsCALnLnACRMSVltg 2477;
BA_ "SPN" SG_ 2365452542 UtltPhsCLnNtrlACRMSVltg 2481;
BA_ "SPN" SG_ 2365452798 UtilityPhaseBPowerFactor 2500;
BA_ "SPN" SG_ 2365452798 UtilityPhaseBPowerFactorLagging 2524;
BA_ "SPN" SG_ 2365452798 UtilityPhaseBReactivePower 2492;
BA_ "SPN" SG_ 2365453054 UtilityPhaseBApparentPower 2496;
BA_ "SPN" SG_ 2365453054 UtilityPhaseBRealPower 2488;
BA_ "SPN" SG_ 2365453310 UtilityPhaseBACFrequency 2472;
BA_ "SPN" SG_ 2365453310 UtilityPhaseBACRMSCurrent 2484;
BA_ "SPN" SG_ 2365453310 UtltPhsBCLnLnACRMSVltg 2476;
BA_ "SPN" SG_ 2365453310 UtltPhsBLnNtrlACRMSVltg 2480;
BA_ "SPN" SG_ 2365453566 UtilityPhaseAPowerFactor 2499;
BA_ "SPN" SG_ 2365453566 UtilityPhaseAPowerFactorLagging 2523;
BA_ "SPN" SG_ 2365453566 UtilityPhaseAReactivePower 2491;
BA_ "SPN" SG_ 2365453822 UtilityPhaseAApparentPower 2495;
BA_ "SPN" SG_ 2365453822 UtilityPhaseARealPower 2487;
BA_ "SPN" SG_ 2365454078 UtilityPhaseAACFrequency 2471;
BA_ "SPN" SG_ 2365454078 UtilityPhaseAACRMSCurrent 2483;
BA_ "SPN" SG_ 2365454078 UtltPhsABLnLnACRMSVltg 2475;
BA_ "SPN" SG_ 2365454078 UtltPhsALnNtrlACRMSVltg 2479;
BA_ "SPN" SG_ 2365454334 UtilityOverallPowerFactor 2498;
BA_ "SPN" SG_ 2365454334 UtilityTotalReactivePower 2490;
BA_ "SPN" SG_ 2365454334 UtltOvrllPwrFtrLggng 2522;
BA_ "SPN" SG_ 2365454590 UtilityTotalApparentPower 2494;
BA_ "SPN" SG_ 2365454590 UtilityTotalRealPower 2486;
BA_ "SPN" SG_ 2365454846 UtilityAverageACFrequency 2470;
BA_ "SPN" SG_ 2365454846 UtilityAverageACRMSCurrent 2482;
BA_ "SPN" SG_ 2365454846 UtltAvrgLnLnACRMSVltg 2474;
BA_ "SPN" SG_ 2365454846 UtltAvrgLnNtrlACRMSVltg 2478;
BA_ "SPN" SG_ 2365455102 GeneratorTotalkWHoursExport 2468;
BA_ "SPN" SG_ 2365455102 GeneratorTotalkWHoursImport 2469;
BA_ "SPN" SG_ 2365455358 GeneratorPhaseCPowerFactor 2467;
BA_ "SPN" SG_ 2365455358 GeneratorPhaseCReactivePower 2459;
BA_ "SPN" SG_ 2365455358 GnrtrPhsCPwrFtrLggng 2521;
BA_ "SPN" SG_ 2365455614 GeneratorPhaseCApparentPower 2463;
BA_ "SPN" SG_ 2365455614 GeneratorPhaseCRealPower 2455;
BA_ "SPN" SG_ 2365455870 GeneratorPhaseCACFrequency 2439;
BA_ "SPN" SG_ 2365455870 GeneratorPhaseCACRMSCurrent 2451;
BA_ "SPN" SG_ 2365455870 GnrtrPhsCALnLnACRMSVltg 2443;
BA_ "SPN" SG_ 2365455870 GnrtrPhsCLnNtrlACRMSVltg 2447;
BA_ "SPN" SG_ 2365456126 GeneratorPhaseBPowerFactor 2466;
BA_ "SPN" SG_ 2365456126 GeneratorPhaseBReactivePower 2458;
BA_ "SPN" SG_ 2365456126 GnrtrPhsBPwrFtrLggng 2520;
BA_ "SPN" SG_ 2365456382 GeneratorPhaseBApparentPower 2462;
BA_ "SPN" SG_ 2365456382 GeneratorPhaseBRealPower 2454;
BA_ "SPN" SG_ 2365456894 GeneratorPhaseAPowerFactor 2465;
BA_ "SPN" SG_ 2365456894 GeneratorPhaseAReactivePower 2457;
BA_ "SPN" SG_ 2365456894 GnrtrPhsAPwrFtrLggng 2519;
BA_ "SPN" SG_ 2365457150 GeneratorPhaseAApparentPower 2461;
BA_ "SPN" SG_ 2365457150 GeneratorPhaseARealPower 2453;
BA_ "SPN" SG_ 2365457406 GeneratorPhaseAACFrequency 2437;
BA_ "SPN" SG_ 2365457406 GeneratorPhaseAACRMSCurrent 2449;
BA_ "SPN" SG_ 2365457406 GnrtrPhsABLnLnACRMSVltg 2441;
BA_ "SPN" SG_ 2365457406 GnrtrPhsALnNtrlACRMSVltg 2445;
BA_ "SPN" SG_ 2365457662 GeneratorOverallPowerFactor 2464;
BA_ "SPN" SG_ 2365457662 GeneratorTotalReactivePower 2456;
BA_ "SPN" SG_ 2365457662 GnrtrOvrllPwrFtrLggng 2518;
BA_ "SPN" SG_ 2365457918 GeneratorTotalApparentPower 2460;
BA_ "SPN" SG_ 2365457918 GeneratorTotalRealPower 2452;
BA_ "SPN" SG_ 2365458174 GeneratorAverageACFrequency 2436;
BA_ "SPN" SG_ 2365458174 GeneratorAverageACRMSCurrent 2448;
BA_ "SPN" SG_ 2365458174 GnrtrAvrgLnLnACRMSVltg 2440;
BA_ "SPN" SG_ 2365458174 GnrtrAvrgLnNtrlACRMSVltg 2444;
BA_ "SPN" SG_ 2365473278 AlternateBeamHeadLightCommand 2351;
BA_ "SPN" SG_ 2365473278 BackUpLightandAlarmHornCommand 2391;
BA_ "SPN" SG_ 2365473278 CenterStopLightCommand 2375;
BA_ "SPN" SG_ 2365473278 HighBeamHeadLightCommand 2347;
BA_ "SPN" SG_ 2365473278 ImplementClearanceLightCommand 2383;
BA_ "SPN" SG_ 2365473278 ImplementMarkerLightCommand 2379;
BA_ "SPN" SG_ 2365473278 ImplementOEMOption1LightCommand 2395;
BA_ "SPN" SG_ 2365473278 ImplementOEMOption2LightCommand 2397;
BA_ "SPN" SG_ 2365473278 ImplementRearWorkLightCommand 2405;
BA_ "SPN" SG_ 2365473278 ImplmntLftFngWrkLghtCmmnd 2399;
BA_ "SPN" SG_ 2365473278 ImplmntLftFrwrdWrkLghtCmmnd 2597;
BA_ "SPN" SG_ 2365473278 ImplmntRghtFngWrkLghtCmmnd 2406;
BA_ "SPN" SG_ 2365473278 ImplmntRghtFrwrdWrkLghtCmmnd 2401;
BA_ "SPN" SG_ 2365473278 LeftStopLightCommand 2371;
BA_ "SPN" SG_ 2365473278 LeftTurnSignalLightsCommand 2367;
BA_ "SPN" SG_ 2365473278 LightingDataRequestCommand 2393;
BA_ "SPN" SG_ 2365473278 LowBeamHeadLightCommand 2349;
BA_ "SPN" SG_ 2365473278 RearFogLightCommand 2389;
BA_ "SPN" SG_ 2365473278 RightStopLightCommand 2373;
BA_ "SPN" SG_ 2365473278 RightTurnSignalLightsCommand 2369;
BA_ "SPN" SG_ 2365473278 RotatingBeaconLightCommand 2385;
BA_ "SPN" SG_ 2365473278 RunningLightCommand 2403;
BA_ "SPN" SG_ 2365473278 TractorClearanceLightCommand 2381;
BA_ "SPN" SG_ 2365473278 TractorFrontFogLightsCommand 2387;
BA_ "SPN" SG_ 2365473278 TractorMarkerLightCommand 2377;
BA_ "SPN" SG_ 2365473278 TrtrFrntHghMntdWrkLghtsCmmnd 2355;
BA_ "SPN" SG_ 2365473278 TrtrFrntLwMntdWrkLghtsCmmnd 2353;
BA_ "SPN" SG_ 2365473278 TrtrRrHghMntdWrkLghtsCmmnd 2361;
BA_ "SPN" SG_ 2365473278 TrtrRrLwMntdWrkLghtsCmmnd 2359;
BA_ "SPN" SG_ 2365473278 TrtrSdHghMntdWrkLghtsCmmnd 2365;
BA_ "SPN" SG_ 2365473278 TrtrSdLwMntdWrkLghtsCmmnd 2363;
BA_ "SPN" SG_ 2365473278 TrtrUndrsdMntdWrkLghtsCmmnd 2357;
BA_ "SPN" SG_ 2365478910 DamperStiffnessFrontAxle 1729;
BA_ "SPN" SG_ 2365478910 DamperStiffnessLiftTagAxle 1731;
BA_ "SPN" SG_ 2365478910 DamperStiffnessRearAxle 1730;
BA_ "SPN" SG_ 2365478910 EltrnShkAsrrCntrlMdFrntAxl 1833;
BA_ "SPN" SG_ 2365478910 EltrnShkAsrrCntrlMdLftTgAxl 1831;
BA_ "SPN" SG_ 2365478910 EltrnShkAsrrCntrlMdRrAxl 1832;
BA_ "SPN" SG_ 2365479678 AboveNominalLevelFrontAxle 1737;
BA_ "SPN" SG_ 2365479678 AboveNominalLevelRearAxle 1736;
BA_ "SPN" SG_ 2365479678 AllwLvlCntrlDrngBrkngStts 5294;
BA_ "SPN" SG_ 2365479678 BelowNominalLevelFrontAxle 1738;
BA_ "SPN" SG_ 2365479678 BelowNominalLevelRearAxle 1754;
BA_ "SPN" SG_ 2365479678 DoorRelease 1744;
BA_ "SPN" SG_ 2365479678 FrontAxleinBumperRange 1824;
BA_ "SPN" SG_ 2365479678 KneelingInformation 1742;
BA_ "SPN" SG_ 2365479678 LevelControlMode 1741;
BA_ "SPN" SG_ 2365479678 LiftAxle1Position 1743;
BA_ "SPN" SG_ 2365479678 LiftAxle2Position 1822;
BA_ "SPN" SG_ 2365479678 LiftingControlModeFrontAxle 1739;
BA_ "SPN" SG_ 2365479678 LiftingControlModeRearAxle 1756;
BA_ "SPN" SG_ 2365479678 LoweringControlModeFrontAxle 1740;
BA_ "SPN" SG_ 2365479678 LoweringControlModeRearAxle 1755;
BA_ "SPN" SG_ 2365479678 Memorylevel 5432;
BA_ "SPN" SG_ 2365479678 NominalLevelFrontAxle 1734;
BA_ "SPN" SG_ 2365479678 NominalLevelRearAxle 1733;
BA_ "SPN" SG_ 2365479678 RearAxleinBumperRange 1823;
BA_ "SPN" SG_ 2365479678 SecurityDevice 1746;
BA_ "SPN" SG_ 2365479678 SpdDpndntLvlCntrlStts 5296;
BA_ "SPN" SG_ 2365479678 SspnsnCntrlRfslInfrmtn 1827;
BA_ "SPN" SG_ 2365479678 SuspensionRemoteControl1 1826;
BA_ "SPN" SG_ 2365479678 SuspensionRemotecontrol2 1825;
BA_ "SPN" SG_ 2365479678 VehicleMotionInhibit 1745;
VAL_ 2365402878 Joystick5Button10PressedStatus 3 "NotAvailable" 2 "ErrorIndicator" 1 "ButtonPressed" 0 "ButtonNotPressed" ;
VAL_ 2365402878 Joystick5Button11PressedStatus 3 "NotAvailable" 2 "ErrorIndicator" 1 "ButtonPressed" 0 "ButtonNotPressed" ;
VAL_ 2365402878 Joystick5Button12PressedStatus 3 "NotAvailable" 2 "ErrorIndicator" 1 "ButtonPressed" 0 "ButtonNotPressed" ;
VAL_ 2365402878 Joystick5Button1PressedStatus 3 "NotAvailable" 2 "ErrorIndicator" 1 "ButtonPressed" 0 "ButtonNotPressed" ;
VAL_ 2365402878 Joystick5Button2PressedStatus 3 "NotAvailable" 2 "ErrorIndicator" 1 "ButtonPressed" 0 "ButtonNotPressed" ;
VAL_ 2365402878 Joystick5Button3PressedStatus 3 "NotAvailable" 2 "ErrorIndicator" 1 "ButtonPressed" 0 "ButtonNotPressed" ;
VAL_ 2365402878 Joystick5Button4PressedStatus 3 "NotAvailable" 2 "ErrorIndicator" 1 "ButtonPressed" 0 "ButtonNotPressed" ;
VAL_ 2365402878 Joystick5Button5PressedStatus 3 "NotAvailable" 2 "ErrorIndicator" 1 "ButtonPressed" 0 "ButtonNotPressed" ;
VAL_ 2365402878 Joystick5Button6PressedStatus 3 "NotAvailable" 2 "ErrorIndicator" 1 "ButtonPressed" 0 "ButtonNotPressed" ;
VAL_ 2365402878 Joystick5Button7PressedStatus 3 "NotAvailable" 2 "ErrorIndicator" 1 "ButtonPressed" 0 "ButtonNotPressed" ;
VAL_ 2365402878 Joystick5Button8PressedStatus 3 "NotAvailable" 2 "ErrorIndicator" 1 "ButtonPressed" 0 "ButtonNotPressed" ;
VAL_ 2365402878 Joystick5Button9PressedStatus 3 "NotAvailable" 2 "ErrorIndicator" 1 "ButtonPressed" 0 "ButtonNotPressed" ;
VAL_ 2365403390 Joystick4Button10PressedStatus 3 "NotAvailable" 2 "ErrorIndicator" 1 "ButtonPressed" 0 "ButtonNotPressed" ;
VAL_ 2365403390 Joystick4Button11PressedStatus 3 "NotAvailable" 2 "ErrorIndicator" 1 "ButtonPressed" 0 "ButtonNotPressed" ;
VAL_ 2365403390 Joystick4Button12PressedStatus 3 "NotAvailable" 2 "ErrorIndicator" 1 "ButtonPressed" 0 "ButtonNotPressed" ;
VAL_ 2365403390 Joystick4Button1PressedStatus 3 "NotAvailable" 2 "ErrorIndicator" 1 "ButtonPressed" 0 "ButtonNotPressed" ;
VAL_ 2365403390 Joystick4Button2PressedStatus 3 "NotAvailable" 2 "ErrorIndicator" 1 "ButtonPressed" 0 "ButtonNotPressed" ;
VAL_ 2365403390 Joystick4Button3PressedStatus 3 "NotAvailable" 2 "ErrorIndicator" 1 "ButtonPressed" 0 "ButtonNotPressed" ;
VAL_ 2365403390 Joystick4Button4PressedStatus 3 "NotAvailable" 2 "ErrorIndicator" 1 "ButtonPressed" 0 "ButtonNotPressed" ;
VAL_ 2365403390 Joystick4Button5PressedStatus 3 "NotAvailable" 2 "ErrorIndicator" 1 "ButtonPressed" 0 "ButtonNotPressed" ;
VAL_ 2365403390 Joystick4Button6PressedStatus 3 "NotAvailable" 2 "ErrorIndicator" 1 "ButtonPressed" 0 "ButtonNotPressed" ;
VAL_ 2365403390 Joystick4Button7PressedStatus 3 "NotAvailable" 2 "ErrorIndicator" 1 "ButtonPressed" 0 "ButtonNotPressed" ;
VAL_ 2365403390 Joystick4Button8PressedStatus 3 "NotAvailable" 2 "ErrorIndicator" 1 "ButtonPressed" 0 "ButtonNotPressed" ;
VAL_ 2365403390 Joystick4Button9PressedStatus 3 "NotAvailable" 2 "ErrorIndicator" 1 "ButtonPressed" 0 "ButtonNotPressed" ;
VAL_ 2365443326 HazardLightSwitch 3 "NotAvailable" 2 "Error" 1 "HazardLampsToBeFlashing" 0 "HazardLampsToBeOff" ;
VAL_ 2365443326 HighLowBeamSwitch 3 "NotAvailable" 2 "Error" 1 "HighBeamSelected" 0 "LowBeamSelected" ;
VAL_ 2365443326 MainLightSwitch 9 "1101Reserved" 8 "DlydOffPsByWhchThOprtrSlctsThtA" 4 "0111Reserved" 2 "HdlghtOnPsByWhchThOprtrSlctsTht" 15 "NotAvailable" 14 "Error" 3 "HdlghtAndPrkOnPsByWhchThOprtrSl" 1 "PrkOnPsByWhchThOprtrSlctsThtThP" 0 "OffPsByWhchThOprtrSlctsThtNnOfT" ;
VAL_ 2365443326 TurnSignalSwitch 2 "RightTurnToBeFlashing" 15 "NotAvailable" 14 "Error" 3 "1101Reserved" 1 "LeftTurnToBeFlashing" 0 "NoTurnBeingSignaled" ;
VAL_ 2365443326 WorkLightSwitch 5 "1101Reserved" 4 "WrkLghtCmbntn4OnPsByWhchThOprtr" 2 "WrkLghtCmbntn2OnPsByWhchThOprtr" 15 "NotAvailable" 14 "Error" 3 "WrkLghtCmbntn3OnPsByWhchThOprtr" 1 "WrkLghtCmbntn1OnPsByWhchThOprtr" 0 "OffPsByWhchThOprtrSlctsThtNnOfT" ;
VAL_ 2365445886 Joystick1Button10PressedStatus 3 "NotAvailable" 2 "ErrorIndicator" 1 "ButtonPressed" 0 "ButtonNotPressed" ;
VAL_ 2365445886 Joystick1Button11PressedStatus 3 "NotAvailable" 2 "ErrorIndicator" 1 "ButtonPressed" 0 "ButtonNotPressed" ;
VAL_ 2365445886 Joystick1Button12PressedStatus 3 "NotAvailable" 2 "ErrorIndicator" 1 "ButtonPressed" 0 "ButtonNotPressed" ;
VAL_ 2365445886 Joystick1Button1PressedStatus 3 "NotAvailable" 2 "ErrorIndicator" 1 "ButtonPressed" 0 "ButtonNotPressed" ;
VAL_ 2365445886 Joystick1Button2PressedStatus 3 "NotAvailable" 2 "ErrorIndicator" 1 "ButtonPressed" 0 "ButtonNotPressed" ;
VAL_ 2365445886 Joystick1Button3PressedStatus 3 "NotAvailable" 2 "ErrorIndicator" 1 "ButtonPressed" 0 "ButtonNotPressed" ;
VAL_ 2365445886 Joystick1Button4PressedStatus 3 "NotAvailable" 2 "ErrorIndicator" 1 "ButtonPressed" 0 "ButtonNotPressed" ;
VAL_ 2365445886 Joystick1Button5PressedStatus 3 "NotAvailable" 2 "ErrorIndicator" 1 "ButtonPressed" 0 "ButtonNotPressed" ;
VAL_ 2365445886 Joystick1Button6PressedStatus 3 "NotAvailable" 2 "ErrorIndicator" 1 "ButtonPressed" 0 "ButtonNotPressed" ;
VAL_ 2365445886 Joystick1Button7PressedStatus 3 "NotAvailable" 2 "ErrorIndicator" 1 "ButtonPressed" 0 "ButtonNotPressed" ;
VAL_ 2365445886 Joystick1Button8PressedStatus 3 "NotAvailable" 2 "ErrorIndicator" 1 "ButtonPressed" 0 "ButtonNotPressed" ;
VAL_ 2365445886 Joystick1Button9PressedStatus 3 "NotAvailable" 2 "ErrorIndicator" 1 "ButtonPressed" 0 "ButtonNotPressed" ;
VAL_ 2365446398 Joystick2Button10PressedStatus 3 "NotAvailable" 2 "ErrorIndicator" 1 "ButtonPressed" 0 "ButtonNotPressed" ;
VAL_ 2365446398 Joystick2Button11PressedStatus 3 "NotAvailable" 2 "ErrorIndicator" 1 "ButtonPressed" 0 "ButtonNotPressed" ;
VAL_ 2365446398 Joystick2Button12PressedStatus 3 "NotAvailable" 2 "ErrorIndicator" 1 "ButtonPressed" 0 "ButtonNotPressed" ;
VAL_ 2365446398 Joystick2Button1PressedStatus 3 "NotAvailable" 2 "ErrorIndicator" 1 "ButtonPressed" 0 "ButtonNotPressed" ;
VAL_ 2365446398 Joystick2Button2PressedStatus 3 "NotAvailable" 2 "ErrorIndicator" 1 "ButtonPressed" 0 "ButtonNotPressed" ;
VAL_ 2365446398 Joystick2Button3PressedStatus 3 "NotAvailable" 2 "ErrorIndicator" 1 "ButtonPressed" 0 "ButtonNotPressed" ;
VAL_ 2365446398 Joystick2Button4PressedStatus 3 "NotAvailable" 2 "ErrorIndicator" 1 "ButtonPressed" 0 "ButtonNotPressed" ;
VAL_ 2365446398 Joystick2Button5PressedStatus 3 "NotAvailable" 2 "ErrorIndicator" 1 "ButtonPressed" 0 "ButtonNotPressed" ;
VAL_ 2365446398 Joystick2Button6PressedStatus 3 "NotAvailable" 2 "ErrorIndicator" 1 "ButtonPressed" 0 "ButtonNotPressed" ;
VAL_ 2365446398 Joystick2Button7PressedStatus 3 "NotAvailable" 2 "ErrorIndicator" 1 "ButtonPressed" 0 "ButtonNotPressed" ;
VAL_ 2365446398 Joystick2Button8PressedStatus 3 "NotAvailable" 2 "ErrorIndicator" 1 "ButtonPressed" 0 "ButtonNotPressed" ;
VAL_ 2365446398 Joystick2Button9PressedStatus 3 "NotAvailable" 2 "ErrorIndicator" 1 "ButtonPressed" 0 "ButtonNotPressed" ;
VAL_ 2365446910 Joystick3Button10PressedStatus 3 "NotAvailable" 2 "ErrorIndicator" 1 "ButtonPressed" 0 "ButtonNotPressed" ;
VAL_ 2365446910 Joystick3Button11PressedStatus 3 "NotAvailable" 2 "ErrorIndicator" 1 "ButtonPressed" 0 "ButtonNotPressed" ;
VAL_ 2365446910 Joystick3Button12PressedStatus 3 "NotAvailable" 2 "ErrorIndicator" 1 "ButtonPressed" 0 "ButtonNotPressed" ;
VAL_ 2365446910 Joystick3Button1PressedStatus 3 "NotAvailable" 2 "ErrorIndicator" 1 "ButtonPressed" 0 "ButtonNotPressed" ;
VAL_ 2365446910 Joystick3Button2PressedStatus 3 "NotAvailable" 2 "ErrorIndicator" 1 "ButtonPressed" 0 "ButtonNotPressed" ;
VAL_ 2365446910 Joystick3Button3PressedStatus 3 "NotAvailable" 2 "ErrorIndicator" 1 "ButtonPressed" 0 "ButtonNotPressed" ;
VAL_ 2365446910 Joystick3Button4PressedStatus 3 "NotAvailable" 2 "ErrorIndicator" 1 "ButtonPressed" 0 "ButtonNotPressed" ;
VAL_ 2365446910 Joystick3Button5PressedStatus 3 "NotAvailable" 2 "ErrorIndicator" 1 "ButtonPressed" 0 "ButtonNotPressed" ;
VAL_ 2365446910 Joystick3Button6PressedStatus 3 "NotAvailable" 2 "ErrorIndicator" 1 "ButtonPressed" 0 "ButtonNotPressed" ;
VAL_ 2365446910 Joystick3Button7PressedStatus 3 "NotAvailable" 2 "ErrorIndicator" 1 "ButtonPressed" 0 "ButtonNotPressed" ;
VAL_ 2365446910 Joystick3Button8PressedStatus 3 "NotAvailable" 2 "ErrorIndicator" 1 "ButtonPressed" 0 "ButtonNotPressed" ;
VAL_ 2365446910 Joystick3Button9PressedStatus 3 "NotAvailable" 2 "ErrorIndicator" 1 "ButtonPressed" 0 "ButtonNotPressed" ;
VAL_ 2365479678 AboveNominalLevelFrontAxle 3 "NotAvailable" 2 "Error" 1 "Above" 0 "NotAbove" ;
VAL_ 2365479678 AboveNominalLevelRearAxle 3 "NotAvailable" 2 "Error" 1 "Above" 0 "NotAbove" ;
VAL_ 2365479678 BelowNominalLevelFrontAxle 3 "NotAvailable" 2 "Error" 1 "Below" 0 "NotBelow" ;
VAL_ 2365479678 BelowNominalLevelRearAxle 3 "NotAvailable" 2 "Error" 1 "Below" 0 "NotBelow" ;
VAL_ 2365479678 DoorRelease 3 "NotAvailable" 2 "Error" 1 "DoorsMayBeOpened" 0 "DoorsMayNotBeOpened" ;
VAL_ 2365479678 FrontAxleinBumperRange 3 "NotAvailable" 2 "Error" 1 "ActualLevelWithinBumperRange" 0 "ActualLevelOutOfBumperRange" ;
VAL_ 2365479678 KneelingInformation 15 "NotAvailable" 14 "Error" 5 "1101NotDefined" 4 "KneelingAborted" 3 "LiftingActive" 2 "KneelingLevelReached" 0 "NotActive" ;
VAL_ 2365479678 Memorylevel 15 "NotAvailable" 14 "ErrorIndicator" 13 "MemoryLevel5Stored" 12 "MemoryLevel4Stored" 11 "MemoryLevel3Stored" 10 "MemoryLevel2Stored" 9 "MemoryLevel1Stored" 8 "Reserved" 5 "MemoryLevel5Selected" 4 "MemoryLevel4Selected" 3 "MemoryLevel3Selected" 2 "MemoryLevel2Selected" 1 "MemoryLevel1Selected" 0 "NoMemoryLevel" ;
VAL_ 2365479678 NominalLevelFrontAxle 9 "Raising" 11 "1101NotDefined" 10 "Lowering" 15 "NotAvailable" 14 "Error" 8 "NotDefined" 7 "LowerLevel" 6 "UpperLevel" 5 "CustomerLevel" 4 "PresetLevel" 3 "NormalLevel3" 2 "NormalLevel2" 1 "NormalLevel1" 0 "LevelNotSpecified" ;
VAL_ 2365479678 NominalLevelRearAxle 9 "Raising" 11 "1101NotDefined" 10 "Lowering" 15 "NotAvailable" 14 "Error" 8 "NotDefined" 7 "LowerLevel" 6 "UpperLevel" 5 "CustomerLevel" 4 "PresetLevel" 3 "NormalLevel3" 2 "NormalLevel2" 1 "NormalLevel1" 0 "LevelNotSpecified" ;
VAL_ 2365479678 RearAxleinBumperRange 3 "NotAvailable" 2 "Error" 1 "ActualLevelWithinBumperRange" 0 "ActualLevelOutOfBumperRange" ;
VAL_ 2365479678 SecurityDevice 3 "NotAvailable" 2 "Error" 1 "Active" 0 "NotActive" ;
VAL_ 2365479678 VehicleMotionInhibit 3 "NotAvailable" 2 "Error" 1 "VehicleMotionIsInhibited" 0 "VehicleMayBeMoved" ;
VAL_ 2365402622 Jstk5GrpXAxsNtrlPstnStts 3 "NotAvailable" 2 "ErrorIndicator" 1 "InNeutralPos" 0 "NotInNeutralPos" ;
VAL_ 2365402622 Jstk5GrpXAxsLvrLftNgtvPstnStts 3 "NotAvailable" 2 "ErrorIndicator" 1 "OnNegativeSideOfNeutral" 0 "NotOnNegativeSideOfNeutral" ;
VAL_ 2365402622 Jstk5GrpXAxsLvrRghtPstvPstnStts 3 "NotAvailable" 2 "ErrorIndicator" 1 "OnPositiveSideOfNeutral" 0 "NotOnPositiveSideOfNeutral" ;
VAL_ 2365402622 Jstk5GrpYAxsNtrlPstnStts 3 "NotAvailable" 2 "ErrorIndicator" 1 "InNeutralPos" 0 "NotInNeutralPos" ;
VAL_ 2365402622 Jstk5GrpYAxsLvrBkNgtvPstnStts 3 "NotAvailable" 2 "ErrorIndicator" 1 "OnNegativeSideOfNeutral" 0 "NotOnNegativeSideOfNeutral" ;
VAL_ 2365402622 Jst5GpYAxsLvFwdPstvPstStts 3 "NotAvailable" 2 "ErrorIndicator" 1 "OnPositiveSideOfNeutral" 0 "NotOnPositiveSideOfNeutral" ;
VAL_ 2365402622 Jstk5ThtAxsNtrlPstnStts 3 "NotAvailable" 2 "ErrorIndicator" 1 "InNeutralPos" 0 "NotInNeutralPos" ;
VAL_ 2365402622 Jst5TtAxsCtCwsNtvPstStts 3 "NotAvailable" 2 "ErrorIndicator" 1 "OnNegativeSideOfNeutral" 0 "NotOnNegativeSideOfNeutral" ;
VAL_ 2365402622 Jstk5ThtAxsClkwsPstvPstnStts 3 "NotAvailable" 2 "ErrorIndicator" 1 "OnPositiveSideOfNeutral" 0 "NotOnPositiveSideOfNeutral" ;
VAL_ 2365402622 Jstk5ThtAxsDtntPstnStts 3 "NotAvailable" 2 "ErrorIndicator" 1 "InDetentPos" 0 "NotInDetentPos" ;
VAL_ 2365402622 Jstk5GrpYAxsDtntPstnStts 3 "NotAvailable" 2 "ErrorIndicator" 1 "InDetentPos" 0 "NotInDetentPos" ;
VAL_ 2365402622 Jstk5GrpXAxsDtntPstnStts 3 "NotAvailable" 2 "ErrorIndicator" 1 "InDetentPos" 0 "NotInDetentPos" ;
VAL_ 2365402878 Jstk5XAxsNtrlPstnStts 3 "NotAvailable" 2 "ErrorIndicator" 1 "InNeutralPos" 0 "NotInNeutralPos" ;
VAL_ 2365402878 Jstk5XAxsLvrLftNgtvPstnStts 3 "NotAvailable" 2 "ErrorIndicator" 1 "OnNegativeSideOfNeutral" 0 "NotOnNegativeSideOfNeutral" ;
VAL_ 2365402878 Jstk5XAxsLvrRghtPstvPstnStts 3 "NotAvailable" 2 "ErrorIndicator" 1 "OnPositiveSideOfNeutral" 0 "NotOnPositiveSideOfNeutral" ;
VAL_ 2365402878 Jstk5YAxsNtrlPstnStts 3 "NotAvailable" 2 "ErrorIndicator" 1 "InNeutralPos" 0 "NotInNeutralPos" ;
VAL_ 2365402878 Jstk5YAxsLvrBkNgtvPstnStts 3 "NotAvailable" 2 "ErrorIndicator" 1 "OnNegativeSideOfNeutral" 0 "NotOnNegativeSideOfNeutral" ;
VAL_ 2365402878 Jstk5YAxsLvrFrwrdPstvPstnStts 3 "NotAvailable" 2 "ErrorIndicator" 1 "OnPositiveSideOfNeutral" 0 "NotOnPositiveSideOfNeutral" ;
VAL_ 2365402878 Jstk5YAxsDtntPstnStts 3 "NotAvailable" 2 "ErrorIndicator" 1 "InDetentPos" 0 "NotInDetentPos" ;
VAL_ 2365402878 Jstk5XAxsDtntPstnStts 3 "NotAvailable" 2 "ErrorIndicator" 1 "InDetentPos" 0 "NotInDetentPos" ;
VAL_ 2365403134 Jstk4GrpXAxsNtrlPstnStts 3 "NotAvailable" 2 "ErrorIndicator" 1 "InNeutralPos" 0 "NotInNeutralPos" ;
VAL_ 2365403134 Jstk4GrpXAxsLvrLftNgtvPstnStts 3 "NotAvailable" 2 "ErrorIndicator" 1 "OnNegativeSideOfNeutral" 0 "NotOnNegativeSideOfNeutral" ;
VAL_ 2365403134 Jstk4GrpXAxsLvrRghtPstvPstnStts 3 "NotAvailable" 2 "ErrorIndicator" 1 "OnPositiveSideOfNeutral" 0 "NotOnPositiveSideOfNeutral" ;
VAL_ 2365403134 Jstk4GrpYAxsNtrlPstnStts 3 "NotAvailable" 2 "ErrorIndicator" 1 "InNeutralPos" 0 "NotInNeutralPos" ;
VAL_ 2365403134 Jstk4GrpYAxsLvrBkNgtvPstnStts 3 "NotAvailable" 2 "ErrorIndicator" 1 "OnNegativeSideOfNeutral" 0 "NotOnNegativeSideOfNeutral" ;
VAL_ 2365403134 Jst4GpYAxsLvFwdPstvPstStts 3 "NotAvailable" 2 "ErrorIndicator" 1 "OnPositiveSideOfNeutral" 0 "NotOnPositiveSideOfNeutral" ;
VAL_ 2365403134 Jstk4ThtAxsNtrlPstnStts 3 "NotAvailable" 2 "ErrorIndicator" 1 "InNeutralPos" 0 "NotInNeutralPos" ;
VAL_ 2365403134 Jst4TtAxsCtCwsNtvPstStts 3 "NotAvailable" 2 "ErrorIndicator" 1 "OnNegativeSideOfNeutral" 0 "NotOnNegativeSideOfNeutral" ;
VAL_ 2365403134 Jstk4ThtAxsClkwsPstvPstnStts 3 "NotAvailable" 2 "ErrorIndicator" 1 "OnPositiveSideOfNeutral" 0 "NotOnPositiveSideOfNeutral" ;
VAL_ 2365403134 Jstk4ThtAxsDtntPstnStts 3 "NotAvailable" 2 "ErrorIndicator" 1 "InDetentPos" 0 "NotInDetentPos" ;
VAL_ 2365403134 Jstk4GrpYAxsDtntPstnStts 3 "NotAvailable" 2 "ErrorIndicator" 1 "InDetentPos" 0 "NotInDetentPos" ;
VAL_ 2365403134 Jstk4GrpXAxsDtntPstnStts 3 "NotAvailable" 2 "ErrorIndicator" 1 "InDetentPos" 0 "NotInDetentPos" ;
VAL_ 2365403390 Jstk4XAxsNtrlPstnStts 3 "NotAvailable" 2 "ErrorIndicator" 1 "InNeutralPos" 0 "NotInNeutralPos" ;
VAL_ 2365403390 Jstk4XAxsLvrLftNgtvPstnStts 3 "NotAvailable" 2 "ErrorIndicator" 1 "OnNegativeSideOfNeutral" 0 "NotOnNegativeSideOfNeutral" ;
VAL_ 2365403390 Jstk4XAxsLvrRghtPstvPstnStts 3 "NotAvailable" 2 "ErrorIndicator" 1 "OnPositiveSideOfNeutral" 0 "NotOnPositiveSideOfNeutral" ;
VAL_ 2365403390 Jstk4YAxsNtrlPstnStts 3 "NotAvailable" 2 "ErrorIndicator" 1 "InNeutralPos" 0 "NotInNeutralPos" ;
VAL_ 2365403390 Jstk4YAxsLvrBkNgtvPstnStts 3 "NotAvailable" 2 "ErrorIndicator" 1 "OnNegativeSideOfNeutral" 0 "NotOnNegativeSideOfNeutral" ;
VAL_ 2365403390 Jstk4YAxsLvrFrwrdPstvPstnStts 3 "NotAvailable" 2 "ErrorIndicator" 1 "OnPositiveSideOfNeutral" 0 "NotOnPositiveSideOfNeutral" ;
VAL_ 2365403390 Jstk4YAxsDtntPstnStts 3 "NotAvailable" 2 "ErrorIndicator" 1 "InDetentPos" 0 "NotInDetentPos" ;
VAL_ 2365403390 Jstk4XAxsDtntPstnStts 3 "NotAvailable" 2 "ErrorIndicator" 1 "InDetentPos" 0 "NotInDetentPos" ;
VAL_ 2365428478 FuelPumpPrimerControl 3 "Unavailable" 2 "Reserved" 1 "Activate" 0 "Deactivate" ;
VAL_ 2365428478 EngineFuelShutoffVentControl 3 "DontCare_TakeNoAction" 2 "Reserved" 1 "Open" 0 "Closed" ;
VAL_ 2365428478 EngineFuelShutoff1Control 3 "DontCare_TakeNoAction" 2 "Reserved" 1 "Closed" 0 "Open" ;
VAL_ 2365428478 EngineFuelShutoff2Control 3 "DontCare_TakeNoAction" 2 "Reserved" 1 "Closed" 0 "Open" ;
VAL_ 2365428478 EngnFlShtffVlvLkTstCntrl 3 "DontCare_TakeNoAction" 2 "Reserved" 1 "On" 0 "Off" ;
VAL_ 2365428478 EngineOilPrimingPumpControl 3 "Unavailable" 2 "Reserved" 1 "On" 0 "Off" ;
VAL_ 2365428478 EngineOilPreheaterControl 3 "DontCare_TakeNoAction" 2 "Reserved" 1 "On" 0 "Off" ;
VAL_ 2365428478 EngnEltrlSstmPwrCnsrvtnCntrl 3 "Unavailable" 2 "Reserved" 1 "On" 0 "Off" ;
VAL_ 2365428478 EnginePreHeaterControl 3 "Unavailable" 2 "Reserved" 1 "On" 0 "Off" ;
VAL_ 2365428478 EngineCoolantPumpControl 3 "DontCare_TakeNoAction" 2 "Reserved" 1 "On" 0 "Off" ;
VAL_ 2365428478 EngineControlledShutdownRequest 3 "DontCare_TakeNoAction" 2 "Reserved" 1 "On" 0 "Off" ;
VAL_ 2365428478 EngnEmrgnImmdtShtdwnIndtn 3 "DontCare_TakeNoAction" 2 "Reserved" 1 "On" 0 "Off" ;
VAL_ 2365445886 Jstk1XAxsNtrlPstnStts 3 "NotAvailable" 2 "ErrorIndicator" 1 "InNeutralPos" 0 "NotInNeutralPos" ;
VAL_ 2365445886 Jstk1XAxsLvrLftNgtvPstnStts 3 "NotAvailable" 2 "ErrorIndicator" 1 "OnNegativeSideOfNeutral" 0 "NotOnNegativeSideOfNeutral" ;
VAL_ 2365445886 Jstk1XAxsLvrRghtPstvPstnStts 3 "NotAvailable" 2 "ErrorIndicator" 1 "OnPositiveSideOfNeutral" 0 "NotOnPositiveSideOfNeutral" ;
VAL_ 2365445886 Jstk1YAxsNtrlPstnStts 3 "NotAvailable" 2 "ErrorIndicator" 1 "InNeutralPos" 0 "NotInNeutralPos" ;
VAL_ 2365445886 Jstk1YAxsLvrBkNgtvPstnStts 3 "NotAvailable" 2 "ErrorIndicator" 1 "OnNegativeSideOfNeutral" 0 "NotOnNegativeSideOfNeutral" ;
VAL_ 2365445886 Jstk1YAxsLvrFrwrdPstvPstnStts 3 "NotAvailable" 2 "ErrorIndicator" 1 "OnPositiveSideOfNeutral" 0 "NotOnPositiveSideOfNeutral" ;
VAL_ 2365445886 Jstk1YAxsDtntPstnStts 3 "NotAvailable" 2 "ErrorIndicator" 1 "InDetentPos" 0 "NotInDetentPos" ;
VAL_ 2365445886 Jstk1XAxsDtntPstnStts 3 "NotAvailable" 2 "ErrorIndicator" 1 "InDetentPos" 0 "NotInDetentPos" ;
VAL_ 2365446142 Jstk1GrpXAxsNtrlPstnStts 3 "NotAvailable" 2 "ErrorIndicator" 1 "InNeutralPos" 0 "NotInNeutralPos" ;
VAL_ 2365446142 Jstk1GrpXAxsLvrLftNgtvPstnStts 3 "NotAvailable" 2 "ErrorIndicator" 1 "OnNegativeSideOfNeutral" 0 "NotOnNegativeSideOfNeutral" ;
VAL_ 2365446142 Jstk1GrpXAxsLvrRghtPstvPstnStts 3 "NotAvailable" 2 "ErrorIndicator" 1 "OnPositiveSideOfNeutral" 0 "NotOnPositiveSideOfNeutral" ;
VAL_ 2365446142 Jstk1GrpYAxsNtrlPstnStts 3 "NotAvailable" 2 "ErrorIndicator" 1 "InNeutralPos" 0 "NotInNeutralPos" ;
VAL_ 2365446142 Jstk1GrpYAxsLvrBkNgtvPstnStts 3 "NotAvailable" 2 "ErrorIndicator" 1 "OnNegativeSideOfNeutral" 0 "NotOnNegativeSideOfNeutral" ;
VAL_ 2365446142 Jst1GpYAxsLvFwdPstvPstStts 3 "NotAvailable" 2 "ErrorIndicator" 1 "OnPositiveSideOfNeutral" 0 "NotOnPositiveSideOfNeutral" ;
VAL_ 2365446142 Jstk1ThtAxsNtrlPstnStts 3 "NotAvailable" 2 "ErrorIndicator" 1 "InNeutralPos" 0 "NotInNeutralPos" ;
VAL_ 2365446142 Jst1TtAxsCtCwsNtvPstStts 3 "NotAvailable" 2 "ErrorIndicator" 1 "OnNegativeSideOfNeutral" 0 "NotOnNegativeSideOfNeutral" ;
VAL_ 2365446142 Jstk1ThtAxsClkwsPstvPstnStts 3 "NotAvailable" 2 "ErrorIndicator" 1 "OnPositiveSideOfNeutral" 0 "NotOnPositiveSideOfNeutral" ;
VAL_ 2365446142 Jstk1ThtAxsDtntPstnStts 3 "NotAvailable" 2 "ErrorIndicator" 1 "InDetentPos" 0 "NotInDetentPos" ;
VAL_ 2365446142 Jstk1GrpYAxsDtntPstnStts 3 "NotAvailable" 2 "ErrorIndicator" 1 "InDetentPos" 0 "NotInDetentPos" ;
VAL_ 2365446142 Jstk1GrpXAxsDtntPstnStts 3 "NotAvailable" 2 "ErrorIndicator" 1 "InDetentPos" 0 "NotInDetentPos" ;
VAL_ 2365446398 Jstk2XAxsNtrlPstnStts 3 "NotAvailable" 2 "ErrorIndicator" 1 "InNeutralPos" 0 "NotInNeutralPos" ;
VAL_ 2365446398 Jstk2XAxsLvrLftNgtvPstnStts 3 "NotAvailable" 2 "ErrorIndicator" 1 "OnNegativeSideOfNeutral" 0 "NotOnNegativeSideOfNeutral" ;
VAL_ 2365446398 Jstk2XAxsLvrRghtPstvPstnStts 3 "NotAvailable" 2 "ErrorIndicator" 1 "OnPositiveSideOfNeutral" 0 "NotOnPositiveSideOfNeutral" ;
VAL_ 2365446398 Jstk2YAxsNtrlPstnStts 3 "NotAvailable" 2 "ErrorIndicator" 1 "InNeutralPos" 0 "NotInNeutralPos" ;
VAL_ 2365446398 Jstk2YAxsLvrBkNgtvPstnStts 3 "NotAvailable" 2 "ErrorIndicator" 1 "OnNegativeSideOfNeutral" 0 "NotOnNegativeSideOfNeutral" ;
VAL_ 2365446398 Jstk2YAxsLvrFrwrdPstvPstnStts 3 "NotAvailable" 2 "ErrorIndicator" 1 "OnPositiveSideOfNeutral" 0 "NotOnPositiveSideOfNeutral" ;
VAL_ 2365446398 Jstk2YAxsDtntPstnStts 3 "NotAvailable" 2 "ErrorIndicator" 1 "InDetentPos" 0 "NotInDetentPos" ;
VAL_ 2365446398 Jstk2XAxsDtntPstnStts 3 "NotAvailable" 2 "ErrorIndicator" 1 "InDetentPos" 0 "NotInDetentPos" ;
VAL_ 2365446654 Jstk2GrpXAxsNtrlPstnStts 3 "NotAvailable" 2 "ErrorIndicator" 1 "OnNegativeSideOfNeutral" 0 "NotOnNegativeSideOfNeutral" ;
VAL_ 2365446654 Jstk2GrpXAxsLvrLftNgtvPstnStts 3 "NotAvailable" 2 "ErrorIndicator" 1 "OnNegativeSideOfNeutral" 0 "NotOnNegativeSideOfNeutral" ;
VAL_ 2365446654 Jstk2GrpXAxsLvrRghtPstvPstnStts 3 "NotAvailable" 2 "ErrorIndicator" 1 "OnPositiveSideOfNeutral" 0 "NotOnPositiveSideOfNeutral" ;
VAL_ 2365446654 Jstk2GrpYAxsNtrlPstnStts 3 "NotAvailable" 2 "ErrorIndicator" 1 "InNeutralPos" 0 "NotInNeutralPos" ;
VAL_ 2365446654 Jstk2GrpYAxsLvrBkNgtvPstnStts 3 "NotAvailable" 2 "ErrorIndicator" 1 "OnNegativeSideOfNeutral" 0 "NotOnNegativeSideOfNeutral" ;
VAL_ 2365446654 Jst2GpYAxsLvFwdPstvPstStts 3 "NotAvailable" 2 "ErrorIndicator" 1 "OnPositiveSideOfNeutral" 0 "NotOnPositiveSideOfNeutral" ;
VAL_ 2365446654 Jstk2ThtAxsNtrlPstnStts 3 "NotAvailable" 2 "ErrorIndicator" 1 "InNeutralPos" 0 "NotInNeutralPos" ;
VAL_ 2365446654 Jst2TtAxsCtCwsNtvPstStts 3 "NotAvailable" 2 "ErrorIndicator" 1 "OnNegativeSideOfNeutral" 0 "NotOnNegativeSideOfNeutral" ;
VAL_ 2365446654 Jstk2ThtAxsClkwsPstvPstnStts 3 "NotAvailable" 2 "ErrorIndicator" 1 "OnPositiveSideOfNeutral" 0 "NotOnPositiveSideOfNeutral" ;
VAL_ 2365446654 Jstk2ThtAxsDtntPstnStts 3 "NotAvailable" 2 "ErrorIndicator" 1 "InDetentPos" 0 "NotInDetentPos" ;
VAL_ 2365446654 Jstk2GrpYAxsDtntPstnStts 3 "NotAvailable" 2 "ErrorIndicator" 1 "InDetentPos" 0 "NotInDetentPos" ;
VAL_ 2365446654 Jstk2GrpXAxsDtntPstnStts 3 "NotAvailable" 2 "ErrorIndicator" 1 "InDetentPos" 0 "NotInDetentPos" ;
VAL_ 2365446910 Jstk3XAxsNtrlPstnStts 3 "NotAvailable" 2 "ErrorIndicator" 1 "InNeutralPos" 0 "NotInNeutralPos" ;
VAL_ 2365446910 Jstk3XAxsLvrLftNgtvPstnStts 3 "NotAvailable" 2 "ErrorIndicator" 1 "OnNegativeSideOfNeutral" 0 "NotOnNegativeSideOfNeutral" ;
VAL_ 2365446910 Jstk3XAxsLvrRghtPstvPstnStts 3 "NotAvailable" 2 "ErrorIndicator" 1 "OnPositiveSideOfNeutral" 0 "NotOnPositiveSideOfNeutral" ;
VAL_ 2365446910 Jstk3YAxsNtrlPstnStts 3 "NotAvailable" 2 "ErrorIndicator" 1 "InNeutralPos" 0 "NotInNeutralPos" ;
VAL_ 2365446910 Jstk3YAxsLvrBkNgtvPstnStts 3 "NotAvailable" 2 "ErrorIndicator" 1 "OnNegativeSideOfNeutral" 0 "NotOnNegativeSideOfNeutral" ;
VAL_ 2365446910 Jstk3YAxsLvrFrwrdPstvPstnStts 3 "NotAvailable" 2 "ErrorIndicator" 1 "OnPositiveSideOfNeutral" 0 "NotOnPositiveSideOfNeutral" ;
VAL_ 2365446910 Jstk3YAxsDtntPstnStts 3 "NotAvailable" 2 "ErrorIndicator" 1 "InDetentPos" 0 "NotInDetentPos" ;
VAL_ 2365446910 Jstk3XAxsDtntPstnStts 3 "NotAvailable" 2 "ErrorIndicator" 1 "InDetentPos" 0 "NotInDetentPos" ;
VAL_ 2365447166 Jstk3GrpXAxsNtrlPstnStts 3 "NotAvailable" 2 "ErrorIndicator" 1 "OnNegativeSideOfNeutral" 0 "NotOnNegativeSideOfNeutral" ;
VAL_ 2365447166 Jstk3GrpXAxsLvrLftNgtvPstnStts 3 "NotAvailable" 2 "ErrorIndicator" 1 "OnNegativeSideOfNeutral" 0 "NotOnNegativeSideOfNeutral" ;
VAL_ 2365447166 Jstk3GrpXAxsLvrRghtPstvPstnStts 3 "NotAvailable" 2 "ErrorIndicator" 1 "OnPositiveSideOfNeutral" 0 "NotOnPositiveSideOfNeutral" ;
VAL_ 2365447166 Jstk3GrpYAxsNtrlPstnStts 3 "NotAvailable" 2 "ErrorIndicator" 1 "InNeutralPos" 0 "NotInNeutralPos" ;
VAL_ 2365447166 Jstk3GrpYAxsLvrBkNgtvPstnStts 3 "NotAvailable" 2 "ErrorIndicator" 1 "OnNegativeSideOfNeutral" 0 "NotOnNegativeSideOfNeutral" ;
VAL_ 2365447166 Jst3GpYAxsLvFwdPstvPstStts 3 "NotAvailable" 2 "ErrorIndicator" 1 "OnPositiveSideOfNeutral" 0 "NotOnPositiveSideOfNeutral" ;
VAL_ 2365447166 Jstk3ThtAxsNtrlPstnStts 3 "NotAvailable" 2 "ErrorIndicator" 1 "InNeutralPos" 0 "NotInNeutralPos" ;
VAL_ 2365447166 Jst3TtAxsCtCwsNtvPstStts 3 "NotAvailable" 2 "ErrorIndicator" 1 "OnNegativeSideOfNeutral" 0 "NotOnNegativeSideOfNeutral" ;
VAL_ 2365447166 Jstk3ThtAxsClkwsPstvPstnStts 3 "NotAvailable" 2 "ErrorIndicator" 1 "OnPositiveSideOfNeutral" 0 "NotOnPositiveSideOfNeutral" ;
VAL_ 2365447166 Jstk3ThtAxsDtntPstnStts 3 "NotAvailable" 2 "ErrorIndicator" 1 "InDetentPos" 0 "NotInDetentPos" ;
VAL_ 2365447166 Jstk3GrpYAxsDtntPstnStts 3 "NotAvailable" 2 "ErrorIndicator" 1 "InDetentPos" 0 "NotInDetentPos" ;
VAL_ 2365447166 Jstk3GrpXAxsDtntPstnStts 3 "NotAvailable" 2 "ErrorIndicator" 1 "InDetentPos" 0 "NotInDetentPos" ;
VAL_ 2365449982 HdrlBrkPrssrWrnngSttCrt1 3 "NotAvailable" 2 "ErrorIndicator" 1 "PressLevelBelowWarningLevel" 0 "PressLevelSufficient" ;
VAL_ 2365449982 HdrlBrkPrssrWrnngSttCrt2 3 "NotAvailable" 2 "ErrorIndicator" 1 "PressLevelBelowWarningLevel" 0 "PressLevelSufficient" ;
VAL_ 2365449982 HdrlBrkPrssrSpplSttCrt1 3 "NotAvailable" 2 "ErrorIndicator" 1 "SupplyIsReliable" 0 "SupplyIsNotReliable" ;
VAL_ 2365449982 HdrlBrkPrssrSpplSttCrt2 3 "NotAvailable" 2 "ErrorIndicator" 1 "SupplyIsReliable" 0 "SupplyIsNotReliable" ;
VAL_ 2365449982 HdrlBrkSstmAdlWrnngCmmnd 3 "DontCare" 2 "Reserved" 1 "AudibleWarningOn" 0 "AudibleWarningOff" ;
VAL_ 2365449982 HydraulicBrakeFluidLevelSwitch 3 "NotAvailable" 2 "ErrorIndicator" 1 "FluidLevelIsSufficient" 0 "FluidLevelIsNotSufficient" ;
VAL_ 2365450238 Bus1UtilityDeadBus 3 "NotAvailable" 2 "Error" 1 "BusIsDead" 0 "BusIsNotDead" ;
VAL_ 2365450238 Bus1UtilityPhaseMatch 3 "NotAvailable" 2 "Error" 1 "PhasesMatch" 0 "PhasesDoNotMatch" ;
VAL_ 2365450238 Bus1UtilityFrequencyMatch 3 "NotAvailable" 2 "Error" 1 "FrequenciesMatch" 0 "FrequenciesDoNotMatch" ;
VAL_ 2365450238 Bus1UtilityVoltageMatch 3 "NotAvailable" 2 "Error" 1 "VoltagesMatch" 0 "VolatagesDoNotMatch" ;
VAL_ 2365450238 Bus1UtilityInSync 3 "NotAvailable" 2 "Error" 1 "Sycnchronized" 0 "NotSynchronized" ;
VAL_ 2365450494 Bus1GeneratorDeadBus 3 "NotAvailable" 2 "Error" 1 "BusIsDead" 0 "BusIsNotDead" ;
VAL_ 2365450494 Bus1GeneratorPhaseMatch 3 "NotAvailable" 2 "Error" 1 "PhasesMatch" 0 "PhasesDoNotMatch" ;
VAL_ 2365450494 Bus1GeneratorFrequencyMatch 3 "NotAvailable" 2 "Error" 1 "FrequenciesMatch" 0 "FrequenciesDoNotMatch" ;
VAL_ 2365450494 Bus1GeneratorVoltageMatch 3 "NotAvailable" 2 "Error" 1 "VoltagesMatch" 0 "VolatagesDoNotMatch" ;
VAL_ 2365450494 Bus1GeneratorInSync 3 "NotAvailable" 2 "Error" 1 "Sycnchronized" 0 "NotSynchronized" ;
VAL_ 2365455358 GnrtrPhsCPwrFtrLggng 3 "NotAvailable_NotInstalled" 2 "Error" 1 "Lagging" 0 "Leading" ;
VAL_ 2365456126 GnrtrPhsBPwrFtrLggng 3 "NotAvailable_NotInstalled" 2 "Error" 1 "Lagging" 0 "Leading" ;
VAL_ 2365456894 GnrtrPhsAPwrFtrLggng 3 "NotAvailable_NotInstalled" 2 "Error" 1 "Lagging" 0 "Leading" ;
VAL_ 2365457662 GnrtrOvrllPwrFtrLggng 3 "NotAvailable_NotInstalled" 2 "Error" 1 "Lagging" 0 "Leading" ;
VAL_ 2365473278 RunningLightCommand 3 "DonTCare" 2 "Reserved" 1 "Activate" 0 "Deactivate" ;
VAL_ 2365473278 AlternateBeamHeadLightCommand 3 "DonTCare" 2 "Reserved" 1 "Activate" 0 "Deactivate" ;
VAL_ 2365473278 LowBeamHeadLightCommand 3 "DonTCare" 2 "Reserved" 1 "Activate" 0 "Deactivate" ;
VAL_ 2365473278 HighBeamHeadLightCommand 3 "DonTCare" 2 "Reserved" 1 "Activate" 0 "Deactivate" ;
VAL_ 2365473278 TractorFrontFogLightsCommand 3 "DonTCare" 2 "Reserved" 1 "Activate" 0 "Deactivate" ;
VAL_ 2365473278 RotatingBeaconLightCommand 3 "DonTCare" 2 "Reserved" 1 "Activate" 0 "Deactivate" ;
VAL_ 2365473278 RightTurnSignalLightsCommand 3 "DonTCare" 2 "Reserved" 1 "Activate" 0 "Deactivate" ;
VAL_ 2365473278 LeftTurnSignalLightsCommand 3 "DonTCare" 2 "Reserved" 1 "Activate" 0 "Deactivate" ;
VAL_ 2365473278 BackUpLightandAlarmHornCommand 3 "DonTCare" 2 "Reserved" 1 "Activate" 0 "Deactivate" ;
VAL_ 2365473278 CenterStopLightCommand 3 "DonTCare" 2 "Reserved" 1 "Activate" 0 "Deactivate" ;
VAL_ 2365473278 RightStopLightCommand 3 "DonTCare" 2 "Reserved" 1 "Activate" 0 "Deactivate" ;
VAL_ 2365473278 LeftStopLightCommand 3 "DonTCare" 2 "Reserved" 1 "Activate" 0 "Deactivate" ;
VAL_ 2365473278 ImplementClearanceLightCommand 3 "DonTCare" 2 "Reserved" 1 "Activate" 0 "Deactivate" ;
VAL_ 2365473278 TractorClearanceLightCommand 3 "DonTCare" 2 "Reserved" 1 "Activate" 0 "Deactivate" ;
VAL_ 2365473278 ImplementMarkerLightCommand 3 "DonTCare" 2 "Reserved" 1 "Activate" 0 "Deactivate" ;
VAL_ 2365473278 TractorMarkerLightCommand 3 "DonTCare" 2 "Reserved" 1 "Activate" 0 "Deactivate" ;
VAL_ 2365473278 RearFogLightCommand 3 "DonTCare" 2 "Reserved" 1 "Activate" 0 "Deactivate" ;
VAL_ 2365473278 TrtrUndrsdMntdWrkLghtsCmmnd 3 "DonTCare" 2 "Reserved" 1 "Activate" 0 "Deactivate" ;
VAL_ 2365473278 TrtrRrLwMntdWrkLghtsCmmnd 3 "DonTCare" 2 "Reserved" 1 "Activate" 0 "Deactivate" ;
VAL_ 2365473278 TrtrRrHghMntdWrkLghtsCmmnd 3 "DonTCare" 2 "Reserved" 1 "Activate" 0 "Deactivate" ;
VAL_ 2365473278 TrtrSdLwMntdWrkLghtsCmmnd 3 "DonTCare" 2 "Reserved" 1 "Activate" 0 "Deactivate" ;
VAL_ 2365473278 TrtrSdHghMntdWrkLghtsCmmnd 3 "DonTCare" 2 "Reserved" 1 "Activate" 0 "Deactivate" ;
VAL_ 2365473278 TrtrFrntLwMntdWrkLghtsCmmnd 3 "DonTCare" 2 "Reserved" 1 "Activate" 0 "Deactivate" ;
VAL_ 2365473278 TrtrFrntHghMntdWrkLghtsCmmnd 3 "DonTCare" 2 "Reserved" 1 "Activate" 0 "Deactivate" ;
VAL_ 2365473278 ImplementOEMOption2LightCommand 3 "DonTCare" 2 "Reserved" 1 "Activate" 0 "Deactivate" ;
VAL_ 2365473278 ImplementOEMOption1LightCommand 3 "DonTCare" 2 "Reserved" 1 "Activate" 0 "Deactivate" ;
VAL_ 2365473278 ImplmntRghtFngWrkLghtCmmnd 3 "DonTCare" 2 "Reserved" 1 "Activate" 0 "Deactivate" ;
VAL_ 2365473278 ImplmntLftFrwrdWrkLghtCmmnd 3 "DonTCare" 2 "Reserved" 1 "Activate" 0 "Deactivate" ;
VAL_ 2365473278 LightingDataRequestCommand 3 "DonTCare" 2 "Reserved" 1 "Activate" 0 "Deactivate" ;
VAL_ 2365473278 ImplmntRghtFrwrdWrkLghtCmmnd 3 "DonTCare" 2 "Reserved" 1 "Activate" 0 "Deactivate" ;
VAL_ 2365473278 ImplmntLftFngWrkLghtCmmnd 3 "DonTCare" 2 "Reserved" 1 "Activate" 0 "Deactivate" ;
VAL_ 2365473278 ImplementRearWorkLightCommand 3 "DonTCare" 2 "Reserved" 1 "Activate" 0 "Deactivate" ;
VAL_ 2365478910 EltrnShkAsrrCntrlMdFrntAxl 3 "NotAvailable" 2 "Error" 1 "NormalOperationDampersActive" 0 "NormalOperationDampersPassive" ;
VAL_ 2365478910 EltrnShkAsrrCntrlMdRrAxl 3 "NotAvailable" 2 "Error" 1 "NormalOperationDampersActive" 0 "NormalOperationDampersPassive" ;
VAL_ 2365478910 EltrnShkAsrrCntrlMdLftTgAxl 3 "NotAvailable" 2 "Error" 1 "NormalOperationDampersActive" 0 "NormalOperationDampersPassive" ;
VAL_ 2365479678 LoweringControlModeFrontAxle 3 "NotAvailable" 2 "Error" 1 "LoweringActive" 0 "LoweringNotActive" ;
VAL_ 2365479678 LoweringControlModeRearAxle 3 "NotAvailable" 2 "Error" 1 "LoweringActive" 0 "LoweringNotActive" ;
VAL_ 2365479678 LiftingControlModeFrontAxle 3 "NotAvailable" 2 "Error" 1 "LiftingActive" 0 "LiftingNotActive" ;
VAL_ 2365479678 LiftingControlModeRearAxle 3 "NotAvailable" 2 "Error" 1 "LiftingActive" 0 "LiftingNotActive" ;
VAL_ 2365479678 LevelControlMode 11 "1101NotDefined" 10 "AtmtcArSuspensionCtrlProhibited" 15 "NotAvailable" 14 "Error" 9 "AirSuspensionCtrlProhibited" 8 "ExhstngBllwFnctnIBllwsArExhstdT" 7 "TractionHelpLoadReduce" 6 "OptmmTrctn2IPrssAtThDrvnAxlIsCt" 5 "OptmmTrctn1IPrssAtThDrvnAxlIsCt" 4 "PrssRt2IRtBtwnThPrssrsAtThDrvnA" 3 "PrssRt1IRtBtwnThPrssrsAtThDrvnA" 2 "LdFxngIDrvnAxlnIsLddTAVlDfndByT" 1 "TrctnHlpIDrvnAxlIsLddTAMxVlGvnB" 0 "NrmlOprtnISystmPrfrmsAPrCtrlOfT" ;
VAL_ 2365479678 LiftAxle1Position 3 "NotAvailable" 2 "Error" 1 "LiftAxlePosUp_TagAxleUnladen" 0 "LiftAxlePosDown_TagAxleLaden" ;
VAL_ 2365479678 LiftAxle2Position 3 "NotAvailable" 2 "Error" 1 "LiftAxlePosUp_TagAxleUnladen" 0 "LiftAxlePosDown_TagAxleLaden" ;
VAL_ 2365479678 SuspensionRemoteControl1 3 "NotAvailable" 2 "Error" 1 "Active" 0 "NotActive" ;
VAL_ 2365479678 SuspensionRemotecontrol2 3 "NotAvailable" 2 "Error" 1 "Active" 0 "NotActive" ;
VAL_ 2365479678 AllwLvlCntrlDrngBrkngStts 3 "DonTCare_TakeNoAction" 2 "Reserved" 1 "Activate" 0 "Deactivate" ;
VAL_ 2365479678 SpdDpndntLvlCntrlStts 3 "DonTCare_TakeNoAction" 2 "Reserved" 1 "Active" 0 "Inactive" ;
VAL_ 2365479678 SspnsnCntrlRfslInfrmtn 15 "NotAvailable" 14 "Error" 8 "1101NotDefined" 7 "RqedLevelNotAvailable" 6 "GnrlRjctINSpcifiedReasonApplies" 5 "BelowSpeedLimit" 4 "AboveSpeedLimit" 3 "BogieDiffNotLocked" 2 "WouldExceedAxleLoadLimit" 1 "AxleLoadLimitReached" 0 "ActualRqNotRefused" ;
